VERSION ""

NS_ :

BS_:

BU_: TCU_TORQUE_CONVERTER HYDRONIC AFSS LOGBOX TCU_GWS500 TCU_RET DIAG_TOOL CTIS BC ECM_0x00 TCU ALTERNATOR CP6 CP10 _TESTER _TEMPLATE_RUx
VAL_TABLE_ HeaterWaterTemp 255 "NOT AVAILABLE" 254 "ERROR" ;
VAL_TABLE_ ___spare___ 3 "_SPARE_3" 2 "_SPARE_2" 1 "_SPARE_1" 0 "_SPARE_0" ;

BO_ 3221225472 VECTOR__INDEPENDENT_SIG_MSG: 0 Vector__XXX
 SG_ Dummy_ETC6 : 0|64@1- (1,0) [0|0] "" Vector__XXX
 SG_ Dummy_ETC7 : 0|64@1- (1,0) [0|0] "" Vector__XXX
 SG_ Dummy_ETC5 : 0|64@1- (1,0) [0|0] "" Vector__XXX
 SG_ Dummy_ETC4 : 0|64@1- (1,0) [0|0] "" Vector__XXX
 SG_ Dummy_ETC3 : 0|64@1- (1,0) [0|0] "" Vector__XXX
 SG_ Dummy_ETC2 : 0|64@1- (1,0) [0|0] "" Vector__XXX
 SG_ Dummy_ETC1 : 0|64@1- (1,0) [0|0] "" Vector__XXX
 SG_ SPN10_Low : 0|16@1+ (1,0) [0|65536] "-" Vector__XXX
 SG_ SPN9_Low : 0|16@1+ (1,0) [0|65536] "-" Vector__XXX
 SG_ SPN8_Low : 0|16@1+ (1,0) [0|65536] "-" Vector__XXX
 SG_ SPN7_Low : 0|16@1+ (1,0) [0|65536] "-" Vector__XXX
 SG_ SPN6_Low : 0|16@1+ (1,0) [0|65536] "-" Vector__XXX
 SG_ SPN5_Low : 0|16@1+ (1,0) [0|65536] "-" Vector__XXX
 SG_ SPN4_Low : 0|16@1+ (1,0) [0|65536] "-" Vector__XXX
 SG_ SPN3_Low : 0|16@1+ (1,0) [0|65536] "-" Vector__XXX
 SG_ SPN2_Low : 0|16@1+ (1,0) [0|65536] "-" Vector__XXX
 SG_ FailureModeIdentifier10 : 0|5@1+ (1,0) [0|31] "-" Vector__XXX
 SG_ FailureModeIdentifier9 : 0|5@1+ (1,0) [0|31] "-" Vector__XXX
 SG_ FailureModeIdentifier8 : 0|5@1+ (1,0) [0|31] "-" Vector__XXX
 SG_ FailureModeIdentifier7 : 0|5@1+ (1,0) [0|31] "-" Vector__XXX
 SG_ FailureModeIdentifier6 : 0|5@1+ (1,0) [0|31] "-" Vector__XXX
 SG_ FailureModeIdentifier5 : 0|5@1+ (1,0) [0|31] "-" Vector__XXX
 SG_ FailureModeIdentifier4 : 0|5@1+ (1,0) [0|31] "-" Vector__XXX
 SG_ FailureModeIdentifier3 : 0|5@1+ (1,0) [0|31] "-" Vector__XXX
 SG_ FlashRedStopLamp : 0|2@1+ (1,0) [0|3] "-" Vector__XXX
 SG_ FlashProtectLamp : 0|2@1+ (1,0) [0|3] "-" Vector__XXX
 SG_ FlashMalfuncIndicatorLamp : 0|2@1+ (1,0) [0|3] "-" Vector__XXX
 SG_ FlashAmberWarningLamp : 0|2@1+ (1,0) [0|3] "-" Vector__XXX
 SG_ MalfunctionIndicatorLampStatus : 0|2@1+ (1,0) [0|3] "-" Vector__XXX
 SG_ AmberWarningLampStatus : 0|2@1+ (1,0) [0|3] "-" Vector__XXX
 SG_ OccurenceCount1 : 0|7@1+ (1,0) [0|126] "-" Vector__XXX
 SG_ SPNConversionMethod1 : 0|1@1+ (1,0) [0|1] "-" Vector__XXX
 SG_ FailureModeIdentifier1 : 0|5@1+ (1,0) [0|31] "-" Vector__XXX
 SG_ SPN1_Low : 0|16@1+ (1,0) [0|65536] "-" Vector__XXX
 SG_ RedStopLampState : 0|2@1+ (1,0) [0|3] "-" Vector__XXX
 SG_ ProtectLampStatus : 0|2@1+ (1,0) [0|3] "-" Vector__XXX
 SG_ FailureModeIdentifier2 : 0|5@1+ (1,0) [0|31] "-" Vector__XXX
 SG_ SPNConversionMethod10 : 0|1@1+ (1,0) [0|1] "-" Vector__XXX
 SG_ SPNConversionMethod9 : 0|1@1+ (1,0) [0|1] "-" Vector__XXX
 SG_ SPNConversionMethod8 : 0|1@1+ (1,0) [0|1] "-" Vector__XXX
 SG_ SPNConversionMethod7 : 0|1@1+ (1,0) [0|1] "-" Vector__XXX
 SG_ SPNConversionMethod6 : 0|1@1+ (1,0) [0|1] "-" Vector__XXX
 SG_ SPNConversionMethod5 : 0|1@1+ (1,0) [0|1] "-" Vector__XXX
 SG_ SPNConversionMethod4 : 0|1@1+ (1,0) [0|1] "-" Vector__XXX
 SG_ SPNConversionMethod3 : 0|1@1+ (1,0) [0|1] "-" Vector__XXX
 SG_ SPNConversionMethod2 : 0|1@1+ (1,0) [0|1] "-" Vector__XXX
 SG_ OccurenceCount10 : 0|7@1+ (1,0) [0|126] "-" Vector__XXX
 SG_ OccurenceCount9 : 0|7@1+ (1,0) [0|126] "-" Vector__XXX
 SG_ OccurenceCount8 : 0|7@1+ (1,0) [0|126] "-" Vector__XXX
 SG_ OccurenceCount7 : 0|7@1+ (1,0) [0|126] "-" Vector__XXX
 SG_ OccurenceCount6 : 0|7@1+ (1,0) [0|126] "-" Vector__XXX
 SG_ OccurenceCount5 : 0|7@1+ (1,0) [0|126] "-" Vector__XXX
 SG_ OccurenceCount4 : 0|7@1+ (1,0) [0|126] "-" Vector__XXX
 SG_ OccurenceCount3 : 0|7@1+ (1,0) [0|126] "-" Vector__XXX
 SG_ OccurenceCount2 : 0|7@1+ (1,0) [0|126] "-" Vector__XXX
 SG_ SPN10_High : 0|3@1+ (1,0) [0|7] "-" Vector__XXX
 SG_ SPN9_High : 0|3@1+ (1,0) [0|7] "-" Vector__XXX
 SG_ SPN8_High : 0|3@1+ (1,0) [0|7] "-" Vector__XXX
 SG_ SPN7_High : 0|3@1+ (1,0) [0|7] "-" Vector__XXX
 SG_ SPN6_High : 0|3@1+ (1,0) [0|7] "-" Vector__XXX
 SG_ SPN5_High : 0|3@1+ (1,0) [0|7] "-" Vector__XXX
 SG_ SPN4_High : 0|3@1+ (1,0) [0|7] "-" Vector__XXX
 SG_ SPN3_High : 0|3@1+ (1,0) [0|7] "-" Vector__XXX
 SG_ SPN2_High : 0|3@1+ (1,0) [0|7] "-" Vector__XXX
 SG_ SPN1_High : 0|3@1+ (1,0) [0|7] "-" Vector__XXX
 SG_ Dummy_ECM7 : 0|64@1- (1,0) [0|0] "" Vector__XXX
 SG_ Dummy_ECM6 : 0|64@1- (1,0) [0|0] "" Vector__XXX
 SG_ Dummy_ECM5 : 0|64@1- (1,0) [0|0] "" Vector__XXX
 SG_ Dummy_ECM4 : 0|64@1- (1,0) [0|0] "" Vector__XXX
 SG_ Dummy_ECM3 : 0|64@1- (1,0) [0|0] "" Vector__XXX
 SG_ Dummy_ECM2 : 0|64@1- (1,0) [0|0] "" Vector__XXX
 SG_ Dummy_ECM1 : 0|64@1- (1,0) [0|0] "" Vector__XXX
 SG_ SPN10_Low : 0|16@1+ (1,0) [0|65536] "-" Vector__XXX
 SG_ SPN9_Low : 0|16@1+ (1,0) [0|65536] "-" Vector__XXX
 SG_ SPN8_Low : 0|16@1+ (1,0) [0|65536] "-" Vector__XXX
 SG_ SPN7_Low : 0|16@1+ (1,0) [0|65536] "-" Vector__XXX
 SG_ SPN6_Low : 0|16@1+ (1,0) [0|65536] "-" Vector__XXX
 SG_ SPN5_Low : 0|16@1+ (1,0) [0|65536] "-" Vector__XXX
 SG_ SPN4_Low : 0|16@1+ (1,0) [0|65536] "-" Vector__XXX
 SG_ SPN3_Low : 0|16@1+ (1,0) [0|65536] "-" Vector__XXX
 SG_ SPN2_Low : 0|16@1+ (1,0) [0|65536] "-" Vector__XXX
 SG_ FailureModeIdentifier10 : 0|5@1+ (1,0) [0|31] "-" Vector__XXX
 SG_ FailureModeIdentifier9 : 0|5@1+ (1,0) [0|31] "-" Vector__XXX
 SG_ FailureModeIdentifier8 : 0|5@1+ (1,0) [0|31] "-" Vector__XXX
 SG_ FailureModeIdentifier7 : 0|5@1+ (1,0) [0|31] "-" Vector__XXX
 SG_ FailureModeIdentifier6 : 0|5@1+ (1,0) [0|31] "-" Vector__XXX
 SG_ FailureModeIdentifier5 : 0|5@1+ (1,0) [0|31] "-" Vector__XXX
 SG_ FailureModeIdentifier4 : 0|5@1+ (1,0) [0|31] "-" Vector__XXX
 SG_ FailureModeIdentifier3 : 0|5@1+ (1,0) [0|31] "-" Vector__XXX
 SG_ FlashRedStopLamp : 0|2@1+ (1,0) [0|3] "-" Vector__XXX
 SG_ FlashProtectLamp : 0|2@1+ (1,0) [0|3] "-" Vector__XXX
 SG_ FlashMalfuncIndicatorLamp : 0|2@1+ (1,0) [0|3] "-" Vector__XXX
 SG_ FlashAmberWarningLamp : 0|2@1+ (1,0) [0|3] "-" Vector__XXX
 SG_ MalfunctionIndicatorLampStatus : 0|2@1+ (1,0) [0|3] "-" Vector__XXX
 SG_ AmberWarningLampStatus : 0|2@1+ (1,0) [0|3] "-" Vector__XXX
 SG_ OccurenceCount1 : 0|7@1+ (1,0) [0|126] "-" Vector__XXX
 SG_ SPNConversionMethod1 : 0|1@1+ (1,0) [0|1] "-" Vector__XXX
 SG_ FailureModeIdentifier1 : 0|5@1+ (1,0) [0|31] "-" Vector__XXX
 SG_ SPN1_Low : 0|16@1+ (1,0) [0|65536] "-" Vector__XXX
 SG_ RedStopLampState : 0|2@1+ (1,0) [0|3] "-" Vector__XXX
 SG_ ProtectLampStatus : 0|2@1+ (1,0) [0|3] "-" Vector__XXX
 SG_ FailureModeIdentifier2 : 0|5@1+ (1,0) [0|31] "-" Vector__XXX
 SG_ SPNConversionMethod10 : 0|1@1+ (1,0) [0|1] "-" Vector__XXX
 SG_ SPNConversionMethod9 : 0|1@1+ (1,0) [0|1] "-" Vector__XXX
 SG_ SPNConversionMethod8 : 0|1@1+ (1,0) [0|1] "-" Vector__XXX
 SG_ SPNConversionMethod7 : 0|1@1+ (1,0) [0|1] "-" Vector__XXX
 SG_ SPNConversionMethod6 : 0|1@1+ (1,0) [0|1] "-" Vector__XXX
 SG_ SPNConversionMethod5 : 0|1@1+ (1,0) [0|1] "-" Vector__XXX
 SG_ SPNConversionMethod4 : 0|1@1+ (1,0) [0|1] "-" Vector__XXX
 SG_ SPNConversionMethod3 : 0|1@1+ (1,0) [0|1] "-" Vector__XXX
 SG_ SPNConversionMethod2 : 0|1@1+ (1,0) [0|1] "-" Vector__XXX
 SG_ OccurenceCount10 : 0|7@1+ (1,0) [0|126] "-" Vector__XXX
 SG_ OccurenceCount9 : 0|7@1+ (1,0) [0|126] "-" Vector__XXX
 SG_ OccurenceCount8 : 0|7@1+ (1,0) [0|126] "-" Vector__XXX
 SG_ OccurenceCount7 : 0|7@1+ (1,0) [0|126] "-" Vector__XXX
 SG_ OccurenceCount6 : 0|7@1+ (1,0) [0|126] "-" Vector__XXX
 SG_ OccurenceCount5 : 0|7@1+ (1,0) [0|126] "-" Vector__XXX
 SG_ OccurenceCount4 : 0|7@1+ (1,0) [0|126] "-" Vector__XXX
 SG_ OccurenceCount3 : 0|7@1+ (1,0) [0|126] "-" Vector__XXX
 SG_ OccurenceCount2 : 0|7@1+ (1,0) [0|126] "-" Vector__XXX
 SG_ SPN10_High : 0|3@1+ (1,0) [0|7] "-" Vector__XXX
 SG_ SPN9_High : 0|3@1+ (1,0) [0|7] "-" Vector__XXX
 SG_ SPN8_High : 0|3@1+ (1,0) [0|7] "-" Vector__XXX
 SG_ SPN7_High : 0|3@1+ (1,0) [0|7] "-" Vector__XXX
 SG_ SPN6_High : 0|3@1+ (1,0) [0|7] "-" Vector__XXX
 SG_ SPN5_High : 0|3@1+ (1,0) [0|7] "-" Vector__XXX
 SG_ SPN4_High : 0|3@1+ (1,0) [0|7] "-" Vector__XXX
 SG_ SPN3_High : 0|3@1+ (1,0) [0|7] "-" Vector__XXX
 SG_ SPN2_High : 0|3@1+ (1,0) [0|7] "-" Vector__XXX
 SG_ SPN1_High : 0|3@1+ (1,0) [0|7] "-" Vector__XXX

BO_ 2565603072 _DM1_MULTI_ECM: 8 ECM_0x00
 SG_ Count : 0|8@1+ (1,0) [0|0] ""  BC
 SG_ SPN10_Low : 328|16@1+ (1,0) [0|65536] "-"  BC
 SG_ SPN9_Low : 296|16@1+ (1,0) [0|65536] "-"  BC
 SG_ SPN8_Low : 264|16@1+ (1,0) [0|65536] "-"  BC
 SG_ SPN7_Low : 232|16@1+ (1,0) [0|65536] "-"  BC
 SG_ SPN6_Low : 200|16@1+ (1,0) [0|65536] "-"  BC
 SG_ SPN5_Low : 152|16@1+ (1,0) [0|65536] "-"  BC
 SG_ SPN4_Low : 120|16@1+ (1,0) [0|65536] "-"  BC
 SG_ SPN3_Low : 88|16@1+ (1,0) [0|65536] "-"  BC
 SG_ SPN2_Low : 56|16@1+ (1,0) [0|65536] "-"  BC
 SG_ FailureModeIdentifier10 : 312|5@1+ (1,0) [0|31] "-"  BC
 SG_ FailureModeIdentifier9 : 280|5@1+ (1,0) [0|31] "-"  BC
 SG_ FailureModeIdentifier8 : 248|5@1+ (1,0) [0|31] "-"  BC
 SG_ FailureModeIdentifier7 : 216|5@1+ (1,0) [0|31] "-"  BC
 SG_ FailureModeIdentifier6 : 184|5@1+ (1,0) [0|31] "-"  BC
 SG_ FailureModeIdentifier5 : 168|5@1+ (1,0) [0|31] "-"  BC
 SG_ FailureModeIdentifier4 : 136|5@1+ (1,0) [0|31] "-"  BC
 SG_ FailureModeIdentifier3 : 104|5@1+ (1,0) [0|31] "-"  BC
 SG_ FlashRedStopLamp : 20|2@1+ (1,0) [0|3] "-"  BC
 SG_ FlashProtectLamp : 16|2@1+ (1,0) [0|3] "-"  BC
 SG_ FlashMalfuncIndicatorLamp : 22|2@1+ (1,0) [0|3] "-"  BC
 SG_ FlashAmberWarningLamp : 18|2@1+ (1,0) [0|3] "-"  BC
 SG_ MalfunctionIndicatorLampStatus : 14|2@1+ (1,0) [0|3] "-"  BC
 SG_ AmberWarningLampStatus : 10|2@1+ (1,0) [0|3] "-"  BC
 SG_ OccurenceCount1 : 48|7@1+ (1,0) [0|126] "-"  BC
 SG_ SPNConversionMethod1 : 55|1@1+ (1,0) [0|1] "-"  BC
 SG_ FailureModeIdentifier1 : 40|5@1+ (1,0) [0|31] "-"  BC
 SG_ SPN1_Low : 24|16@1+ (1,0) [0|65536] "-"  BC
 SG_ RedStopLampState : 12|2@1+ (1,0) [0|3] "-"  BC
 SG_ ProtectLampStatus : 8|2@1+ (1,0) [0|3] "-"  BC
 SG_ FailureModeIdentifier2 : 72|5@1+ (1,0) [0|31] "-"  BC
 SG_ SPNConversionMethod10 : 327|1@1+ (1,0) [0|1] "-"  BC
 SG_ SPNConversionMethod9 : 295|1@1+ (1,0) [0|1] "-"  BC
 SG_ SPNConversionMethod8 : 263|1@1+ (1,0) [0|1] "-"  BC
 SG_ SPNConversionMethod7 : 231|1@1+ (1,0) [0|1] "-"  BC
 SG_ SPNConversionMethod6 : 199|1@1+ (1,0) [0|1] "-"  BC
 SG_ SPNConversionMethod5 : 183|1@1+ (1,0) [0|1] "-"  BC
 SG_ SPNConversionMethod4 : 151|1@1+ (1,0) [0|1] "-"  BC
 SG_ SPNConversionMethod3 : 119|1@1+ (1,0) [0|1] "-"  BC
 SG_ SPNConversionMethod2 : 87|1@1+ (1,0) [0|1] "-"  BC
 SG_ OccurenceCount10 : 320|7@1+ (1,0) [0|126] "-"  BC
 SG_ OccurenceCount9 : 288|7@1+ (1,0) [0|126] "-"  BC
 SG_ OccurenceCount8 : 256|7@1+ (1,0) [0|126] "-"  BC
 SG_ OccurenceCount7 : 224|7@1+ (1,0) [0|126] "-"  BC
 SG_ OccurenceCount6 : 192|7@1+ (1,0) [0|126] "-"  BC
 SG_ OccurenceCount5 : 176|7@1+ (1,0) [0|126] "-"  BC
 SG_ OccurenceCount4 : 144|7@1+ (1,0) [0|126] "-"  BC
 SG_ OccurenceCount3 : 112|7@1+ (1,0) [0|126] "-"  BC
 SG_ OccurenceCount2 : 80|7@1+ (1,0) [0|126] "-"  BC
 SG_ SPN10_High : 317|3@1+ (1,0) [0|7] "-"  BC
 SG_ SPN9_High : 285|3@1+ (1,0) [0|7] "-"  BC
 SG_ SPN8_High : 253|3@1+ (1,0) [0|7] "-"  BC
 SG_ SPN7_High : 221|3@1+ (1,0) [0|7] "-"  BC
 SG_ SPN6_High : 189|3@1+ (1,0) [0|7] "-"  BC
 SG_ SPN5_High : 173|3@1+ (1,0) [0|7] "-"  BC
 SG_ SPN4_High : 141|3@1+ (1,0) [0|7] "-"  BC
 SG_ SPN3_High : 109|3@1+ (1,0) [0|7] "-"  BC
 SG_ SPN2_High : 77|3@1+ (1,0) [0|7] "-"  BC
 SG_ SPN1_High : 45|3@1+ (1,0) [0|7] "-"  BC

BO_ 2565603075 _DM1_MULTI_ETC: 8 TCU
 SG_ Count : 0|8@1+ (1,0) [0|0] ""  BC
 SG_ SPN10_Low : 328|16@1+ (1,0) [0|65536] "-"  BC
 SG_ SPN9_Low : 296|16@1+ (1,0) [0|65536] "-"  BC
 SG_ SPN8_Low : 264|16@1+ (1,0) [0|65536] "-"  BC
 SG_ SPN7_Low : 232|16@1+ (1,0) [0|65536] "-"  BC
 SG_ SPN6_Low : 200|16@1+ (1,0) [0|65536] "-"  BC
 SG_ SPN5_Low : 152|16@1+ (1,0) [0|65536] "-"  BC
 SG_ SPN4_Low : 120|16@1+ (1,0) [0|65536] "-"  BC
 SG_ SPN3_Low : 88|16@1+ (1,0) [0|65536] "-"  BC
 SG_ SPN2_Low : 56|16@1+ (1,0) [0|65536] "-"  BC
 SG_ FailureModeIdentifier10 : 312|5@1+ (1,0) [0|31] "-"  BC
 SG_ FailureModeIdentifier9 : 280|5@1+ (1,0) [0|31] "-"  BC
 SG_ FailureModeIdentifier8 : 248|5@1+ (1,0) [0|31] "-"  BC
 SG_ FailureModeIdentifier7 : 216|5@1+ (1,0) [0|31] "-"  BC
 SG_ FailureModeIdentifier6 : 184|5@1+ (1,0) [0|31] "-"  BC
 SG_ FailureModeIdentifier5 : 168|5@1+ (1,0) [0|31] "-"  BC
 SG_ FailureModeIdentifier4 : 136|5@1+ (1,0) [0|31] "-"  BC
 SG_ FailureModeIdentifier3 : 104|5@1+ (1,0) [0|31] "-"  BC
 SG_ FlashRedStopLamp : 20|2@1+ (1,0) [0|3] "-"  BC
 SG_ FlashProtectLamp : 16|2@1+ (1,0) [0|3] "-"  BC
 SG_ FlashMalfuncIndicatorLamp : 22|2@1+ (1,0) [0|3] "-"  BC
 SG_ FlashAmberWarningLamp : 18|2@1+ (1,0) [0|3] "-"  BC
 SG_ MalfunctionIndicatorLampStatus : 14|2@1+ (1,0) [0|3] "-"  BC
 SG_ AmberWarningLampStatus : 10|2@1+ (1,0) [0|3] "-"  BC
 SG_ OccurenceCount1 : 48|7@1+ (1,0) [0|126] "-"  BC
 SG_ SPNConversionMethod1 : 55|1@1+ (1,0) [0|1] "-"  BC
 SG_ FailureModeIdentifier1 : 40|5@1+ (1,0) [0|31] "-"  BC
 SG_ SPN1_Low : 24|16@1+ (1,0) [0|65536] "-"  BC
 SG_ RedStopLampState : 12|2@1+ (1,0) [0|3] "-"  BC
 SG_ ProtectLampStatus : 8|2@1+ (1,0) [0|3] "-"  BC
 SG_ FailureModeIdentifier2 : 72|5@1+ (1,0) [0|31] "-"  BC
 SG_ SPNConversionMethod10 : 327|1@1+ (1,0) [0|1] "-"  BC
 SG_ SPNConversionMethod9 : 295|1@1+ (1,0) [0|1] "-"  BC
 SG_ SPNConversionMethod8 : 263|1@1+ (1,0) [0|1] "-"  BC
 SG_ SPNConversionMethod7 : 231|1@1+ (1,0) [0|1] "-"  BC
 SG_ SPNConversionMethod6 : 199|1@1+ (1,0) [0|1] "-"  BC
 SG_ SPNConversionMethod5 : 183|1@1+ (1,0) [0|1] "-"  BC
 SG_ SPNConversionMethod4 : 151|1@1+ (1,0) [0|1] "-"  BC
 SG_ SPNConversionMethod3 : 119|1@1+ (1,0) [0|1] "-"  BC
 SG_ SPNConversionMethod2 : 87|1@1+ (1,0) [0|1] "-"  BC
 SG_ OccurenceCount10 : 320|7@1+ (1,0) [0|126] "-"  BC
 SG_ OccurenceCount9 : 288|7@1+ (1,0) [0|126] "-"  BC
 SG_ OccurenceCount8 : 256|7@1+ (1,0) [0|126] "-"  BC
 SG_ OccurenceCount7 : 224|7@1+ (1,0) [0|126] "-"  BC
 SG_ OccurenceCount6 : 192|7@1+ (1,0) [0|126] "-"  BC
 SG_ OccurenceCount5 : 176|7@1+ (1,0) [0|126] "-"  BC
 SG_ OccurenceCount4 : 144|7@1+ (1,0) [0|126] "-"  BC
 SG_ OccurenceCount3 : 112|7@1+ (1,0) [0|126] "-"  BC
 SG_ OccurenceCount2 : 80|7@1+ (1,0) [0|126] "-"  BC
 SG_ SPN10_High : 317|3@1+ (1,0) [0|7] "-"  BC
 SG_ SPN9_High : 285|3@1+ (1,0) [0|7] "-"  BC
 SG_ SPN8_High : 253|3@1+ (1,0) [0|7] "-"  BC
 SG_ SPN7_High : 221|3@1+ (1,0) [0|7] "-"  BC
 SG_ SPN6_High : 189|3@1+ (1,0) [0|7] "-"  BC
 SG_ SPN5_High : 173|3@1+ (1,0) [0|7] "-"  BC
 SG_ SPN4_High : 141|3@1+ (1,0) [0|7] "-"  BC
 SG_ SPN3_High : 109|3@1+ (1,0) [0|7] "-"  BC
 SG_ SPN2_High : 77|3@1+ (1,0) [0|7] "-"  BC
 SG_ SPN1_High : 45|3@1+ (1,0) [0|7] "-"  BC

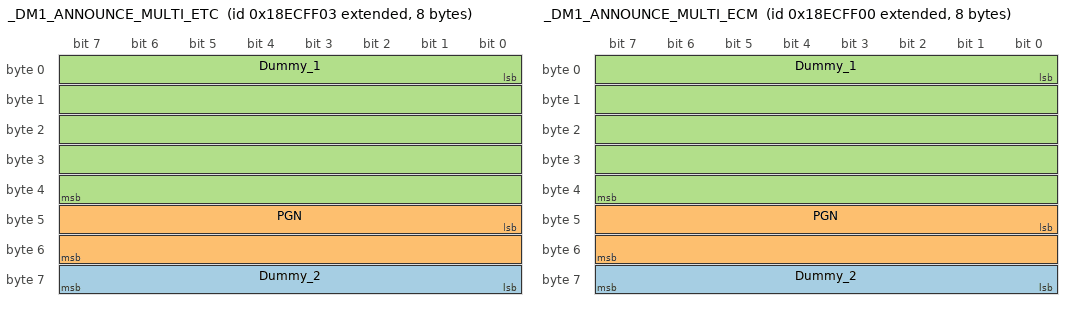
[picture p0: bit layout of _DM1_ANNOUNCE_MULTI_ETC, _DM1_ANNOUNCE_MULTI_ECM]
BO_ 2565668611 _DM1_ANNOUNCE_MULTI_ETC: 8 TCU
 SG_ Dummy_2 : 56|8@1- (1,0) [0|0] ""  BC
 SG_ PGN : 40|16@1- (1,0) [0|1] ""  BC
 SG_ Dummy_1 : 0|40@1- (1,0) [0|0] ""  BC

BO_ 2565668608 _DM1_ANNOUNCE_MULTI_ECM: 8 ECM_0x00
 SG_ Dummy_2 : 56|8@1- (1,0) [0|0] ""  BC
 SG_ PGN : 40|16@1- (1,0) [0|1] ""  BC
 SG_ Dummy_1 : 0|40@1- (1,0) [0|0] ""  BC

BO_ 2566834691 _DM1_ETC: 8 TCU
 SG_ SPN10_Low : 320|16@1+ (1,0) [0|65536] "-"  BC
 SG_ SPN9_Low : 288|16@1+ (1,0) [0|65536] "-"  BC
 SG_ SPN8_Low : 256|16@1+ (1,0) [0|65536] "-"  BC
 SG_ SPN7_Low : 224|16@1+ (1,0) [0|65536] "-"  BC
 SG_ SPN6_Low : 192|16@1+ (1,0) [0|65536] "-"  BC
 SG_ SPN5_Low : 144|16@1+ (1,0) [0|65536] "-"  BC
 SG_ SPN4_Low : 112|16@1+ (1,0) [0|65536] "-"  BC
 SG_ SPN3_Low : 80|16@1+ (1,0) [0|65536] "-"  BC
 SG_ SPN2_Low : 48|16@1+ (1,0) [0|65536] "-"  BC
 SG_ FailureModeIdentifier10 : 304|5@1+ (1,0) [0|31] "-"  BC
 SG_ FailureModeIdentifier9 : 272|5@1+ (1,0) [0|31] "-"  BC
 SG_ FailureModeIdentifier8 : 240|5@1+ (1,0) [0|31] "-"  BC
 SG_ FailureModeIdentifier7 : 208|5@1+ (1,0) [0|31] "-"  BC
 SG_ FailureModeIdentifier6 : 176|5@1+ (1,0) [0|31] "-"  BC
 SG_ FailureModeIdentifier5 : 160|5@1+ (1,0) [0|31] "-"  BC
 SG_ FailureModeIdentifier4 : 128|5@1+ (1,0) [0|31] "-"  BC
 SG_ FailureModeIdentifier3 : 96|5@1+ (1,0) [0|31] "-"  BC
 SG_ FlashRedStopLamp : 12|2@1+ (1,0) [0|3] "-"  BC
 SG_ FlashProtectLamp : 8|2@1+ (1,0) [0|3] "-"  BC
 SG_ FlashMalfuncIndicatorLamp : 14|2@1+ (1,0) [0|3] "-"  BC
 SG_ FlashAmberWarningLamp : 10|2@1+ (1,0) [0|3] "-"  BC
 SG_ MalfunctionIndicatorLampStatus : 6|2@1+ (1,0) [0|3] "-"  BC
 SG_ AmberWarningLampStatus : 2|2@1+ (1,0) [0|3] "-"  BC
 SG_ OccurenceCount1 : 40|7@1+ (1,0) [0|126] "-"  BC
 SG_ SPNConversionMethod1 : 47|1@1+ (1,0) [0|1] "-"  BC
 SG_ FailureModeIdentifier1 : 32|5@1+ (1,0) [0|31] "-"  BC
 SG_ SPN1_Low : 16|16@1+ (1,0) [0|65536] "-"  BC
 SG_ RedStopLampState : 4|2@1+ (1,0) [0|3] "-"  BC
 SG_ ProtectLampStatus : 0|2@1+ (1,0) [0|3] "-"  BC
 SG_ FailureModeIdentifier2 : 64|5@1+ (1,0) [0|31] "-"  BC
 SG_ SPNConversionMethod10 : 319|1@1+ (1,0) [0|1] "-"  BC
 SG_ SPNConversionMethod9 : 287|1@1+ (1,0) [0|1] "-"  BC
 SG_ SPNConversionMethod8 : 255|1@1+ (1,0) [0|1] "-"  BC
 SG_ SPNConversionMethod7 : 223|1@1+ (1,0) [0|1] "-"  BC
 SG_ SPNConversionMethod6 : 191|1@1+ (1,0) [0|1] "-"  BC
 SG_ SPNConversionMethod5 : 175|1@1+ (1,0) [0|1] "-"  BC
 SG_ SPNConversionMethod4 : 143|1@1+ (1,0) [0|1] "-"  BC
 SG_ SPNConversionMethod3 : 111|1@1+ (1,0) [0|1] "-"  BC
 SG_ SPNConversionMethod2 : 79|1@1+ (1,0) [0|1] "-"  BC
 SG_ OccurenceCount10 : 312|7@1+ (1,0) [0|126] "-"  BC
 SG_ OccurenceCount9 : 280|7@1+ (1,0) [0|126] "-"  BC
 SG_ OccurenceCount8 : 248|7@1+ (1,0) [0|126] "-"  BC
 SG_ OccurenceCount7 : 216|7@1+ (1,0) [0|126] "-"  BC
 SG_ OccurenceCount6 : 184|7@1+ (1,0) [0|126] "-"  BC
 SG_ OccurenceCount5 : 168|7@1+ (1,0) [0|126] "-"  BC
 SG_ OccurenceCount4 : 136|7@1+ (1,0) [0|126] "-"  BC
 SG_ OccurenceCount3 : 104|7@1+ (1,0) [0|126] "-"  BC
 SG_ OccurenceCount2 : 72|7@1+ (1,0) [0|126] "-"  BC
 SG_ SPN10_High : 309|3@1+ (1,0) [0|7] "-"  BC
 SG_ SPN9_High : 277|3@1+ (1,0) [0|7] "-"  BC
 SG_ SPN8_High : 245|3@1+ (1,0) [0|7] "-"  BC
 SG_ SPN7_High : 213|3@1+ (1,0) [0|7] "-"  BC
 SG_ SPN6_High : 181|3@1+ (1,0) [0|7] "-"  BC
 SG_ SPN5_High : 165|3@1+ (1,0) [0|7] "-"  BC
 SG_ SPN4_High : 133|3@1+ (1,0) [0|7] "-"  BC
 SG_ SPN3_High : 101|3@1+ (1,0) [0|7] "-"  BC
 SG_ SPN2_High : 69|3@1+ (1,0) [0|7] "-"  BC
 SG_ SPN1_High : 37|3@1+ (1,0) [0|7] "-"  BC

BO_ 2566834688 _DM1_ECM: 8 ECM_0x00
 SG_ SPN10_Low : 320|16@1+ (1,0) [0|65536] "-"  BC,LOGBOX
 SG_ SPN9_Low : 288|16@1+ (1,0) [0|65536] "-"  BC,LOGBOX
 SG_ SPN8_Low : 256|16@1+ (1,0) [0|65536] "-"  BC,LOGBOX
 SG_ SPN7_Low : 224|16@1+ (1,0) [0|65536] "-"  BC,LOGBOX
 SG_ SPN6_Low : 192|16@1+ (1,0) [0|65536] "-"  BC,LOGBOX
 SG_ SPN5_Low : 144|16@1+ (1,0) [0|65536] "-"  BC,LOGBOX
 SG_ SPN4_Low : 112|16@1+ (1,0) [0|65536] "-"  BC,LOGBOX
 SG_ SPN3_Low : 80|16@1+ (1,0) [0|65536] "-"  BC,LOGBOX
 SG_ SPN2_Low : 48|16@1+ (1,0) [0|65536] "-"  BC,LOGBOX
 SG_ FailureModeIdentifier10 : 304|5@1+ (1,0) [0|31] "-"  BC,LOGBOX
 SG_ FailureModeIdentifier9 : 272|5@1+ (1,0) [0|31] "-"  BC,LOGBOX
 SG_ FailureModeIdentifier8 : 240|5@1+ (1,0) [0|31] "-"  BC,LOGBOX
 SG_ FailureModeIdentifier7 : 208|5@1+ (1,0) [0|31] "-"  BC,LOGBOX
 SG_ FailureModeIdentifier6 : 176|5@1+ (1,0) [0|31] "-"  BC,LOGBOX
 SG_ FailureModeIdentifier5 : 160|5@1+ (1,0) [0|31] "-"  BC,LOGBOX
 SG_ FailureModeIdentifier4 : 128|5@1+ (1,0) [0|31] "-"  BC,LOGBOX
 SG_ FailureModeIdentifier3 : 96|5@1+ (1,0) [0|31] "-"  BC,LOGBOX
 SG_ FlashRedStopLamp : 12|2@1+ (1,0) [0|3] "-"  BC,LOGBOX
 SG_ FlashProtectLamp : 8|2@1+ (1,0) [0|3] "-"  BC,LOGBOX
 SG_ FlashMalfuncIndicatorLamp : 14|2@1+ (1,0) [0|3] "-"  BC,LOGBOX
 SG_ FlashAmberWarningLamp : 10|2@1+ (1,0) [0|3] "-"  BC,LOGBOX
 SG_ MalfunctionIndicatorLampStatus : 6|2@1+ (1,0) [0|3] "-"  BC,LOGBOX
 SG_ AmberWarningLampStatus : 2|2@1+ (1,0) [0|3] "-"  BC,LOGBOX
 SG_ OccurenceCount1 : 40|7@1+ (1,0) [0|126] "-"  BC,LOGBOX
 SG_ SPNConversionMethod1 : 47|1@1+ (1,0) [0|1] "-"  BC,LOGBOX
 SG_ FailureModeIdentifier1 : 32|5@1+ (1,0) [0|31] "-"  BC,LOGBOX
 SG_ SPN1_Low : 16|16@1+ (1,0) [0|65536] "-"  BC,LOGBOX
 SG_ RedStopLampState : 4|2@1+ (1,0) [0|3] "-"  BC,LOGBOX
 SG_ ProtectLampStatus : 0|2@1+ (1,0) [0|3] "-"  BC,LOGBOX
 SG_ FailureModeIdentifier2 : 64|5@1+ (1,0) [0|31] "-"  BC,LOGBOX
 SG_ SPNConversionMethod10 : 319|1@1+ (1,0) [0|1] "-"  BC,LOGBOX
 SG_ SPNConversionMethod9 : 287|1@1+ (1,0) [0|1] "-"  BC,LOGBOX
 SG_ SPNConversionMethod8 : 255|1@1+ (1,0) [0|1] "-"  BC,LOGBOX
 SG_ SPNConversionMethod7 : 223|1@1+ (1,0) [0|1] "-"  BC,LOGBOX
 SG_ SPNConversionMethod6 : 191|1@1+ (1,0) [0|1] "-"  BC,LOGBOX
 SG_ SPNConversionMethod5 : 175|1@1+ (1,0) [0|1] "-"  BC,LOGBOX
 SG_ SPNConversionMethod4 : 143|1@1+ (1,0) [0|1] "-"  BC,LOGBOX
 SG_ SPNConversionMethod3 : 111|1@1+ (1,0) [0|1] "-"  BC,LOGBOX
 SG_ SPNConversionMethod2 : 79|1@1+ (1,0) [0|1] "-"  BC,LOGBOX
 SG_ OccurenceCount10 : 312|7@1+ (1,0) [0|126] "-"  BC,LOGBOX
 SG_ OccurenceCount9 : 280|7@1+ (1,0) [0|126] "-"  BC,LOGBOX
 SG_ OccurenceCount8 : 248|7@1+ (1,0) [0|126] "-"  BC,LOGBOX
 SG_ OccurenceCount7 : 216|7@1+ (1,0) [0|126] "-"  BC,LOGBOX
 SG_ OccurenceCount6 : 184|7@1+ (1,0) [0|126] "-"  BC,LOGBOX
 SG_ OccurenceCount5 : 168|7@1+ (1,0) [0|126] "-"  BC,LOGBOX
 SG_ OccurenceCount4 : 136|7@1+ (1,0) [0|126] "-"  BC,LOGBOX
 SG_ OccurenceCount3 : 104|7@1+ (1,0) [0|126] "-"  BC,LOGBOX
 SG_ OccurenceCount2 : 72|7@1+ (1,0) [0|126] "-"  BC,LOGBOX
 SG_ SPN10_High : 309|3@1+ (1,0) [0|7] "-"  BC,LOGBOX
 SG_ SPN9_High : 277|3@1+ (1,0) [0|7] "-"  BC,LOGBOX
 SG_ SPN8_High : 245|3@1+ (1,0) [0|7] "-"  BC,LOGBOX
 SG_ SPN7_High : 213|3@1+ (1,0) [0|7] "-"  BC,LOGBOX
 SG_ SPN6_High : 181|3@1+ (1,0) [0|7] "-"  BC,LOGBOX
 SG_ SPN5_High : 165|3@1+ (1,0) [0|7] "-"  BC,LOGBOX
 SG_ SPN4_High : 133|3@1+ (1,0) [0|7] "-"  BC,LOGBOX
 SG_ SPN3_High : 101|3@1+ (1,0) [0|7] "-"  BC,LOGBOX
 SG_ SPN2_High : 69|3@1+ (1,0) [0|7] "-"  BC,LOGBOX
 SG_ SPN1_High : 37|3@1+ (1,0) [0|7] "-"  BC,LOGBOX

BO_ 2633934618 ALT_TEMPERATURES: 8 ALTERNATOR
 SG_ Alt_RegulatorTemperature : 24|8@1+ (1,-40) [-40|210] "°C"  LOGBOX
 SG_ Alt_InternalTemperature : 32|16@1+ (1,-40) [-40|210] "°C"  LOGBOX

BO_ 2566846234 ALT_VOLTAGE: 8 ALTERNATOR
 SG_ Alt_Voltage_1 : 48|16@1+ (0.05,0) [0|32] "Volt"  LOGBOX
 SG_ Alt_BatteryVoltage_1 : 16|16@1+ (0.05,0) [0|32] "Volt"  LOGBOX

BO_ 2566905882 ALT_PROPRIETARY_5: 8 ALTERNATOR
 SG_ Alt_SoftwareVersion : 48|8@1+ (1,0) [0|255] "-"  LOGBOX
 SG_ Alt_HardwareVersion : 32|8@1+ (1,0) [0|255] "-"  LOGBOX

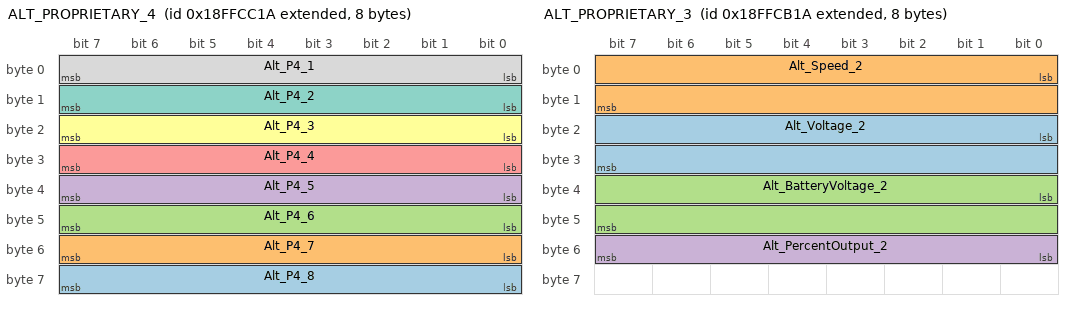
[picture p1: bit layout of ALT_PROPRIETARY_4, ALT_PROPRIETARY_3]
BO_ 2566900762 ALT_PROPRIETARY_4: 8 ALTERNATOR
 SG_ Alt_P4_8 : 56|8@1+ (1,0) [0|255] "-"  LOGBOX
 SG_ Alt_P4_7 : 48|8@1+ (1,0) [0|255] "-"  LOGBOX
 SG_ Alt_P4_6 : 40|8@1+ (1,0) [0|255] "-"  LOGBOX
 SG_ Alt_P4_5 : 32|8@1+ (1,0) [0|255] "-"  LOGBOX
 SG_ Alt_P4_4 : 24|8@1+ (1,0) [0|255] "-"  LOGBOX
 SG_ Alt_P4_3 : 16|8@1+ (1,0) [0|255] "-"  LOGBOX
 SG_ Alt_P4_2 : 8|8@1+ (1,0) [0|255] "-"  LOGBOX
 SG_ Alt_P4_1 : 0|8@1+ (1,0) [0|255] "-"  LOGBOX

BO_ 2566900506 ALT_PROPRIETARY_3: 8 ALTERNATOR
 SG_ Alt_Voltage_2 : 16|16@1+ (0.05,0) [0|3200] "Volt"  LOGBOX
 SG_ Alt_Speed_2 : 0|16@1+ (0.5,0) [0|32000] "rpm"  LOGBOX
 SG_ Alt_BatteryVoltage_2 : 32|16@1+ (0.05,0) [0|3200] "Volt"  LOGBOX
 SG_ Alt_PercentOutput_2 : 48|8@1+ (1,0) [0|100] "%"  LOGBOX

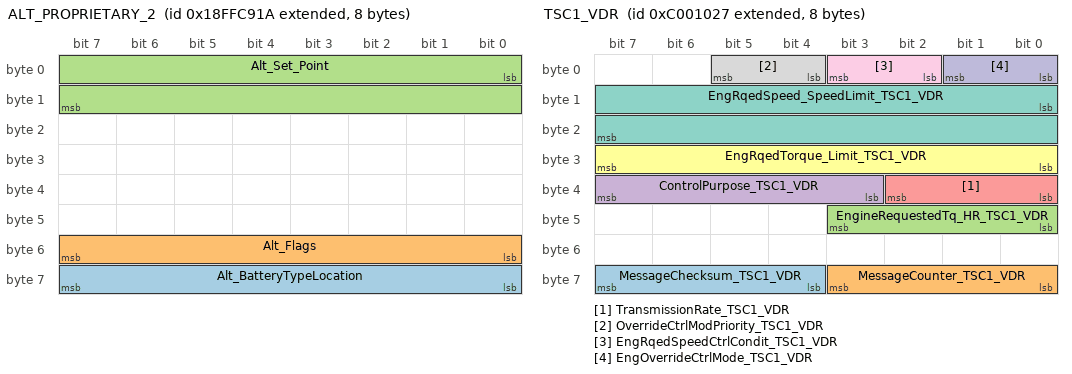
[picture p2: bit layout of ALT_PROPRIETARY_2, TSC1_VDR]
BO_ 2566899994 ALT_PROPRIETARY_2: 8 ALTERNATOR
 SG_ Alt_BatteryTypeLocation : 56|8@1+ (1,0) [1|4] "-"  LOGBOX
 SG_ Alt_Flags : 48|8@1+ (1,0) [0|255] "-"  LOGBOX
 SG_ Alt_Set_Point : 0|16@1+ (0.05,0) [0|0] "V"  LOGBOX

BO_ 2348814375 TSC1_VDR: 8 BC
 SG_ MessageChecksum_TSC1_VDR : 60|4@1+ (1,0) [0|15] "unit"  LOGBOX,TCU,TCU_RET
 SG_ MessageCounter_TSC1_VDR : 56|4@1+ (1,0) [0|15] "-"  LOGBOX,TCU,TCU_RET
 SG_ EngineRequestedTq_HR_TSC1_VDR : 40|4@1+ (1,0) [0|15] "-"  LOGBOX,TCU,TCU_RET
 SG_ ControlPurpose_TSC1_VDR : 35|5@1+ (1,0) [0|31] "-"  LOGBOX,TCU,TCU_RET
 SG_ TransmissionRate_TSC1_VDR : 32|3@1+ (1,0) [0|7] "-"  LOGBOX,TCU,TCU_RET
 SG_ EngRqedTorque_Limit_TSC1_VDR : 24|8@1+ (1,-125) [-125|125] "%"  LOGBOX,TCU,TCU_RET
 SG_ EngRqedSpeed_SpeedLimit_TSC1_VDR : 8|16@1+ (0.125,0) [0|8031.875] "rpm"  LOGBOX,TCU,TCU_RET
 SG_ OverrideCtrlModPriority_TSC1_VDR : 4|2@1+ (1,0) [0|3] "-"  LOGBOX,TCU,TCU_RET
 SG_ EngRqedSpeedCtrlCondit_TSC1_VDR : 2|2@1+ (1,0) [0|3] "-"  LOGBOX,TCU,TCU_RET
 SG_ EngOverrideCtrlMode_TSC1_VDR : 0|2@1+ (1,0) [0|3] "-"  LOGBOX,TCU,TCU_RET

BO_ 2566824960 ET2: 8 ECM_0x00
 SG_ EngineEcuTemp : 16|16@1+ (0.03125,-273) [-273|1734.96875] "-"  LOGBOX,BC,ECM_0x00

BO_ 2566848545 BC2EDC1: 8 BC
 SG_ VehicleSpeedLimit : 16|8@1+ (1,0) [0|250] "km/h"  LOGBOX,ECM_0x00

BO_ 2566809413 WTA_ClimateControlConfiguration: 8 HYDRONIC
 SG_ HeaterMaximumOutputPower : 0|16@1- (2,0) [0|131070] "W"  LOGBOX

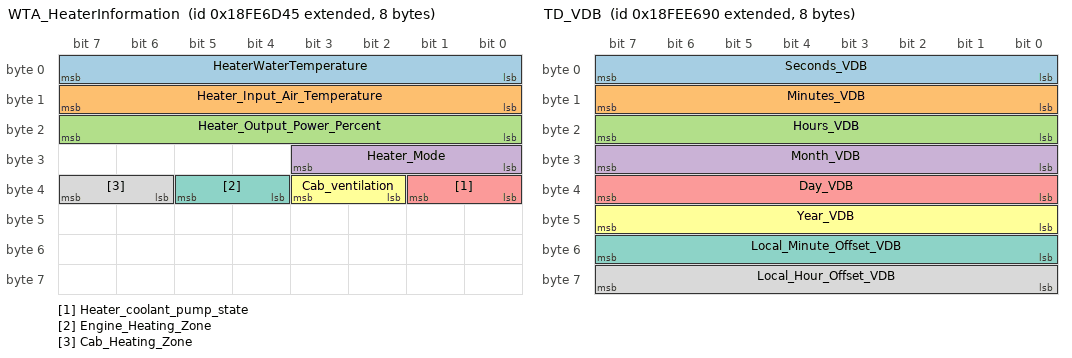
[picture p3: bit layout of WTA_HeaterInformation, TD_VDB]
BO_ 2566810949 WTA_HeaterInformation: 8 HYDRONIC
 SG_ HeaterWaterTemperature : 0|8@1+ (1,-40) [-40|210] "°C"  LOGBOX
 SG_ Heater_Input_Air_Temperature : 8|8@1+ (1,-40) [-40|210] "°C"  LOGBOX
 SG_ Heater_Output_Power_Percent : 16|8@1+ (0.4,0) [0|100] "%"  LOGBOX
 SG_ Heater_Mode : 24|4@1+ (1,0) [0|15] "-"  LOGBOX
 SG_ Heater_coolant_pump_state : 32|2@1+ (1,0) [0|3] "-"  LOGBOX
 SG_ Cab_ventilation : 34|2@1+ (1,0) [0|3] "-"  LOGBOX
 SG_ Engine_Heating_Zone : 36|2@1+ (1,0) [0|3] "-"  LOGBOX
 SG_ Cab_Heating_Zone : 38|2@1+ (1,0) [0|3] "-"  LOGBOX

BO_ 2566842000 TD_VDB: 8 LOGBOX
 SG_ Seconds_VDB : 0|8@1+ (0.25,0) [0|59.75] "s"  LOGBOX,BC,HYDRONIC
 SG_ Minutes_VDB : 8|8@1+ (1,0) [0|59] "mun"  LOGBOX,BC,HYDRONIC
 SG_ Hours_VDB : 16|8@1+ (1,0) [0|23] "-"  LOGBOX,BC,HYDRONIC
 SG_ Month_VDB : 24|8@1+ (1,0) [1|12] "-"  LOGBOX,BC,HYDRONIC
 SG_ Day_VDB : 32|8@1+ (0.25,0) [0.25|31.75] "-"  LOGBOX,BC,HYDRONIC
 SG_ Year_VDB : 40|8@1+ (1,1985) [1985|2235] "-"  LOGBOX,BC,HYDRONIC
 SG_ Local_Minute_Offset_VDB : 48|8@1+ (1,-125) [-59|59] "-"  LOGBOX,BC,HYDRONIC
 SG_ Local_Hour_Offset_VDB : 56|8@1+ (1,-125) [-23|23] "-"  LOGBOX,BC,HYDRONIC

BO_ 2558590749 AFSS2MUX2: 8 AFSS
 SG_ AFSS_Zone_Fault0 : 0|2@1+ (1,0) [0|3] "-"  BC,LOGBOX,CP10,CP6
 SG_ AFSS_Zone_Fault1 : 2|2@1+ (1,0) [0|3] "-"  BC,LOGBOX,CP10,CP6
 SG_ AFSS_Zone_Fault2 : 4|2@1+ (1,0) [0|3] "-"  BC,LOGBOX,CP10,CP6
 SG_ AFSS_Zone_Fault3 : 6|2@1+ (1,0) [0|3] "-"  BC,LOGBOX,CP10,CP6
 SG_ AFSS_Zone_Fire_Alarm0 : 8|2@1+ (1,0) [0|3] "-"  BC,LOGBOX,CP10,CP6
 SG_ AFSS_Zone_Fire_Alarm1 : 10|2@1+ (1,0) [0|3] "-"  BC,LOGBOX,CP10,CP6
 SG_ AFSS_Zone_Fire_Alarm2 : 12|2@1+ (1,0) [0|3] "-"  BC,LOGBOX,CP10,CP6
 SG_ AFSS_Zone_Fire_Alarm3 : 14|2@1+ (1,0) [0|3] "-"  BC,LOGBOX,CP10,CP6
 SG_ AFSS_Voltage_Fault : 16|4@1+ (1,0) [0|15] "-"  BC,LOGBOX,CP10,CP6
 SG_ AFSS_Internal_Fault : 20|4@1+ (1,0) [0|3] "-"  BC,LOGBOX,CP10,CP6
 SG_ AFSS_Config_Error : 24|2@1+ (1,0) [0|3] "-"  BC,LOGBOX,CP10,CP6
 SG_ AFSS_Zone_inhibited : 26|2@1+ (1,0) [0|3] "-"  BC,LOGBOX,CP10,CP6
 SG_ AFSS_Self_Test : 28|2@1+ (1,0) [0|3] "-"  BC,LOGBOX,CP10,CP6
 SG_ AFSS_ContrOut0 : 32|2@1+ (1,0) [0|3] "-"  BC,LOGBOX,CP10,CP6
 SG_ AFSS_ContrOut1 : 34|2@1+ (1,0) [0|3] "-"  BC,LOGBOX,CP10,CP6
 SG_ AFSS_ContrOut2 : 36|2@1+ (1,0) [0|3] "-"  BC,LOGBOX,CP10,CP6
 SG_ AFSS_ContrOut3 : 38|2@1+ (1,0) [0|3] "-"  BC,LOGBOX,CP10,CP6
 SG_ AFSS_ContrOut4 : 40|2@1+ (1,0) [0|3] "-"  BC,LOGBOX,CP10,CP6
 SG_ AFSS_ContrOut5 : 42|2@1+ (1,0) [0|3] "-"  BC,LOGBOX,CP10,CP6
 SG_ AFSS_ContrOut6 : 44|2@1+ (1,0) [0|3] "-"  BC,LOGBOX,CP10,CP6
 SG_ AFSS_ContrOut7 : 46|2@1+ (1,0) [0|3] "-"  BC,LOGBOX,CP10,CP6
 SG_ AFSS_ExtInp0 : 48|2@1+ (1,0) [0|3] "-"  BC,LOGBOX,CP10,CP6
 SG_ AFSS_ExtInp1 : 50|2@1+ (1,0) [0|3] "-"  BC,LOGBOX,CP10,CP6
 SG_ AFSS_ExtInp2 : 52|2@1+ (1,0) [0|3] "-"  BC,LOGBOX,CP10,CP6
 SG_ AFSS_ExtInp3 : 54|2@1+ (1,0) [0|3] "-"  BC,LOGBOX,CP10,CP6
 SG_ AFSS_ExtInp4 : 56|2@1+ (1,0) [0|3] "-"  BC,LOGBOX,CP10,CP6
 SG_ AFSS_ExtInp5 : 58|2@1+ (1,0) [0|3] "-"  BC,LOGBOX,CP10,CP6
 SG_ AFSS_ExtInp6 : 60|2@1+ (1,0) [0|3] "-"  BC,LOGBOX,CP10,CP6
 SG_ AFSS_ExtInp7 : 62|2@1+ (1,0) [0|3] "-"  BC,LOGBOX,CP10,CP6
 SG_ AFSS_NotUsed : 30|2@1+ (1,0) [0|1] "-"  BC,LOGBOX,CP10,CP6

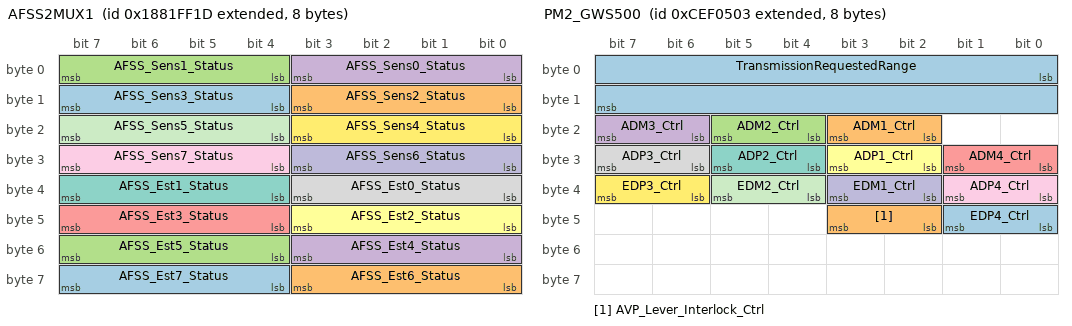
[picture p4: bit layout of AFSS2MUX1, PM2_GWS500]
BO_ 2558656285 AFSS2MUX1: 8 AFSS
 SG_ AFSS_Est7_Status : 60|4@1+ (1,0) [0|15] "-"  BC,LOGBOX,CP10,CP6
 SG_ AFSS_Est6_Status : 56|4@1+ (1,0) [0|15] "-"  BC,LOGBOX,CP10,CP6
 SG_ AFSS_Est5_Status : 52|4@1+ (1,0) [0|15] "-"  BC,LOGBOX,CP10,CP6
 SG_ AFSS_Est4_Status : 48|4@1+ (1,0) [0|15] "-"  BC,LOGBOX,CP10,CP6
 SG_ AFSS_Est3_Status : 44|4@1+ (1,0) [0|15] "-"  BC,LOGBOX,CP10,CP6
 SG_ AFSS_Est2_Status : 40|4@1+ (1,0) [0|15] "-"  BC,LOGBOX,CP10,CP6
 SG_ AFSS_Est1_Status : 36|4@1+ (1,0) [0|15] "-"  BC,LOGBOX,CP10,CP6
 SG_ AFSS_Est0_Status : 32|4@1+ (1,0) [0|15] "-"  BC,LOGBOX,CP10,CP6
 SG_ AFSS_Sens7_Status : 28|4@1+ (1,0) [0|15] "-"  BC,LOGBOX,CP10,CP6
 SG_ AFSS_Sens6_Status : 24|4@1+ (1,0) [0|15] "-"  BC,LOGBOX,CP10,CP6
 SG_ AFSS_Sens5_Status : 20|4@1+ (1,0) [0|15] "-"  BC,LOGBOX,CP10,CP6
 SG_ AFSS_Sens4_Status : 16|4@1+ (1,0) [0|15] "-"  BC,LOGBOX,CP10,CP6
 SG_ AFSS_Sens3_Status : 12|4@1+ (1,0) [0|15] "-"  BC,LOGBOX,CP10,CP6
 SG_ AFSS_Sens2_Status : 8|4@1+ (1,0) [0|15] "-"  BC,LOGBOX,CP10,CP6
 SG_ AFSS_Sens1_Status : 4|4@1+ (1,0) [0|15] "-"  BC,LOGBOX,CP10,CP6
 SG_ AFSS_Sens0_Status : 0|4@1+ (1,0) [0|15] "-"  BC,LOGBOX,CP10,CP6

BO_ 2364474627 PM2_GWS500: 8 TCU
 SG_ TransmissionRequestedRange : 0|16@1+ (1,0) [0|65536] "-"  LOGBOX,TCU_GWS500
 SG_ ADM1_Ctrl : 18|2@1+ (1,0) [0|3] "-"  LOGBOX,TCU_GWS500
 SG_ ADM2_Ctrl : 20|2@1+ (1,0) [0|3] "-"  LOGBOX,TCU_GWS500
 SG_ ADM3_Ctrl : 22|2@1+ (1,0) [0|3] "-"  LOGBOX,TCU_GWS500
 SG_ ADM4_Ctrl : 24|2@1+ (1,0) [0|3] "-"  LOGBOX,TCU_GWS500
 SG_ ADP1_Ctrl : 26|2@1+ (1,0) [0|3] "-"  LOGBOX,TCU_GWS500
 SG_ ADP2_Ctrl : 28|2@1+ (1,0) [0|3] "-"  LOGBOX,TCU_GWS500
 SG_ ADP3_Ctrl : 30|2@1+ (1,0) [0|3] "-"  LOGBOX,TCU_GWS500
 SG_ ADP4_Ctrl : 32|2@1+ (1,0) [0|3] "-"  LOGBOX,TCU_GWS500
 SG_ EDM1_Ctrl : 34|2@1+ (1,0) [0|3] "-"  LOGBOX,TCU_GWS500
 SG_ EDM2_Ctrl : 36|2@1+ (1,0) [0|3] "-"  LOGBOX,TCU_GWS500
 SG_ EDP3_Ctrl : 38|2@1+ (1,0) [0|3] "-"  LOGBOX,TCU_GWS500
 SG_ EDP4_Ctrl : 40|2@1+ (1,0) [0|3] "-"  LOGBOX,TCU_GWS500
 SG_ AVP_Lever_Interlock_Ctrl : 42|2@1+ (1,0) [0|3] "-"  LOGBOX,TCU_GWS500

CM_ "Vehicle data bus";
CM_ BU_ TCU_TORQUE_CONVERTER "Utilizzato solo per mappare correttamente i DM1 del convertitore di coppia";
CM_ BU_ HYDRONIC "Water To Air heater";
CM_ BU_ AFSS "AFSS system";
CM_ BU_ LOGBOX "Logbox";
CM_ BU_ TCU_GWS500 "Transmission Control Unit (Satellite)";
CM_ BU_ TCU_RET "Transmission Control Unit (Retarder)";
CM_ BU_ DIAG_TOOL "Strumento di diagnosi";
CM_ BU_ CTIS "Central Inflation Sistem";
CM_ BU_ BC "Body Computer";
CM_ BU_ ECM_0x00 "Engine Control Module ( #0)";
CM_ BU_ TCU "Transmission Control Unit (Main)";
CM_ BU_ ALTERNATOR "Alternatore Niehof";
CM_ BU_ CP6 "Control Panel 6''";
CM_ BU_ CP10 "Control Panel 10''";
CM_ BU_ _TESTER "Strumento di diagnosi per configurazione telecamere.
Potrà essere sostituito dal BC.";
CM_ BU_ _TEMPLATE_RUx "Template for Remote Unit (MUX slave)";
CM_ BO_ 3221225472 "This is a message for not used signals, created by Vector CANdb++ DBC OLE DB Provider.";
CM_ SG_ 3221225472 SPN10_Low "SPN #10 (Conversion Version 4)SPN #10 (Conversion Version 4)";
CM_ SG_ 3221225472 SPN9_Low "SPN #9 (Conversion Version 4)SPN #9 (Conversion Version 4)";
CM_ SG_ 3221225472 SPN8_Low "SPN #8 (Conversion Version 4)SPN #8 (Conversion Version 4)";
CM_ SG_ 3221225472 SPN7_Low "SPN #7 (Conversion Version 4)SPN #7 (Conversion Version 4)";
CM_ SG_ 3221225472 SPN6_Low "SPN #6 (Conversion Version 4)SPN #6 (Conversion Version 4)";
CM_ SG_ 3221225472 SPN5_Low "SPN #5 (Conversion Version 4)SPN #5 (Conversion Version 4)";
CM_ SG_ 3221225472 SPN4_Low "SPN #4 (Conversion Version 4)SPN #4 (Conversion Version 4)";
CM_ SG_ 3221225472 SPN3_Low "SPN #3 (Conversion Version 4)SPN #3 (Conversion Version 4)";
CM_ SG_ 3221225472 SPN2_Low "SPN #2 (Conversion Version 4)SPN #2 (Conversion Version 4)";
CM_ SG_ 3221225472 FailureModeIdentifier10 "The FMI defines the type of failure detected in the subsystem identified by an SPN.The FMI defines the type of failure detected in the subsystem identified by an SPN.";
CM_ SG_ 3221225472 FailureModeIdentifier9 "The FMI defines the type of failure detected in the subsystem identified by an SPN.The FMI defines the type of failure detected in the subsystem identified by an SPN.";
CM_ SG_ 3221225472 FailureModeIdentifier8 "The FMI defines the type of failure detected in the subsystem identified by an SPN.The FMI defines the type of failure detected in the subsystem identified by an SPN.";
CM_ SG_ 3221225472 FailureModeIdentifier7 "The FMI defines the type of failure detected in the subsystem identified by an SPN.The FMI defines the type of failure detected in the subsystem identified by an SPN.";
CM_ SG_ 3221225472 FailureModeIdentifier6 "The FMI defines the type of failure detected in the subsystem identified by an SPN.The FMI defines the type of failure detected in the subsystem identified by an SPN.";
CM_ SG_ 3221225472 FailureModeIdentifier5 "The FMI defines the type of failure detected in the subsystem identified by an SPN.The FMI defines the type of failure detected in the subsystem identified by an SPN.";
CM_ SG_ 3221225472 FailureModeIdentifier4 "The FMI defines the type of failure detected in the subsystem identified by an SPN.The FMI defines the type of failure detected in the subsystem identified by an SPN.";
CM_ SG_ 3221225472 FailureModeIdentifier3 "The FMI defines the type of failure detected in the subsystem identified by an SPN.The FMI defines the type of failure detected in the subsystem identified by an SPN.";
CM_ SG_ 3221225472 FlashRedStopLamp "This parameter provides the capability to flash the RSL (SPN 3039).This parameter provides the capability to flash the RSL (SPN 3039).";
CM_ SG_ 3221225472 FlashProtectLamp "This parameter provides the capability to flash the engine protect lamp (SPN 3041).This parameter provides the capability to flash the engine protect lamp (SPN 3041).";
CM_ SG_ 3221225472 FlashMalfuncIndicatorLamp "This parameter provides the capability to flash the MIL (SPN 3038).This parameter provides the capability to flash the MIL (SPN 3038).";
CM_ SG_ 3221225472 FlashAmberWarningLamp "This parameter provides the capability to flash the AWL (SPN 3040). This parameter provides the capability to flash the AWL (SPN 3040). ";
CM_ SG_ 3221225472 MalfunctionIndicatorLampStatus "A lamp used to relay only emissions-related trouble code information.A lamp used to relay only emissions-related trouble code information.";
CM_ SG_ 3221225472 AmberWarningLampStatus "This lamp is used to relay trouble code information that is reporting a problem with the vehicle system but the vehicle neednot be immediately stopped.This lamp is used to relay trouble code information that is reporting a problem with the vehicle system but the vehicle neednot be immediately stopped.";
CM_ SG_ 3221225472 OccurenceCount1 "The 7 bit occurence count field contains the number of times a fault has gone from active to previously active.The 7 bit occurence count field contains the number of times a fault has gone from active to previously active.";
CM_ SG_ 3221225472 SPNConversionMethod1 "SPN Conversion MethodSPN Conversion Method";
CM_ SG_ 3221225472 FailureModeIdentifier1 "The FMI defines the type of failure detected in the subsystem identified by an SPN.The FMI defines the type of failure detected in the subsystem identified by an SPN.";
CM_ SG_ 3221225472 SPN1_Low "SPN #1 (Conversion Version 4)SPN #1 (Conversion Version 4)";
CM_ SG_ 3221225472 RedStopLampState "This lamp is uesed to relay trouble code information that is of a severe enought condition that it warrants stopping the vehicle.This lamp is uesed to relay trouble code information that is of a severe enought condition that it warrants stopping the vehicle.";
CM_ SG_ 3221225472 ProtectLampStatus "This lamp is used to relay trouble code informatio that is reporting a problem with a vehicle system that is most probably not electronic subsystem related.This lamp is used to relay trouble code informatio that is reporting a problem with a vehicle system that is most probably not electronic subsystem related.";
CM_ SG_ 3221225472 FailureModeIdentifier2 "The FMI defines the type of failure detected in the subsystem identified by an SPN.The FMI defines the type of failure detected in the subsystem identified by an SPN.";
CM_ SG_ 3221225472 SPNConversionMethod10 "SPN Conversion MethodSPN Conversion Method";
CM_ SG_ 3221225472 SPNConversionMethod9 "SPN Conversion MethodSPN Conversion Method";
CM_ SG_ 3221225472 SPNConversionMethod8 "SPN Conversion MethodSPN Conversion Method";
CM_ SG_ 3221225472 SPNConversionMethod7 "SPN Conversion MethodSPN Conversion Method";
CM_ SG_ 3221225472 SPNConversionMethod6 "SPN Conversion MethodSPN Conversion Method";
CM_ SG_ 3221225472 SPNConversionMethod5 "SPN Conversion MethodSPN Conversion Method";
CM_ SG_ 3221225472 SPNConversionMethod4 "SPN Conversion MethodSPN Conversion Method";
CM_ SG_ 3221225472 SPNConversionMethod3 "SPN Conversion MethodSPN Conversion Method";
CM_ SG_ 3221225472 SPNConversionMethod2 "SPN Conversion MethodSPN Conversion Method";
CM_ SG_ 3221225472 OccurenceCount10 "The 7 bit occurence count field contains the number of times a fault has gone from active to previously active.The 7 bit occurence count field contains the number of times a fault has gone from active to previously active.";
CM_ SG_ 3221225472 OccurenceCount9 "The 7 bit occurence count field contains the number of times a fault has gone from active to previously active.The 7 bit occurence count field contains the number of times a fault has gone from active to previously active.";
CM_ SG_ 3221225472 OccurenceCount8 "The 7 bit occurence count field contains the number of times a fault has gone from active to previously active.The 7 bit occurence count field contains the number of times a fault has gone from active to previously active.";
CM_ SG_ 3221225472 OccurenceCount7 "The 7 bit occurence count field contains the number of times a fault has gone from active to previously active.The 7 bit occurence count field contains the number of times a fault has gone from active to previously active.";
CM_ SG_ 3221225472 OccurenceCount6 "The 7 bit occurence count field contains the number of times a fault has gone from active to previously active.The 7 bit occurence count field contains the number of times a fault has gone from active to previously active.";
CM_ SG_ 3221225472 OccurenceCount5 "The 7 bit occurence count field contains the number of times a fault has gone from active to previously active.The 7 bit occurence count field contains the number of times a fault has gone from active to previously active.";
CM_ SG_ 3221225472 OccurenceCount4 "The 7 bit occurence count field contains the number of times a fault has gone from active to previously active.The 7 bit occurence count field contains the number of times a fault has gone from active to previously active.";
CM_ SG_ 3221225472 OccurenceCount3 "The 7 bit occurence count field contains the number of times a fault has gone from active to previously active.The 7 bit occurence count field contains the number of times a fault has gone from active to previously active.";
CM_ SG_ 3221225472 OccurenceCount2 "The 7 bit occurence count field contains the number of times a fault has gone from active to previously active.The 7 bit occurence count field contains the number of times a fault has gone from active to previously active.";
CM_ SG_ 3221225472 SPN10_High "SPN #10 (Conversion Version 4)SPN #10 (Conversion Version 4)";
CM_ SG_ 3221225472 SPN9_High "SPN #9 (Conversion Version 4)SPN #9 (Conversion Version 4)";
CM_ SG_ 3221225472 SPN8_High "SPN #8 (Conversion Version 4)SPN #8 (Conversion Version 4)";
CM_ SG_ 3221225472 SPN7_High "SPN #7 (Conversion Version 4)SPN #7 (Conversion Version 4)";
CM_ SG_ 3221225472 SPN6_High "SPN #6 (Conversion Version 4)SPN #6 (Conversion Version 4)";
CM_ SG_ 3221225472 SPN5_High "SPN #5 (Conversion Version 4)SPN #5 (Conversion Version 4)";
CM_ SG_ 3221225472 SPN4_High "SPN #4 (Conversion Version 4)SPN #4 (Conversion Version 4)";
CM_ SG_ 3221225472 SPN3_High "SPN #3 (Conversion Version 4)SPN #3 (Conversion Version 4)";
CM_ SG_ 3221225472 SPN2_High "SPN #2 (Conversion Version 4)SPN #2 (Conversion Version 4)";
CM_ SG_ 3221225472 SPN1_High "SPN #1 (Conversion Version 4)SPN #1 (Conversion Version 4)";
CM_ BO_ 2565603072 "Active diagnostic trouble codes";
CM_ SG_ 2565603072 SPN10_Low "SPN #10 (Conversion Version 4)";
CM_ SG_ 2565603072 SPN9_Low "SPN #9 (Conversion Version 4)";
CM_ SG_ 2565603072 SPN8_Low "SPN #8 (Conversion Version 4)";
CM_ SG_ 2565603072 SPN7_Low "SPN #7 (Conversion Version 4)";
CM_ SG_ 2565603072 SPN6_Low "SPN #6 (Conversion Version 4)";
CM_ SG_ 2565603072 SPN5_Low "SPN #5 (Conversion Version 4)";
CM_ SG_ 2565603072 SPN4_Low "SPN #4 (Conversion Version 4)";
CM_ SG_ 2565603072 SPN3_Low "SPN #3 (Conversion Version 4)";
CM_ SG_ 2565603072 SPN2_Low "SPN #2 (Conversion Version 4)";
CM_ SG_ 2565603072 FailureModeIdentifier10 "The FMI defines the type of failure detected in the subsystem identified by an SPN.";
CM_ SG_ 2565603072 FailureModeIdentifier9 "The FMI defines the type of failure detected in the subsystem identified by an SPN.";
CM_ SG_ 2565603072 FailureModeIdentifier8 "The FMI defines the type of failure detected in the subsystem identified by an SPN.";
CM_ SG_ 2565603072 FailureModeIdentifier7 "The FMI defines the type of failure detected in the subsystem identified by an SPN.";
CM_ SG_ 2565603072 FailureModeIdentifier6 "The FMI defines the type of failure detected in the subsystem identified by an SPN.";
CM_ SG_ 2565603072 FailureModeIdentifier5 "The FMI defines the type of failure detected in the subsystem identified by an SPN.";
CM_ SG_ 2565603072 FailureModeIdentifier4 "The FMI defines the type of failure detected in the subsystem identified by an SPN.";
CM_ SG_ 2565603072 FailureModeIdentifier3 "The FMI defines the type of failure detected in the subsystem identified by an SPN.";
CM_ SG_ 2565603072 FlashRedStopLamp "This parameter provides the capability to flash the RSL (SPN 3039).";
CM_ SG_ 2565603072 FlashProtectLamp "This parameter provides the capability to flash the engine protect lamp (SPN 3041).";
CM_ SG_ 2565603072 FlashMalfuncIndicatorLamp "This parameter provides the capability to flash the MIL (SPN 3038).";
CM_ SG_ 2565603072 FlashAmberWarningLamp "This parameter provides the capability to flash the AWL (SPN 3040). ";
CM_ SG_ 2565603072 MalfunctionIndicatorLampStatus "A lamp used to relay only emissions-related trouble code information.";
CM_ SG_ 2565603072 AmberWarningLampStatus "This lamp is used to relay trouble code information that is reporting a problem with the vehicle system but the vehicle neednot be immediately stopped.";
CM_ SG_ 2565603072 OccurenceCount1 "The 7 bit occurence count field contains the number of times a fault has gone from active to previously active.";
CM_ SG_ 2565603072 SPNConversionMethod1 "SPN Conversion Method";
CM_ SG_ 2565603072 FailureModeIdentifier1 "The FMI defines the type of failure detected in the subsystem identified by an SPN.";
CM_ SG_ 2565603072 SPN1_Low "SPN #1 (Conversion Version 4)";
CM_ SG_ 2565603072 RedStopLampState "This lamp is uesed to relay trouble code information that is of a severe enought condition that it warrants stopping the vehicle.";
CM_ SG_ 2565603072 ProtectLampStatus "This lamp is used to relay trouble code informatio that is reporting a problem with a vehicle system that is most probably not electronic subsystem related.";
CM_ SG_ 2565603072 FailureModeIdentifier2 "The FMI defines the type of failure detected in the subsystem identified by an SPN.";
CM_ SG_ 2565603072 SPNConversionMethod10 "SPN Conversion Method";
CM_ SG_ 2565603072 SPNConversionMethod9 "SPN Conversion Method";
CM_ SG_ 2565603072 SPNConversionMethod8 "SPN Conversion Method";
CM_ SG_ 2565603072 SPNConversionMethod7 "SPN Conversion Method";
CM_ SG_ 2565603072 SPNConversionMethod6 "SPN Conversion Method";
CM_ SG_ 2565603072 SPNConversionMethod5 "SPN Conversion Method";
CM_ SG_ 2565603072 SPNConversionMethod4 "SPN Conversion Method";
CM_ SG_ 2565603072 SPNConversionMethod3 "SPN Conversion Method";
CM_ SG_ 2565603072 SPNConversionMethod2 "SPN Conversion Method";
CM_ SG_ 2565603072 OccurenceCount10 "The 7 bit occurence count field contains the number of times a fault has gone from active to previously active.";
CM_ SG_ 2565603072 OccurenceCount9 "The 7 bit occurence count field contains the number of times a fault has gone from active to previously active.";
CM_ SG_ 2565603072 OccurenceCount8 "The 7 bit occurence count field contains the number of times a fault has gone from active to previously active.";
CM_ SG_ 2565603072 OccurenceCount7 "The 7 bit occurence count field contains the number of times a fault has gone from active to previously active.";
CM_ SG_ 2565603072 OccurenceCount6 "The 7 bit occurence count field contains the number of times a fault has gone from active to previously active.";
CM_ SG_ 2565603072 OccurenceCount5 "The 7 bit occurence count field contains the number of times a fault has gone from active to previously active.";
CM_ SG_ 2565603072 OccurenceCount4 "The 7 bit occurence count field contains the number of times a fault has gone from active to previously active.";
CM_ SG_ 2565603072 OccurenceCount3 "The 7 bit occurence count field contains the number of times a fault has gone from active to previously active.";
CM_ SG_ 2565603072 OccurenceCount2 "The 7 bit occurence count field contains the number of times a fault has gone from active to previously active.";
CM_ SG_ 2565603072 SPN10_High "SPN #10 (Conversion Version 4)";
CM_ SG_ 2565603072 SPN9_High "SPN #9 (Conversion Version 4)";
CM_ SG_ 2565603072 SPN8_High "SPN #8 (Conversion Version 4)";
CM_ SG_ 2565603072 SPN7_High "SPN #7 (Conversion Version 4)";
CM_ SG_ 2565603072 SPN6_High "SPN #6 (Conversion Version 4)";
CM_ SG_ 2565603072 SPN5_High "SPN #5 (Conversion Version 4)";
CM_ SG_ 2565603072 SPN4_High "SPN #4 (Conversion Version 4)";
CM_ SG_ 2565603072 SPN3_High "SPN #3 (Conversion Version 4)";
CM_ SG_ 2565603072 SPN2_High "SPN #2 (Conversion Version 4)";
CM_ SG_ 2565603072 SPN1_High "SPN #1 (Conversion Version 4)";
CM_ BO_ 2565603075 "Active diagnostic trouble codes";
CM_ SG_ 2565603075 SPN10_Low "SPN #10 (Conversion Version 4)";
CM_ SG_ 2565603075 SPN9_Low "SPN #9 (Conversion Version 4)";
CM_ SG_ 2565603075 SPN8_Low "SPN #8 (Conversion Version 4)";
CM_ SG_ 2565603075 SPN7_Low "SPN #7 (Conversion Version 4)";
CM_ SG_ 2565603075 SPN6_Low "SPN #6 (Conversion Version 4)";
CM_ SG_ 2565603075 SPN5_Low "SPN #5 (Conversion Version 4)";
CM_ SG_ 2565603075 SPN4_Low "SPN #4 (Conversion Version 4)";
CM_ SG_ 2565603075 SPN3_Low "SPN #3 (Conversion Version 4)";
CM_ SG_ 2565603075 SPN2_Low "SPN #2 (Conversion Version 4)";
CM_ SG_ 2565603075 FailureModeIdentifier10 "The FMI defines the type of failure detected in the subsystem identified by an SPN.";
CM_ SG_ 2565603075 FailureModeIdentifier9 "The FMI defines the type of failure detected in the subsystem identified by an SPN.";
CM_ SG_ 2565603075 FailureModeIdentifier8 "The FMI defines the type of failure detected in the subsystem identified by an SPN.";
CM_ SG_ 2565603075 FailureModeIdentifier7 "The FMI defines the type of failure detected in the subsystem identified by an SPN.";
CM_ SG_ 2565603075 FailureModeIdentifier6 "The FMI defines the type of failure detected in the subsystem identified by an SPN.";
CM_ SG_ 2565603075 FailureModeIdentifier5 "The FMI defines the type of failure detected in the subsystem identified by an SPN.";
CM_ SG_ 2565603075 FailureModeIdentifier4 "The FMI defines the type of failure detected in the subsystem identified by an SPN.";
CM_ SG_ 2565603075 FailureModeIdentifier3 "The FMI defines the type of failure detected in the subsystem identified by an SPN.";
CM_ SG_ 2565603075 FlashRedStopLamp "This parameter provides the capability to flash the RSL (SPN 3039).";
CM_ SG_ 2565603075 FlashProtectLamp "This parameter provides the capability to flash the engine protect lamp (SPN 3041).";
CM_ SG_ 2565603075 FlashMalfuncIndicatorLamp "This parameter provides the capability to flash the MIL (SPN 3038).";
CM_ SG_ 2565603075 FlashAmberWarningLamp "This parameter provides the capability to flash the AWL (SPN 3040). ";
CM_ SG_ 2565603075 MalfunctionIndicatorLampStatus "A lamp used to relay only emissions-related trouble code information.";
CM_ SG_ 2565603075 AmberWarningLampStatus "This lamp is used to relay trouble code information that is reporting a problem with the vehicle system but the vehicle neednot be immediately stopped.";
CM_ SG_ 2565603075 OccurenceCount1 "The 7 bit occurence count field contains the number of times a fault has gone from active to previously active.";
CM_ SG_ 2565603075 SPNConversionMethod1 "SPN Conversion Method";
CM_ SG_ 2565603075 FailureModeIdentifier1 "The FMI defines the type of failure detected in the subsystem identified by an SPN.";
CM_ SG_ 2565603075 SPN1_Low "SPN #1 (Conversion Version 4)";
CM_ SG_ 2565603075 RedStopLampState "This lamp is uesed to relay trouble code information that is of a severe enought condition that it warrants stopping the vehicle.";
CM_ SG_ 2565603075 ProtectLampStatus "This lamp is used to relay trouble code informatio that is reporting a problem with a vehicle system that is most probably not electronic subsystem related.";
CM_ SG_ 2565603075 FailureModeIdentifier2 "The FMI defines the type of failure detected in the subsystem identified by an SPN.";
CM_ SG_ 2565603075 SPNConversionMethod10 "SPN Conversion Method";
CM_ SG_ 2565603075 SPNConversionMethod9 "SPN Conversion Method";
CM_ SG_ 2565603075 SPNConversionMethod8 "SPN Conversion Method";
CM_ SG_ 2565603075 SPNConversionMethod7 "SPN Conversion Method";
CM_ SG_ 2565603075 SPNConversionMethod6 "SPN Conversion Method";
CM_ SG_ 2565603075 SPNConversionMethod5 "SPN Conversion Method";
CM_ SG_ 2565603075 SPNConversionMethod4 "SPN Conversion Method";
CM_ SG_ 2565603075 SPNConversionMethod3 "SPN Conversion Method";
CM_ SG_ 2565603075 SPNConversionMethod2 "SPN Conversion Method";
CM_ SG_ 2565603075 OccurenceCount10 "The 7 bit occurence count field contains the number of times a fault has gone from active to previously active.";
CM_ SG_ 2565603075 OccurenceCount9 "The 7 bit occurence count field contains the number of times a fault has gone from active to previously active.";
CM_ SG_ 2565603075 OccurenceCount8 "The 7 bit occurence count field contains the number of times a fault has gone from active to previously active.";
CM_ SG_ 2565603075 OccurenceCount7 "The 7 bit occurence count field contains the number of times a fault has gone from active to previously active.";
CM_ SG_ 2565603075 OccurenceCount6 "The 7 bit occurence count field contains the number of times a fault has gone from active to previously active.";
CM_ SG_ 2565603075 OccurenceCount5 "The 7 bit occurence count field contains the number of times a fault has gone from active to previously active.";
CM_ SG_ 2565603075 OccurenceCount4 "The 7 bit occurence count field contains the number of times a fault has gone from active to previously active.";
CM_ SG_ 2565603075 OccurenceCount3 "The 7 bit occurence count field contains the number of times a fault has gone from active to previously active.";
CM_ SG_ 2565603075 OccurenceCount2 "The 7 bit occurence count field contains the number of times a fault has gone from active to previously active.";
CM_ SG_ 2565603075 SPN10_High "SPN #10 (Conversion Version 4)";
CM_ SG_ 2565603075 SPN9_High "SPN #9 (Conversion Version 4)";
CM_ SG_ 2565603075 SPN8_High "SPN #8 (Conversion Version 4)";
CM_ SG_ 2565603075 SPN7_High "SPN #7 (Conversion Version 4)";
CM_ SG_ 2565603075 SPN6_High "SPN #6 (Conversion Version 4)";
CM_ SG_ 2565603075 SPN5_High "SPN #5 (Conversion Version 4)";
CM_ SG_ 2565603075 SPN4_High "SPN #4 (Conversion Version 4)";
CM_ SG_ 2565603075 SPN3_High "SPN #3 (Conversion Version 4)";
CM_ SG_ 2565603075 SPN2_High "SPN #2 (Conversion Version 4)";
CM_ SG_ 2565603075 SPN1_High "SPN #1 (Conversion Version 4)";
CM_ BO_ 2565668611 "Active diagnostic trouble codes";
CM_ BO_ 2565668608 "Active diagnostic trouble codes";
CM_ BO_ 2566834691 "Active diagnostic trouble codes";
CM_ SG_ 2566834691 SPN10_Low "SPN #10 (Conversion Version 4)";
CM_ SG_ 2566834691 SPN9_Low "SPN #9 (Conversion Version 4)";
CM_ SG_ 2566834691 SPN8_Low "SPN #8 (Conversion Version 4)";
CM_ SG_ 2566834691 SPN7_Low "SPN #7 (Conversion Version 4)";
CM_ SG_ 2566834691 SPN6_Low "SPN #6 (Conversion Version 4)";
CM_ SG_ 2566834691 SPN5_Low "SPN #5 (Conversion Version 4)";
CM_ SG_ 2566834691 SPN4_Low "SPN #4 (Conversion Version 4)";
CM_ SG_ 2566834691 SPN3_Low "SPN #3 (Conversion Version 4)";
CM_ SG_ 2566834691 SPN2_Low "SPN #2 (Conversion Version 4)";
CM_ SG_ 2566834691 FailureModeIdentifier10 "The FMI defines the type of failure detected in the subsystem identified by an SPN.";
CM_ SG_ 2566834691 FailureModeIdentifier9 "The FMI defines the type of failure detected in the subsystem identified by an SPN.";
CM_ SG_ 2566834691 FailureModeIdentifier8 "The FMI defines the type of failure detected in the subsystem identified by an SPN.";
CM_ SG_ 2566834691 FailureModeIdentifier7 "The FMI defines the type of failure detected in the subsystem identified by an SPN.";
CM_ SG_ 2566834691 FailureModeIdentifier6 "The FMI defines the type of failure detected in the subsystem identified by an SPN.";
CM_ SG_ 2566834691 FailureModeIdentifier5 "The FMI defines the type of failure detected in the subsystem identified by an SPN.";
CM_ SG_ 2566834691 FailureModeIdentifier4 "The FMI defines the type of failure detected in the subsystem identified by an SPN.";
CM_ SG_ 2566834691 FailureModeIdentifier3 "The FMI defines the type of failure detected in the subsystem identified by an SPN.";
CM_ SG_ 2566834691 FlashRedStopLamp "This parameter provides the capability to flash the RSL (SPN 3039).";
CM_ SG_ 2566834691 FlashProtectLamp "This parameter provides the capability to flash the engine protect lamp (SPN 3041).";
CM_ SG_ 2566834691 FlashMalfuncIndicatorLamp "This parameter provides the capability to flash the MIL (SPN 3038).";
CM_ SG_ 2566834691 FlashAmberWarningLamp "This parameter provides the capability to flash the AWL (SPN 3040). ";
CM_ SG_ 2566834691 MalfunctionIndicatorLampStatus "A lamp used to relay only emissions-related trouble code information.";
CM_ SG_ 2566834691 AmberWarningLampStatus "This lamp is used to relay trouble code information that is reporting a problem with the vehicle system but the vehicle neednot be immediately stopped.";
CM_ SG_ 2566834691 OccurenceCount1 "The 7 bit occurence count field contains the number of times a fault has gone from active to previously active.";
CM_ SG_ 2566834691 SPNConversionMethod1 "SPN Conversion Method";
CM_ SG_ 2566834691 FailureModeIdentifier1 "The FMI defines the type of failure detected in the subsystem identified by an SPN.";
CM_ SG_ 2566834691 SPN1_Low "SPN #1 (Conversion Version 4)";
CM_ SG_ 2566834691 RedStopLampState "This lamp is uesed to relay trouble code information that is of a severe enought condition that it warrants stopping the vehicle.";
CM_ SG_ 2566834691 ProtectLampStatus "This lamp is used to relay trouble code informatio that is reporting a problem with a vehicle system that is most probably not electronic subsystem related.";
CM_ SG_ 2566834691 FailureModeIdentifier2 "The FMI defines the type of failure detected in the subsystem identified by an SPN.";
CM_ SG_ 2566834691 SPNConversionMethod10 "SPN Conversion Method";
CM_ SG_ 2566834691 SPNConversionMethod9 "SPN Conversion Method";
CM_ SG_ 2566834691 SPNConversionMethod8 "SPN Conversion Method";
CM_ SG_ 2566834691 SPNConversionMethod7 "SPN Conversion Method";
CM_ SG_ 2566834691 SPNConversionMethod6 "SPN Conversion Method";
CM_ SG_ 2566834691 SPNConversionMethod5 "SPN Conversion Method";
CM_ SG_ 2566834691 SPNConversionMethod4 "SPN Conversion Method";
CM_ SG_ 2566834691 SPNConversionMethod3 "SPN Conversion Method";
CM_ SG_ 2566834691 SPNConversionMethod2 "SPN Conversion Method";
CM_ SG_ 2566834691 OccurenceCount10 "The 7 bit occurence count field contains the number of times a fault has gone from active to previously active.";
CM_ SG_ 2566834691 OccurenceCount9 "The 7 bit occurence count field contains the number of times a fault has gone from active to previously active.";
CM_ SG_ 2566834691 OccurenceCount8 "The 7 bit occurence count field contains the number of times a fault has gone from active to previously active.";
CM_ SG_ 2566834691 OccurenceCount7 "The 7 bit occurence count field contains the number of times a fault has gone from active to previously active.";
CM_ SG_ 2566834691 OccurenceCount6 "The 7 bit occurence count field contains the number of times a fault has gone from active to previously active.";
CM_ SG_ 2566834691 OccurenceCount5 "The 7 bit occurence count field contains the number of times a fault has gone from active to previously active.";
CM_ SG_ 2566834691 OccurenceCount4 "The 7 bit occurence count field contains the number of times a fault has gone from active to previously active.";
CM_ SG_ 2566834691 OccurenceCount3 "The 7 bit occurence count field contains the number of times a fault has gone from active to previously active.";
CM_ SG_ 2566834691 OccurenceCount2 "The 7 bit occurence count field contains the number of times a fault has gone from active to previously active.";
CM_ SG_ 2566834691 SPN10_High "SPN #10 (Conversion Version 4)";
CM_ SG_ 2566834691 SPN9_High "SPN #9 (Conversion Version 4)";
CM_ SG_ 2566834691 SPN8_High "SPN #8 (Conversion Version 4)";
CM_ SG_ 2566834691 SPN7_High "SPN #7 (Conversion Version 4)";
CM_ SG_ 2566834691 SPN6_High "SPN #6 (Conversion Version 4)";
CM_ SG_ 2566834691 SPN5_High "SPN #5 (Conversion Version 4)";
CM_ SG_ 2566834691 SPN4_High "SPN #4 (Conversion Version 4)";
CM_ SG_ 2566834691 SPN3_High "SPN #3 (Conversion Version 4)";
CM_ SG_ 2566834691 SPN2_High "SPN #2 (Conversion Version 4)";
CM_ SG_ 2566834691 SPN1_High "SPN #1 (Conversion Version 4)";
CM_ BO_ 2566834688 "Active diagnostic trouble codes";
CM_ SG_ 2566834688 SPN10_Low "SPN #10 (Conversion Version 4)";
CM_ SG_ 2566834688 SPN9_Low "SPN #9 (Conversion Version 4)";
CM_ SG_ 2566834688 SPN8_Low "SPN #8 (Conversion Version 4)";
CM_ SG_ 2566834688 SPN7_Low "SPN #7 (Conversion Version 4)";
CM_ SG_ 2566834688 SPN6_Low "SPN #6 (Conversion Version 4)";
CM_ SG_ 2566834688 SPN5_Low "SPN #5 (Conversion Version 4)";
CM_ SG_ 2566834688 SPN4_Low "SPN #4 (Conversion Version 4)";
CM_ SG_ 2566834688 SPN3_Low "SPN #3 (Conversion Version 4)";
CM_ SG_ 2566834688 SPN2_Low "SPN #2 (Conversion Version 4)";
CM_ SG_ 2566834688 FailureModeIdentifier10 "The FMI defines the type of failure detected in the subsystem identified by an SPN.";
CM_ SG_ 2566834688 FailureModeIdentifier9 "The FMI defines the type of failure detected in the subsystem identified by an SPN.";
CM_ SG_ 2566834688 FailureModeIdentifier8 "The FMI defines the type of failure detected in the subsystem identified by an SPN.";
CM_ SG_ 2566834688 FailureModeIdentifier7 "The FMI defines the type of failure detected in the subsystem identified by an SPN.";
CM_ SG_ 2566834688 FailureModeIdentifier6 "The FMI defines the type of failure detected in the subsystem identified by an SPN.";
CM_ SG_ 2566834688 FailureModeIdentifier5 "The FMI defines the type of failure detected in the subsystem identified by an SPN.";
CM_ SG_ 2566834688 FailureModeIdentifier4 "The FMI defines the type of failure detected in the subsystem identified by an SPN.";
CM_ SG_ 2566834688 FailureModeIdentifier3 "The FMI defines the type of failure detected in the subsystem identified by an SPN.";
CM_ SG_ 2566834688 FlashRedStopLamp "This parameter provides the capability to flash the RSL (SPN 3039).";
CM_ SG_ 2566834688 FlashProtectLamp "This parameter provides the capability to flash the engine protect lamp (SPN 3041).";
CM_ SG_ 2566834688 FlashMalfuncIndicatorLamp "This parameter provides the capability to flash the MIL (SPN 3038).";
CM_ SG_ 2566834688 FlashAmberWarningLamp "This parameter provides the capability to flash the AWL (SPN 3040). ";
CM_ SG_ 2566834688 MalfunctionIndicatorLampStatus "A lamp used to relay only emissions-related trouble code information.";
CM_ SG_ 2566834688 AmberWarningLampStatus "This lamp is used to relay trouble code information that is reporting a problem with the vehicle system but the vehicle neednot be immediately stopped.";
CM_ SG_ 2566834688 OccurenceCount1 "The 7 bit occurence count field contains the number of times a fault has gone from active to previously active.";
CM_ SG_ 2566834688 SPNConversionMethod1 "SPN Conversion Method";
CM_ SG_ 2566834688 FailureModeIdentifier1 "The FMI defines the type of failure detected in the subsystem identified by an SPN.";
CM_ SG_ 2566834688 SPN1_Low "SPN #1 (Conversion Version 4)";
CM_ SG_ 2566834688 RedStopLampState "This lamp is uesed to relay trouble code information that is of a severe enought condition that it warrants stopping the vehicle.";
CM_ SG_ 2566834688 ProtectLampStatus "This lamp is used to relay trouble code informatio that is reporting a problem with a vehicle system that is most probably not electronic subsystem related.";
CM_ SG_ 2566834688 FailureModeIdentifier2 "The FMI defines the type of failure detected in the subsystem identified by an SPN.";
CM_ SG_ 2566834688 SPNConversionMethod10 "SPN Conversion Method";
CM_ SG_ 2566834688 SPNConversionMethod9 "SPN Conversion Method";
CM_ SG_ 2566834688 SPNConversionMethod8 "SPN Conversion Method";
CM_ SG_ 2566834688 SPNConversionMethod7 "SPN Conversion Method";
CM_ SG_ 2566834688 SPNConversionMethod6 "SPN Conversion Method";
CM_ SG_ 2566834688 SPNConversionMethod5 "SPN Conversion Method";
CM_ SG_ 2566834688 SPNConversionMethod4 "SPN Conversion Method";
CM_ SG_ 2566834688 SPNConversionMethod3 "SPN Conversion Method";
CM_ SG_ 2566834688 SPNConversionMethod2 "SPN Conversion Method";
CM_ SG_ 2566834688 OccurenceCount10 "The 7 bit occurence count field contains the number of times a fault has gone from active to previously active.";
CM_ SG_ 2566834688 OccurenceCount9 "The 7 bit occurence count field contains the number of times a fault has gone from active to previously active.";
CM_ SG_ 2566834688 OccurenceCount8 "The 7 bit occurence count field contains the number of times a fault has gone from active to previously active.";
CM_ SG_ 2566834688 OccurenceCount7 "The 7 bit occurence count field contains the number of times a fault has gone from active to previously active.";
CM_ SG_ 2566834688 OccurenceCount6 "The 7 bit occurence count field contains the number of times a fault has gone from active to previously active.";
CM_ SG_ 2566834688 OccurenceCount5 "The 7 bit occurence count field contains the number of times a fault has gone from active to previously active.";
CM_ SG_ 2566834688 OccurenceCount4 "The 7 bit occurence count field contains the number of times a fault has gone from active to previously active.";
CM_ SG_ 2566834688 OccurenceCount3 "The 7 bit occurence count field contains the number of times a fault has gone from active to previously active.";
CM_ SG_ 2566834688 OccurenceCount2 "The 7 bit occurence count field contains the number of times a fault has gone from active to previously active.";
CM_ SG_ 2566834688 SPN10_High "SPN #10 (Conversion Version 4)";
CM_ SG_ 2566834688 SPN9_High "SPN #9 (Conversion Version 4)";
CM_ SG_ 2566834688 SPN8_High "SPN #8 (Conversion Version 4)";
CM_ SG_ 2566834688 SPN7_High "SPN #7 (Conversion Version 4)";
CM_ SG_ 2566834688 SPN6_High "SPN #6 (Conversion Version 4)";
CM_ SG_ 2566834688 SPN5_High "SPN #5 (Conversion Version 4)";
CM_ SG_ 2566834688 SPN4_High "SPN #4 (Conversion Version 4)";
CM_ SG_ 2566834688 SPN3_High "SPN #3 (Conversion Version 4)";
CM_ SG_ 2566834688 SPN2_High "SPN #2 (Conversion Version 4)";
CM_ SG_ 2566834688 SPN1_High "SPN #1 (Conversion Version 4)";
CM_ SG_ 2633934618 Alt_RegulatorTemperature "To be completed";
CM_ SG_ 2633934618 Alt_InternalTemperature "To be completed";
CM_ SG_ 2566846234 Alt_Voltage_1 "To be completed";
CM_ SG_ 2566846234 Alt_BatteryVoltage_1 "To be completed";
CM_ SG_ 2566905882 Alt_SoftwareVersion "To be completed";
CM_ SG_ 2566905882 Alt_HardwareVersion "To be completed";
CM_ SG_ 2566900762 Alt_P4_8 "To be completed";
CM_ SG_ 2566900762 Alt_P4_7 "To be completed";
CM_ SG_ 2566900762 Alt_P4_6 "To be completed";
CM_ SG_ 2566900762 Alt_P4_5 "To be completed";
CM_ SG_ 2566900762 Alt_P4_4 "To be completed";
CM_ SG_ 2566900762 Alt_P4_3 "To be completed";
CM_ SG_ 2566900762 Alt_P4_2 "To be completed";
CM_ SG_ 2566900762 Alt_P4_1 "To be completed";
CM_ SG_ 2566900506 Alt_Voltage_2 "To be completed";
CM_ SG_ 2566900506 Alt_Speed_2 "The signal shall be used by the BODY to know the current Alternator speed.";
CM_ SG_ 2566900506 Alt_BatteryVoltage_2 "To be completed";
CM_ SG_ 2566900506 Alt_PercentOutput_2 "The signal shall be used by the BODY to know the current Alternator Load.";
CM_ SG_ 2566899994 Alt_BatteryTypeLocation "To be completed";
CM_ SG_ 2566899994 Alt_Flags "To be completed";
CM_ SG_ 2566899994 Alt_Set_Point "To be completed";
CM_ BO_ 2348814375 "Torque/Speed Control 1";
CM_ SG_ 2348814375 MessageChecksum_TSC1_VDR "To be completed";
CM_ SG_ 2348814375 MessageCounter_TSC1_VDR "To be completed";
CM_ SG_ 2348814375 EngineRequestedTq_HR_TSC1_VDR "To be completed";
CM_ SG_ 2348814375 ControlPurpose_TSC1_VDR "State signal which indicates which control mode the sending device is using to generate the TSC1 command.";
CM_ SG_ 2348814375 TransmissionRate_TSC1_VDR "This parameter indicates the transmission rate at which the sending device will transmit the TSC1 message.";
CM_ SG_ 2348814375 EngRqedTorque_Limit_TSC1_VDR "Parameter provided to the engine or retarder in the torque/speed control message for controlling or limiting the output torque.";
CM_ SG_ 2348814375 EngRqedSpeed_SpeedLimit_TSC1_VDR "Parameter provided to the engine from external sources in the torque/speed control message.";
CM_ SG_ 2348814375 OverrideCtrlModPriority_TSC1_VDR "The signal shall be set by the BODY to define the control priority request to the engine.";
CM_ SG_ 2348814375 EngRqedSpeedCtrlCondit_TSC1_VDR "This mode tells the engine control system the governor characteristics that are desired during speed control.";
CM_ SG_ 2348814375 EngOverrideCtrlMode_TSC1_VDR "The signal shall be set by the BODY to define the control request to the engine.";
CM_ SG_ 2566824960 EngineEcuTemp "Temperature of the engine electronic control unit.
See also SPN 1136";
CM_ SG_ 2566848545 VehicleSpeedLimit "The signal shall be set by the BODY to define the Vehicle Speed second limit to send to the ECM.
It shall be transmitted CAN as per Requirement SYS_CAN_1420.
The significant values of the signal shall be:
[0;250]: they indicates the Vehicle Speed limit range.
All the allowable values of the signal are detailed in CAN database.";
CM_ BO_ 2566809413 "Climate control configuration - WTA";
CM_ SG_ 2566809413 HeaterMaximumOutputPower "To be completed";
CM_ BO_ 2566810949 "Heater Information - WTA";
CM_ SG_ 2566810949 HeaterWaterTemperature "To be completed";
CM_ SG_ 2566810949 Heater_Input_Air_Temperature "To be completed";
CM_ SG_ 2566810949 Heater_Output_Power_Percent "To be completed";
CM_ SG_ 2566810949 Heater_Mode "To be completed";
CM_ SG_ 2566810949 Heater_coolant_pump_state "To be completed";
CM_ SG_ 2566810949 Cab_ventilation "To be completed";
CM_ SG_ 2566810949 Engine_Heating_Zone "To be completed";
CM_ SG_ 2566810949 Cab_Heating_Zone "To be completed";
CM_ BO_ 2566842000 "Time and Date";
CM_ SG_ 2566842000 Seconds_VDB "To be completed";
CM_ SG_ 2566842000 Minutes_VDB "To be completed";
CM_ SG_ 2566842000 Hours_VDB "To be completed";
CM_ SG_ 2566842000 Month_VDB "To be completed";
CM_ SG_ 2566842000 Day_VDB "To be completed";
CM_ SG_ 2566842000 Year_VDB "To be completed";
CM_ SG_ 2566842000 Local_Minute_Offset_VDB "To be completed";
CM_ SG_ 2566842000 Local_Hour_Offset_VDB "To be completed";
CM_ BO_ 2558590749 "Message from AFSS to MUX (2)";
CM_ SG_ 2558590749 AFSS_Zone_Fault0 "This signal report the AFSS zone 0 failure state.
In the C2 applicatio, the zone 0 is used for the engine bay area";
CM_ SG_ 2558590749 AFSS_Zone_Fault1 "This signal report the AFSS zone 1 failure state.
In the C2 applicatio, the zone 1 is not used";
CM_ SG_ 2558590749 AFSS_Zone_Fault2 "This signal report the AFSS zone 2 failure state.
In the C2 applicatio, the zone 2 is used for the crew area";
CM_ SG_ 2558590749 AFSS_Zone_Fault3 "This signal report the AFSS zone 3 failure state.
In the C2 applicatio, the zone 3 is used for the payload area";
CM_ SG_ 2558590749 AFSS_Zone_Fire_Alarm0 "This signal report the AFSS zone 0 fire alarm.
In the C2 applicatio, the zone 0 is used for the engine bay area";
CM_ SG_ 2558590749 AFSS_Zone_Fire_Alarm1 "This signal report the AFSS zone 1 fire alarm.
In the C2 applicatio, the zone 1 is not used";
CM_ SG_ 2558590749 AFSS_Zone_Fire_Alarm2 "This signal report the AFSS zone 2 fire alarm.
In the C2 applicatio, the zone 2 is used for the crew area";
CM_ SG_ 2558590749 AFSS_Zone_Fire_Alarm3 "This signal report the AFSS zone 3 fire alarm.
In the C2 applicatio, the zone 3 is used for the payload area";
CM_ SG_ 2558590749 AFSS_Voltage_Fault "This signal has to be used for report the power supply voltage failure";
CM_ SG_ 2558590749 AFSS_Internal_Fault "This signal has to be used for report the AFSS internal fault";
CM_ SG_ 2558590749 AFSS_Config_Error "The signal contain the information about the configuration status in the AFSS.";
CM_ SG_ 2558590749 AFSS_Zone_inhibited "This signal has to be used for report the inhibited zone status";
CM_ SG_ 2558590749 AFSS_Self_Test "This signal has to be used for the AFSS self test";
CM_ SG_ 2558590749 AFSS_ContrOut0 "This signal contain the stutus of the AFSS control output 0.
For C2 application, the control output contains the 'ECU status led and logic power on'";
CM_ SG_ 2558590749 AFSS_ContrOut1 "This signal contain the stutus of the AFSS control output 1.
For C2 application, the control output contains the 'fire detected in the engine bay'";
CM_ SG_ 2558590749 AFSS_ContrOut2 "This signal contain the stutus of the AFSS control output 2.
For C2 application, the control output contains the 'engine bay first discharge'";
CM_ SG_ 2558590749 AFSS_ContrOut3 "This signal contain the stutus of the AFSS control output 3.
For C2 application, the control output contains the 'crew area first discharge'";
CM_ SG_ 2558590749 AFSS_ContrOut4 "This signal contain the stutus of the AFSS control output 4.
For C2 application, the control output contains the 'Ventilation required in crew area'";
CM_ SG_ 2558590749 AFSS_ContrOut5 "This signal contain the stutus of the AFSS control output 5.
For C2 application, the control output contains the 'comulative failure in supervised zone'";
CM_ SG_ 2558590749 AFSS_ContrOut6 "This signal contain the stutus of the AFSS control output 6.
For C2 application, the control output contains the 'payload area first discharge'";
CM_ SG_ 2558590749 AFSS_ContrOut7 "This signal contain the stutus of the AFSS control output 7.
For C2 application, the control output contains the 'Fire detected in payload area'";
CM_ SG_ 2558590749 AFSS_ExtInp0 "External input status #0";
CM_ SG_ 2558590749 AFSS_ExtInp1 "External input status #1";
CM_ SG_ 2558590749 AFSS_ExtInp2 "External input status #2";
CM_ SG_ 2558590749 AFSS_ExtInp3 "External input status #3";
CM_ SG_ 2558590749 AFSS_ExtInp4 "External input status #4";
CM_ SG_ 2558590749 AFSS_ExtInp5 "External input status #5";
CM_ SG_ 2558590749 AFSS_ExtInp6 "External input status #6";
CM_ SG_ 2558590749 AFSS_ExtInp7 "External input status #7";
CM_ SG_ 2558590749 AFSS_NotUsed "Not used";
CM_ BO_ 2558656285 "Message from AFSS to MUX (1)";
CM_ SG_ 2558656285 AFSS_Est7_Status "The signal shall be used by the BODY to know the status of the fire extinguishers #7.";
CM_ SG_ 2558656285 AFSS_Est6_Status "The signal shall be used by the BODY to know the status of the fire extinguishers #6.";
CM_ SG_ 2558656285 AFSS_Est5_Status "The signal shall be used by the BODY to know the status of the fire extinguishers #5.";
CM_ SG_ 2558656285 AFSS_Est4_Status "The signal shall be used by the BODY to know the status of the fire extinguishers #4.";
CM_ SG_ 2558656285 AFSS_Est3_Status "The signal shall be used by the BODY to know the status of the fire extinguishers #3.";
CM_ SG_ 2558656285 AFSS_Est2_Status "The signal shall be used by the BODY to know the status of the fire extinguishers #2.";
CM_ SG_ 2558656285 AFSS_Est1_Status "The signal shall be used by the BODY to know the status of the fire extinguishers #1.";
CM_ SG_ 2558656285 AFSS_Est0_Status "The signal shall be used by the BODY to know the status of the fire extinguishers #0.";
CM_ SG_ 2558656285 AFSS_Sens7_Status "This signal report the AFSS sensor#7 status";
CM_ SG_ 2558656285 AFSS_Sens6_Status "This signal report the AFSS sensor#6 status";
CM_ SG_ 2558656285 AFSS_Sens5_Status "This signal report the AFSS sensor#5 status";
CM_ SG_ 2558656285 AFSS_Sens4_Status "This signal report the AFSS sensor#4 status";
CM_ SG_ 2558656285 AFSS_Sens3_Status "This signal report the AFSS sensor#3 status";
CM_ SG_ 2558656285 AFSS_Sens2_Status "This signal report the AFSS sensor#2 status";
CM_ SG_ 2558656285 AFSS_Sens1_Status "This signal report the AFSS sensor#1 status";
CM_ SG_ 2558656285 AFSS_Sens0_Status "This signal report the AFSS sensor#0 status";
CM_ BO_ 2364474627 "PM2 from GWS500";
CM_ SG_ 2364474627 TransmissionRequestedRange "To be completed";
CM_ SG_ 2364474627 ADM1_Ctrl "To be completed";
CM_ SG_ 2364474627 ADM2_Ctrl "To be completed";
CM_ SG_ 2364474627 ADM3_Ctrl "To be completed";
CM_ SG_ 2364474627 ADM4_Ctrl "To be completed";
CM_ SG_ 2364474627 ADP1_Ctrl "To be completed";
CM_ SG_ 2364474627 ADP2_Ctrl "To be completed";
CM_ SG_ 2364474627 ADP3_Ctrl "To be completed";
CM_ SG_ 2364474627 ADP4_Ctrl "To be completed";
CM_ SG_ 2364474627 EDM1_Ctrl "To be completed";
CM_ SG_ 2364474627 EDM2_Ctrl "To be completed";
CM_ SG_ 2364474627 EDP3_Ctrl "To be completed";
CM_ SG_ 2364474627 EDP4_Ctrl "To be completed";
CM_ SG_ 2364474627 AVP_Lever_Interlock_Ctrl "To be completed";
BA_DEF_  "ProtocolType" STRING ;
BA_DEF_  "BusType" STRING ;
BA_DEF_  "DBName" STRING ;
BA_DEF_  "DatabaseVersion" STRING ;
BA_DEF_ BO_  "GenMsgCycleTimeFast" INT 0 3600000;
BA_DEF_ BO_  "GenMsgDelayTime" INT 0 3600000;
BA_DEF_ BO_  "GenMsgStartDelayTime" INT 0 10000;
BA_DEF_ BO_  "GenMsgSendType" ENUM  "cyclic","reserved","cyclicIfActive","reserved","reserved","reserved","reserved","reserved","noMsgSendType";
BA_DEF_ BO_  "GenMsgCycleTime" INT 0 3600000;
BA_DEF_ BO_  "GenMsgILSupport" ENUM  "No","Yes";
BA_DEF_ BO_  "VFrameFormat" ENUM  "StandardCAN","ExtendedCAN","reserved","J1939PG";
BA_DEF_ BO_  "GenMsgSendTypex" ENUM  "cyclic","reserved","cyclicIfActive","reserved","reserved","reserved","reserved","reserved","noMsgSendType";
BA_DEF_ BO_  "GenMsgRequestable" INT 0 1;
BA_DEF_ BO_  "GenMsgSencmype" ENUM  "cyclic","reserved","cyclicIfActive","reserved","reserved","reserved","reserved","reserved","noMsgSencmype";
BA_DEF_ BO_  "GenMsgSencmypex" ENUM  "cyclic","reserved","cyclicIfActive","reserved","reserved","reserved","reserved","reserved","noMsgSencmype";
BA_DEF_ BU_  "NmStationAddress" INT 0 255;
BA_DEF_ BU_  "ILUsed" ENUM  "Yes","No";
BA_DEF_ BU_  "NodeLayerModules" STRING ;
BA_DEF_ SG_  "GenSigSendType" ENUM  "Cyclic","OnWrite","reserved","OnChange","reserved","reserved","reserved","NoSigSendType";
BA_DEF_ SG_  "GenSigStartValue" INT 0 10000;
BA_DEF_ SG_  "GenSigEVName" STRING ;
BA_DEF_ SG_  "GenSigILSupport" ENUM  "Yes","No";
BA_DEF_ SG_  "GenSigSendTypex" ENUM  "Cyclic","OnWrite","reserved","OnChange","reserved","reserved","reserved","NoSigSendType";
BA_DEF_ SG_  "SPN" INT 0 524287;
BA_DEF_ SG_  "GenSigSencmype" ENUM  "Cyclic","OnWrite","reserved","OnChange","reserved","reserved","reserved","NoSigSencmype";
BA_DEF_ SG_  "GenSigSencmypex" ENUM  "Cyclic","OnWrite","reserved","OnChange","reserved","reserved","reserved","NoSigSencmype";
BA_DEF_DEF_  "ProtocolType" "J1939";
BA_DEF_DEF_  "BusType" "CAN";
BA_DEF_DEF_  "DBName" "";
BA_DEF_DEF_  "DatabaseVersion" "";
BA_DEF_DEF_  "GenMsgCycleTimeFast" 0;
BA_DEF_DEF_  "GenMsgDelayTime" 0;
BA_DEF_DEF_  "GenMsgStartDelayTime" 0;
BA_DEF_DEF_  "GenMsgSendType" "noMsgSendType";
BA_DEF_DEF_  "GenMsgCycleTime" 0;
BA_DEF_DEF_  "GenMsgILSupport" "Yes";
BA_DEF_DEF_  "VFrameFormat" "J1939PG";
BA_DEF_DEF_  "GenMsgSendTypex" "noMsgSendType";
BA_DEF_DEF_  "GenMsgRequestable" 1;
BA_DEF_DEF_  "GenMsgSencmype" "noMsgSencmype";
BA_DEF_DEF_  "GenMsgSencmypex" "noMsgSencmype";
BA_DEF_DEF_  "NmStationAddress" 254;
BA_DEF_DEF_  "ILUsed" "Yes";
BA_DEF_DEF_  "NodeLayerModules" "CANoeILNLVector.dll";
BA_DEF_DEF_  "GenSigSendType" "NoSigSendType";
BA_DEF_DEF_  "GenSigStartValue" 0;
BA_DEF_DEF_  "GenSigEVName" "Env@Nodename_@Signame";
BA_DEF_DEF_  "GenSigILSupport" "Yes";
BA_DEF_DEF_  "GenSigSendTypex" "NoSigSendType";
BA_DEF_DEF_  "SPN" 0;
BA_DEF_DEF_  "GenSigSencmype" "NoSigSencmype";
BA_DEF_DEF_  "GenSigSencmypex" "NoSigSencmype";
BA_ "ProtocolType" "CAN";
BA_ "DatabaseVersion" "5dA";
BA_ "DBName" "C2_VDB";
BA_ "NmStationAddress" BU_ TCU_TORQUE_CONVERTER 67;
BA_ "NmStationAddress" BU_ HYDRONIC 69;
BA_ "NmStationAddress" BU_ AFSS 29;
BA_ "NmStationAddress" BU_ LOGBOX 144;
BA_ "NmStationAddress" BU_ TCU_GWS500 5;
BA_ "NmStationAddress" BU_ TCU_RET 16;
BA_ "NmStationAddress" BU_ DIAG_TOOL 241;
BA_ "NmStationAddress" BU_ CTIS 51;
BA_ "NmStationAddress" BU_ BC 33;
BA_ "NmStationAddress" BU_ ECM_0x00 0;
BA_ "NmStationAddress" BU_ TCU 3;
BA_ "NmStationAddress" BU_ ALTERNATOR 26;
BA_ "NmStationAddress" BU_ CP6 23;
BA_ "NmStationAddress" BU_ CP10 55;
BA_ "NmStationAddress" BU_ _TEMPLATE_RUx 170;
BA_ "GenMsgCycleTime" BO_ 2565603072 1000;
BA_ "GenMsgCycleTime" BO_ 2565603075 1000;
BA_ "GenMsgCycleTime" BO_ 2565668611 1000;
BA_ "GenMsgCycleTime" BO_ 2565668608 1000;
BA_ "GenMsgCycleTime" BO_ 2566834691 1000;
BA_ "GenMsgCycleTime" BO_ 2566834688 1000;
BA_ "GenMsgCycleTime" BO_ 2633934618 1000;
BA_ "GenMsgSendType" BO_ 2633934618 0;
BA_ "GenMsgCycleTime" BO_ 2566846234 1000;
BA_ "GenMsgSendType" BO_ 2566846234 0;
BA_ "GenMsgCycleTime" BO_ 2566905882 1000;
BA_ "GenMsgSendType" BO_ 2566905882 0;
BA_ "GenMsgCycleTime" BO_ 2566900762 1000;
BA_ "GenMsgSendType" BO_ 2566900762 0;
BA_ "GenMsgCycleTime" BO_ 2566900506 100;
BA_ "GenMsgSendType" BO_ 2566900506 0;
BA_ "GenMsgCycleTime" BO_ 2566899994 1000;
BA_ "GenMsgSendType" BO_ 2566899994 0;
BA_ "GenMsgCycleTime" BO_ 2348814375 10;
BA_ "GenMsgSendType" BO_ 2348814375 0;
BA_ "GenMsgCycleTime" BO_ 2566824960 1000;
BA_ "GenMsgSendType" BO_ 2566824960 0;
BA_ "GenMsgCycleTime" BO_ 2566848545 250;
BA_ "GenMsgSendType" BO_ 2566848545 0;
BA_ "GenMsgSendType" BO_ 2566809413 2;
BA_ "GenMsgCycleTime" BO_ 2566810949 1000;
BA_ "GenMsgSendType" BO_ 2566810949 0;
BA_ "GenMsgCycleTime" BO_ 2566842000 1000;
BA_ "GenMsgSendType" BO_ 2566842000 2;
BA_ "GenMsgCycleTime" BO_ 2558590749 1000;
BA_ "GenMsgSendType" BO_ 2558590749 0;
BA_ "GenMsgCycleTime" BO_ 2558656285 1000;
BA_ "GenMsgSendType" BO_ 2558656285 0;
BA_ "GenMsgCycleTime" BO_ 2364474627 50;
BA_ "GenMsgSendType" BO_ 2364474627 0;
BA_ "GenSigStartValue" SG_ 2633934618 Alt_RegulatorTemperature 40;
BA_ "GenSigStartValue" SG_ 2633934618 Alt_InternalTemperature 40;
BA_ "GenSigStartValue" SG_ 2566899994 Alt_BatteryTypeLocation 1;
BA_ "GenSigStartValue" SG_ 2566824960 EngineEcuTemp 8736;
BA_ "GenSigStartValue" SG_ 2566810949 HeaterWaterTemperature 40;
BA_ "GenSigStartValue" SG_ 2566810949 Heater_Input_Air_Temperature 40;
BA_ "GenSigStartValue" SG_ 2566842000 Month_VDB 1;
BA_ "GenSigStartValue" SG_ 2566842000 Day_VDB 1;
BA_ "GenSigStartValue" SG_ 2566842000 Local_Minute_Offset_VDB 125;
BA_ "GenSigStartValue" SG_ 2566842000 Local_Hour_Offset_VDB 125;
VAL_ 3221225472 FailureModeIdentifier10 31 "NotAvailable" 30 "NotAvailable" 29 "NotAvailable" 28 "NotAvailable" 27 "NotAvailable" 26 "NotAvailable" 25 "NotAvailable" 24 "NotAvailable" 23 "NotAvailable" 22 "NotAvailable" 21 "NotAvailable" 20 "NotAvailable" 19 "ReceivedNetworkDataInError" 18 "BelowNormalModeratelySevere" 17 "BelowNormalLeastSevere" 16 "AboveNormalModeratelySevere" 15 "AboveNormalLeastSevere" 14 "SpecialIntstructions" 13 "OutOfCalibration" 12 "BadIntelligentDevice" 11 "RootCauseNotKnown" 10 "AbnormalRateOfChange" 9 "AbnormalUpdateRate" 8 "AbnormalFrequency" 7 "MechanicalSystemNotResponding" 6 "CurrentAboveNormal" 5 "CurrentBelowNormal" 4 "VoltageBelowNormal" 3 "VoltageAboveNormal" 2 "DataErratic" 1 "BelowNormalMostSevere" 0 "AboveNormalMostSevere" ;
VAL_ 3221225472 FailureModeIdentifier9 31 "NotAvailable" 30 "NotAvailable" 29 "NotAvailable" 28 "NotAvailable" 27 "NotAvailable" 26 "NotAvailable" 25 "NotAvailable" 24 "NotAvailable" 23 "NotAvailable" 22 "NotAvailable" 21 "NotAvailable" 20 "NotAvailable" 19 "ReceivedNetworkDataInError" 18 "BelowNormalModeratelySevere" 17 "BelowNormalLeastSevere" 16 "AboveNormalModeratelySevere" 15 "AboveNormalLeastSevere" 14 "SpecialIntstructions" 13 "OutOfCalibration" 12 "BadIntelligentDevice" 11 "RootCauseNotKnown" 10 "AbnormalRateOfChange" 9 "AbnormalUpdateRate" 8 "AbnormalFrequency" 7 "MechanicalSystemNotResponding" 6 "CurrentAboveNormal" 5 "CurrentBelowNormal" 4 "VoltageBelowNormal" 3 "VoltageAboveNormal" 2 "DataErratic" 1 "BelowNormalMostSevere" 0 "AboveNormalMostSevere" ;
VAL_ 3221225472 FailureModeIdentifier8 31 "NotAvailable" 30 "NotAvailable" 29 "NotAvailable" 28 "NotAvailable" 27 "NotAvailable" 26 "NotAvailable" 25 "NotAvailable" 24 "NotAvailable" 23 "NotAvailable" 22 "NotAvailable" 21 "NotAvailable" 20 "NotAvailable" 19 "ReceivedNetworkDataInError" 18 "BelowNormalModeratelySevere" 17 "BelowNormalLeastSevere" 16 "AboveNormalModeratelySevere" 15 "AboveNormalLeastSevere" 14 "SpecialIntstructions" 13 "OutOfCalibration" 12 "BadIntelligentDevice" 11 "RootCauseNotKnown" 10 "AbnormalRateOfChange" 9 "AbnormalUpdateRate" 8 "AbnormalFrequency" 7 "MechanicalSystemNotResponding" 6 "CurrentAboveNormal" 5 "CurrentBelowNormal" 4 "VoltageBelowNormal" 3 "VoltageAboveNormal" 2 "DataErratic" 1 "BelowNormalMostSevere" 0 "AboveNormalMostSevere" ;
VAL_ 3221225472 FailureModeIdentifier7 31 "NotAvailable" 30 "NotAvailable" 29 "NotAvailable" 28 "NotAvailable" 27 "NotAvailable" 26 "NotAvailable" 25 "NotAvailable" 24 "NotAvailable" 23 "NotAvailable" 22 "NotAvailable" 21 "NotAvailable" 20 "NotAvailable" 19 "ReceivedNetworkDataInError" 18 "BelowNormalModeratelySevere" 17 "BelowNormalLeastSevere" 16 "AboveNormalModeratelySevere" 15 "AboveNormalLeastSevere" 14 "SpecialIntstructions" 13 "OutOfCalibration" 12 "BadIntelligentDevice" 11 "RootCauseNotKnown" 10 "AbnormalRateOfChange" 9 "AbnormalUpdateRate" 8 "AbnormalFrequency" 7 "MechanicalSystemNotResponding" 6 "CurrentAboveNormal" 5 "CurrentBelowNormal" 4 "VoltageBelowNormal" 3 "VoltageAboveNormal" 2 "DataErratic" 1 "BelowNormalMostSevere" 0 "AboveNormalMostSevere" ;
VAL_ 3221225472 FailureModeIdentifier6 31 "NotAvailable" 30 "NotAvailable" 29 "NotAvailable" 28 "NotAvailable" 27 "NotAvailable" 26 "NotAvailable" 25 "NotAvailable" 24 "NotAvailable" 23 "NotAvailable" 22 "NotAvailable" 21 "NotAvailable" 20 "NotAvailable" 19 "ReceivedNetworkDataInError" 18 "BelowNormalModeratelySevere" 17 "BelowNormalLeastSevere" 16 "AboveNormalModeratelySevere" 15 "AboveNormalLeastSevere" 14 "SpecialIntstructions" 13 "OutOfCalibration" 12 "BadIntelligentDevice" 11 "RootCauseNotKnown" 10 "AbnormalRateOfChange" 9 "AbnormalUpdateRate" 8 "AbnormalFrequency" 7 "MechanicalSystemNotResponding" 6 "CurrentAboveNormal" 5 "CurrentBelowNormal" 4 "VoltageBelowNormal" 3 "VoltageAboveNormal" 2 "DataErratic" 1 "BelowNormalMostSevere" 0 "AboveNormalMostSevere" ;
VAL_ 3221225472 FailureModeIdentifier5 31 "NotAvailable" 30 "NotAvailable" 29 "NotAvailable" 28 "NotAvailable" 27 "NotAvailable" 26 "NotAvailable" 25 "NotAvailable" 24 "NotAvailable" 23 "NotAvailable" 22 "NotAvailable" 21 "NotAvailable" 20 "NotAvailable" 19 "ReceivedNetworkDataInError" 18 "BelowNormalModeratelySevere" 17 "BelowNormalLeastSevere" 16 "AboveNormalModeratelySevere" 15 "AboveNormalLeastSevere" 14 "SpecialIntstructions" 13 "OutOfCalibration" 12 "BadIntelligentDevice" 11 "RootCauseNotKnown" 10 "AbnormalRateOfChange" 9 "AbnormalUpdateRate" 8 "AbnormalFrequency" 7 "MechanicalSystemNotResponding" 6 "CurrentAboveNormal" 5 "CurrentBelowNormal" 4 "VoltageBelowNormal" 3 "VoltageAboveNormal" 2 "DataErratic" 1 "BelowNormalMostSevere" 0 "AboveNormalMostSevere" ;
VAL_ 3221225472 FailureModeIdentifier4 31 "NotAvailable" 30 "NotAvailable" 29 "NotAvailable" 28 "NotAvailable" 27 "NotAvailable" 26 "NotAvailable" 25 "NotAvailable" 24 "NotAvailable" 23 "NotAvailable" 22 "NotAvailable" 21 "NotAvailable" 20 "NotAvailable" 19 "ReceivedNetworkDataInError" 18 "BelowNormalModeratelySevere" 17 "BelowNormalLeastSevere" 16 "AboveNormalModeratelySevere" 15 "AboveNormalLeastSevere" 14 "SpecialIntstructions" 13 "OutOfCalibration" 12 "BadIntelligentDevice" 11 "RootCauseNotKnown" 10 "AbnormalRateOfChange" 9 "AbnormalUpdateRate" 8 "AbnormalFrequency" 7 "MechanicalSystemNotResponding" 6 "CurrentAboveNormal" 5 "CurrentBelowNormal" 4 "VoltageBelowNormal" 3 "VoltageAboveNormal" 2 "DataErratic" 1 "BelowNormalMostSevere" 0 "AboveNormalMostSevere" ;
VAL_ 3221225472 FailureModeIdentifier3 31 "NotAvailable" 30 "NotAvailable" 29 "NotAvailable" 28 "NotAvailable" 27 "NotAvailable" 26 "NotAvailable" 25 "NotAvailable" 24 "NotAvailable" 23 "NotAvailable" 22 "NotAvailable" 21 "NotAvailable" 20 "NotAvailable" 19 "ReceivedNetworkDataInError" 18 "BelowNormalModeratelySevere" 17 "BelowNormalLeastSevere" 16 "AboveNormalModeratelySevere" 15 "AboveNormalLeastSevere" 14 "SpecialIntstructions" 13 "OutOfCalibration" 12 "BadIntelligentDevice" 11 "RootCauseNotKnown" 10 "AbnormalRateOfChange" 9 "AbnormalUpdateRate" 8 "AbnormalFrequency" 7 "MechanicalSystemNotResponding" 6 "CurrentAboveNormal" 5 "CurrentBelowNormal" 4 "VoltageBelowNormal" 3 "VoltageAboveNormal" 2 "DataErratic" 1 "BelowNormalMostSevere" 0 "AboveNormalMostSevere" ;
VAL_ 3221225472 FlashRedStopLamp 3 "UnavailableDoNotFlash" 2 "Reserved" 1 "FastFlash" 0 "SlowFlash" ;
VAL_ 3221225472 FlashProtectLamp 3 "UnavailableDoNotFlash" 2 "Reserved" 1 "FastFlash" 0 "SlowFlash" ;
VAL_ 3221225472 FlashMalfuncIndicatorLamp 3 "UnavailableDoNotFlash" 2 "Reserved" 1 "FastFlash" 0 "SlowFlash" ;
VAL_ 3221225472 FlashAmberWarningLamp 3 "UnavailableDoNotFlash" 2 "Reserved" 1 "FastFlash" 0 "SlowFlash" ;
VAL_ 3221225472 MalfunctionIndicatorLampStatus 3 "NotAvailable" 2 "Reserved" 1 "LampOn" 0 "LampOff" ;
VAL_ 3221225472 AmberWarningLampStatus 3 "NotAvailable" 2 "Reserved" 1 "LampOn" 0 "LampOff" ;
VAL_ 3221225472 SPNConversionMethod1 1 "Version_1_2_3_format" 0 "Old_conversion_method" ;
VAL_ 3221225472 FailureModeIdentifier1 31 "NotAvailable" 30 "NotAvailable" 29 "NotAvailable" 28 "NotAvailable" 27 "NotAvailable" 26 "NotAvailable" 25 "NotAvailable" 24 "NotAvailable" 23 "NotAvailable" 22 "NotAvailable" 21 "NotAvailable" 20 "NotAvailable" 19 "ReceivedNetworkDataInError" 18 "BelowNormalModeratelySevere" 17 "BelowNormalLeastSevere" 16 "AboveNormalModeratelySevere" 15 "AboveNormalLeastSevere" 14 "SpecialIntstructions" 13 "OutOfCalibration" 12 "BadIntelligentDevice" 11 "RootCauseNotKnown" 10 "AbnormalRateOfChange" 9 "AbnormalUpdateRate" 8 "AbnormalFrequency" 7 "MechanicalSystemNotResponding" 6 "CurrentAboveNormal" 5 "CurrentBelowNormal" 4 "VoltageBelowNormal" 3 "VoltageAboveNormal" 2 "DataErratic" 1 "BelowNormalMostSevere" 0 "AboveNormalMostSevere" ;
VAL_ 3221225472 RedStopLampState 3 "NotAvailable" 2 "Reserved" 1 "LampOn" 0 "LampOff" ;
VAL_ 3221225472 ProtectLampStatus 3 "NotAvailable" 2 "Reserved" 1 "LampOn" 0 "LampOff" ;
VAL_ 3221225472 FailureModeIdentifier2 31 "NotAvailable" 30 "NotAvailable" 29 "NotAvailable" 28 "NotAvailable" 27 "NotAvailable" 26 "NotAvailable" 25 "NotAvailable" 24 "NotAvailable" 23 "NotAvailable" 22 "NotAvailable" 21 "NotAvailable" 20 "NotAvailable" 19 "ReceivedNetworkDataInError" 18 "BelowNormalModeratelySevere" 17 "BelowNormalLeastSevere" 16 "AboveNormalModeratelySevere" 15 "AboveNormalLeastSevere" 14 "SpecialIntstructions" 13 "OutOfCalibration" 12 "BadIntelligentDevice" 11 "RootCauseNotKnown" 10 "AbnormalRateOfChange" 9 "AbnormalUpdateRate" 8 "AbnormalFrequency" 7 "MechanicalSystemNotResponding" 6 "CurrentAboveNormal" 5 "CurrentBelowNormal" 4 "VoltageBelowNormal" 3 "VoltageAboveNormal" 2 "DataErratic" 1 "BelowNormalMostSevere" 0 "AboveNormalMostSevere" ;
VAL_ 3221225472 SPNConversionMethod10 1 "Version_1_2_3_format" 0 "Old_conversion_method" ;
VAL_ 3221225472 SPNConversionMethod9 1 "Version_1_2_3_format" 0 "Old_conversion_method" ;
VAL_ 3221225472 SPNConversionMethod8 1 "Version_1_2_3_format" 0 "Old_conversion_method" ;
VAL_ 3221225472 SPNConversionMethod7 1 "Version_1_2_3_format" 0 "Old_conversion_method" ;
VAL_ 3221225472 SPNConversionMethod6 1 "Version_1_2_3_format" 0 "Old_conversion_method" ;
VAL_ 3221225472 SPNConversionMethod5 1 "Version_1_2_3_format" 0 "Old_conversion_method" ;
VAL_ 3221225472 SPNConversionMethod4 1 "Version_1_2_3_format" 0 "Old_conversion_method" ;
VAL_ 3221225472 SPNConversionMethod3 1 "Version_1_2_3_format" 0 "Old_conversion_method" ;
VAL_ 3221225472 SPNConversionMethod2 1 "Version_1_2_3_format" 0 "Old_conversion_method" ;
VAL_ 2565603072 FailureModeIdentifier10 31 "NotAvailable" 30 "NotAvailable" 29 "NotAvailable" 28 "NotAvailable" 27 "NotAvailable" 26 "NotAvailable" 25 "NotAvailable" 24 "NotAvailable" 23 "NotAvailable" 22 "NotAvailable" 21 "NotAvailable" 20 "NotAvailable" 19 "ReceivedNetworkDataInError" 18 "BelowNormalModeratelySevere" 17 "BelowNormalLeastSevere" 16 "AboveNormalModeratelySevere" 15 "AboveNormalLeastSevere" 14 "SpecialIntstructions" 13 "OutOfCalibration" 12 "BadIntelligentDevice" 11 "RootCauseNotKnown" 10 "AbnormalRateOfChange" 9 "AbnormalUpdateRate" 8 "AbnormalFrequency" 7 "MechanicalSystemNotResponding" 6 "CurrentAboveNormal" 5 "CurrentBelowNormal" 4 "VoltageBelowNormal" 3 "VoltageAboveNormal" 2 "DataErratic" 1 "BelowNormalMostSevere" 0 "AboveNormalMostSevere" ;
VAL_ 2565603072 FailureModeIdentifier9 31 "NotAvailable" 30 "NotAvailable" 29 "NotAvailable" 28 "NotAvailable" 27 "NotAvailable" 26 "NotAvailable" 25 "NotAvailable" 24 "NotAvailable" 23 "NotAvailable" 22 "NotAvailable" 21 "NotAvailable" 20 "NotAvailable" 19 "ReceivedNetworkDataInError" 18 "BelowNormalModeratelySevere" 17 "BelowNormalLeastSevere" 16 "AboveNormalModeratelySevere" 15 "AboveNormalLeastSevere" 14 "SpecialIntstructions" 13 "OutOfCalibration" 12 "BadIntelligentDevice" 11 "RootCauseNotKnown" 10 "AbnormalRateOfChange" 9 "AbnormalUpdateRate" 8 "AbnormalFrequency" 7 "MechanicalSystemNotResponding" 6 "CurrentAboveNormal" 5 "CurrentBelowNormal" 4 "VoltageBelowNormal" 3 "VoltageAboveNormal" 2 "DataErratic" 1 "BelowNormalMostSevere" 0 "AboveNormalMostSevere" ;
VAL_ 2565603072 FailureModeIdentifier8 31 "NotAvailable" 30 "NotAvailable" 29 "NotAvailable" 28 "NotAvailable" 27 "NotAvailable" 26 "NotAvailable" 25 "NotAvailable" 24 "NotAvailable" 23 "NotAvailable" 22 "NotAvailable" 21 "NotAvailable" 20 "NotAvailable" 19 "ReceivedNetworkDataInError" 18 "BelowNormalModeratelySevere" 17 "BelowNormalLeastSevere" 16 "AboveNormalModeratelySevere" 15 "AboveNormalLeastSevere" 14 "SpecialIntstructions" 13 "OutOfCalibration" 12 "BadIntelligentDevice" 11 "RootCauseNotKnown" 10 "AbnormalRateOfChange" 9 "AbnormalUpdateRate" 8 "AbnormalFrequency" 7 "MechanicalSystemNotResponding" 6 "CurrentAboveNormal" 5 "CurrentBelowNormal" 4 "VoltageBelowNormal" 3 "VoltageAboveNormal" 2 "DataErratic" 1 "BelowNormalMostSevere" 0 "AboveNormalMostSevere" ;
VAL_ 2565603072 FailureModeIdentifier7 31 "NotAvailable" 30 "NotAvailable" 29 "NotAvailable" 28 "NotAvailable" 27 "NotAvailable" 26 "NotAvailable" 25 "NotAvailable" 24 "NotAvailable" 23 "NotAvailable" 22 "NotAvailable" 21 "NotAvailable" 20 "NotAvailable" 19 "ReceivedNetworkDataInError" 18 "BelowNormalModeratelySevere" 17 "BelowNormalLeastSevere" 16 "AboveNormalModeratelySevere" 15 "AboveNormalLeastSevere" 14 "SpecialIntstructions" 13 "OutOfCalibration" 12 "BadIntelligentDevice" 11 "RootCauseNotKnown" 10 "AbnormalRateOfChange" 9 "AbnormalUpdateRate" 8 "AbnormalFrequency" 7 "MechanicalSystemNotResponding" 6 "CurrentAboveNormal" 5 "CurrentBelowNormal" 4 "VoltageBelowNormal" 3 "VoltageAboveNormal" 2 "DataErratic" 1 "BelowNormalMostSevere" 0 "AboveNormalMostSevere" ;
VAL_ 2565603072 FailureModeIdentifier6 31 "NotAvailable" 30 "NotAvailable" 29 "NotAvailable" 28 "NotAvailable" 27 "NotAvailable" 26 "NotAvailable" 25 "NotAvailable" 24 "NotAvailable" 23 "NotAvailable" 22 "NotAvailable" 21 "NotAvailable" 20 "NotAvailable" 19 "ReceivedNetworkDataInError" 18 "BelowNormalModeratelySevere" 17 "BelowNormalLeastSevere" 16 "AboveNormalModeratelySevere" 15 "AboveNormalLeastSevere" 14 "SpecialIntstructions" 13 "OutOfCalibration" 12 "BadIntelligentDevice" 11 "RootCauseNotKnown" 10 "AbnormalRateOfChange" 9 "AbnormalUpdateRate" 8 "AbnormalFrequency" 7 "MechanicalSystemNotResponding" 6 "CurrentAboveNormal" 5 "CurrentBelowNormal" 4 "VoltageBelowNormal" 3 "VoltageAboveNormal" 2 "DataErratic" 1 "BelowNormalMostSevere" 0 "AboveNormalMostSevere" ;
VAL_ 2565603072 FailureModeIdentifier5 31 "NotAvailable" 30 "NotAvailable" 29 "NotAvailable" 28 "NotAvailable" 27 "NotAvailable" 26 "NotAvailable" 25 "NotAvailable" 24 "NotAvailable" 23 "NotAvailable" 22 "NotAvailable" 21 "NotAvailable" 20 "NotAvailable" 19 "ReceivedNetworkDataInError" 18 "BelowNormalModeratelySevere" 17 "BelowNormalLeastSevere" 16 "AboveNormalModeratelySevere" 15 "AboveNormalLeastSevere" 14 "SpecialIntstructions" 13 "OutOfCalibration" 12 "BadIntelligentDevice" 11 "RootCauseNotKnown" 10 "AbnormalRateOfChange" 9 "AbnormalUpdateRate" 8 "AbnormalFrequency" 7 "MechanicalSystemNotResponding" 6 "CurrentAboveNormal" 5 "CurrentBelowNormal" 4 "VoltageBelowNormal" 3 "VoltageAboveNormal" 2 "DataErratic" 1 "BelowNormalMostSevere" 0 "AboveNormalMostSevere" ;
VAL_ 2565603072 FailureModeIdentifier4 31 "NotAvailable" 30 "NotAvailable" 29 "NotAvailable" 28 "NotAvailable" 27 "NotAvailable" 26 "NotAvailable" 25 "NotAvailable" 24 "NotAvailable" 23 "NotAvailable" 22 "NotAvailable" 21 "NotAvailable" 20 "NotAvailable" 19 "ReceivedNetworkDataInError" 18 "BelowNormalModeratelySevere" 17 "BelowNormalLeastSevere" 16 "AboveNormalModeratelySevere" 15 "AboveNormalLeastSevere" 14 "SpecialIntstructions" 13 "OutOfCalibration" 12 "BadIntelligentDevice" 11 "RootCauseNotKnown" 10 "AbnormalRateOfChange" 9 "AbnormalUpdateRate" 8 "AbnormalFrequency" 7 "MechanicalSystemNotResponding" 6 "CurrentAboveNormal" 5 "CurrentBelowNormal" 4 "VoltageBelowNormal" 3 "VoltageAboveNormal" 2 "DataErratic" 1 "BelowNormalMostSevere" 0 "AboveNormalMostSevere" ;
VAL_ 2565603072 FailureModeIdentifier3 31 "NotAvailable" 30 "NotAvailable" 29 "NotAvailable" 28 "NotAvailable" 27 "NotAvailable" 26 "NotAvailable" 25 "NotAvailable" 24 "NotAvailable" 23 "NotAvailable" 22 "NotAvailable" 21 "NotAvailable" 20 "NotAvailable" 19 "ReceivedNetworkDataInError" 18 "BelowNormalModeratelySevere" 17 "BelowNormalLeastSevere" 16 "AboveNormalModeratelySevere" 15 "AboveNormalLeastSevere" 14 "SpecialIntstructions" 13 "OutOfCalibration" 12 "BadIntelligentDevice" 11 "RootCauseNotKnown" 10 "AbnormalRateOfChange" 9 "AbnormalUpdateRate" 8 "AbnormalFrequency" 7 "MechanicalSystemNotResponding" 6 "CurrentAboveNormal" 5 "CurrentBelowNormal" 4 "VoltageBelowNormal" 3 "VoltageAboveNormal" 2 "DataErratic" 1 "BelowNormalMostSevere" 0 "AboveNormalMostSevere" ;
VAL_ 2565603072 FlashRedStopLamp 3 "UnavailableDoNotFlash" 2 "Reserved" 1 "FastFlash" 0 "SlowFlash" ;
VAL_ 2565603072 FlashProtectLamp 3 "UnavailableDoNotFlash" 2 "Reserved" 1 "FastFlash" 0 "SlowFlash" ;
VAL_ 2565603072 FlashMalfuncIndicatorLamp 3 "UnavailableDoNotFlash" 2 "Reserved" 1 "FastFlash" 0 "SlowFlash" ;
VAL_ 2565603072 FlashAmberWarningLamp 3 "UnavailableDoNotFlash" 2 "Reserved" 1 "FastFlash" 0 "SlowFlash" ;
VAL_ 2565603072 MalfunctionIndicatorLampStatus 3 "NotAvailable" 2 "Reserved" 1 "LampOn" 0 "LampOff" ;
VAL_ 2565603072 AmberWarningLampStatus 3 "NotAvailable" 2 "Reserved" 1 "LampOn" 0 "LampOff" ;
VAL_ 2565603072 SPNConversionMethod1 1 "Version_1_2_3_format" 0 "Old_conversion_method" ;
VAL_ 2565603072 FailureModeIdentifier1 31 "NotAvailable" 30 "NotAvailable" 29 "NotAvailable" 28 "NotAvailable" 27 "NotAvailable" 26 "NotAvailable" 25 "NotAvailable" 24 "NotAvailable" 23 "NotAvailable" 22 "NotAvailable" 21 "NotAvailable" 20 "NotAvailable" 19 "ReceivedNetworkDataInError" 18 "BelowNormalModeratelySevere" 17 "BelowNormalLeastSevere" 16 "AboveNormalModeratelySevere" 15 "AboveNormalLeastSevere" 14 "SpecialIntstructions" 13 "OutOfCalibration" 12 "BadIntelligentDevice" 11 "RootCauseNotKnown" 10 "AbnormalRateOfChange" 9 "AbnormalUpdateRate" 8 "AbnormalFrequency" 7 "MechanicalSystemNotResponding" 6 "CurrentAboveNormal" 5 "CurrentBelowNormal" 4 "VoltageBelowNormal" 3 "VoltageAboveNormal" 2 "DataErratic" 1 "BelowNormalMostSevere" 0 "AboveNormalMostSevere" ;
VAL_ 2565603072 RedStopLampState 3 "NotAvailable" 2 "Reserved" 1 "LampOn" 0 "LampOff" ;
VAL_ 2565603072 ProtectLampStatus 3 "NotAvailable" 2 "Reserved" 1 "LampOn" 0 "LampOff" ;
VAL_ 2565603072 FailureModeIdentifier2 31 "NotAvailable" 30 "NotAvailable" 29 "NotAvailable" 28 "NotAvailable" 27 "NotAvailable" 26 "NotAvailable" 25 "NotAvailable" 24 "NotAvailable" 23 "NotAvailable" 22 "NotAvailable" 21 "NotAvailable" 20 "NotAvailable" 19 "ReceivedNetworkDataInError" 18 "BelowNormalModeratelySevere" 17 "BelowNormalLeastSevere" 16 "AboveNormalModeratelySevere" 15 "AboveNormalLeastSevere" 14 "SpecialIntstructions" 13 "OutOfCalibration" 12 "BadIntelligentDevice" 11 "RootCauseNotKnown" 10 "AbnormalRateOfChange" 9 "AbnormalUpdateRate" 8 "AbnormalFrequency" 7 "MechanicalSystemNotResponding" 6 "CurrentAboveNormal" 5 "CurrentBelowNormal" 4 "VoltageBelowNormal" 3 "VoltageAboveNormal" 2 "DataErratic" 1 "BelowNormalMostSevere" 0 "AboveNormalMostSevere" ;
VAL_ 2565603072 SPNConversionMethod10 1 "Version_1_2_3_format" 0 "Old_conversion_method" ;
VAL_ 2565603072 SPNConversionMethod9 1 "Version_1_2_3_format" 0 "Old_conversion_method" ;
VAL_ 2565603072 SPNConversionMethod8 1 "Version_1_2_3_format" 0 "Old_conversion_method" ;
VAL_ 2565603072 SPNConversionMethod7 1 "Version_1_2_3_format" 0 "Old_conversion_method" ;
VAL_ 2565603072 SPNConversionMethod6 1 "Version_1_2_3_format" 0 "Old_conversion_method" ;
VAL_ 2565603072 SPNConversionMethod5 1 "Version_1_2_3_format" 0 "Old_conversion_method" ;
VAL_ 2565603072 SPNConversionMethod4 1 "Version_1_2_3_format" 0 "Old_conversion_method" ;
VAL_ 2565603072 SPNConversionMethod3 1 "Version_1_2_3_format" 0 "Old_conversion_method" ;
VAL_ 2565603072 SPNConversionMethod2 1 "Version_1_2_3_format" 0 "Old_conversion_method" ;
VAL_ 2565603075 FailureModeIdentifier10 31 "NotAvailable" 30 "NotAvailable" 29 "NotAvailable" 28 "NotAvailable" 27 "NotAvailable" 26 "NotAvailable" 25 "NotAvailable" 24 "NotAvailable" 23 "NotAvailable" 22 "NotAvailable" 21 "NotAvailable" 20 "NotAvailable" 19 "ReceivedNetworkDataInError" 18 "BelowNormalModeratelySevere" 17 "BelowNormalLeastSevere" 16 "AboveNormalModeratelySevere" 15 "AboveNormalLeastSevere" 14 "SpecialIntstructions" 13 "OutOfCalibration" 12 "BadIntelligentDevice" 11 "RootCauseNotKnown" 10 "AbnormalRateOfChange" 9 "AbnormalUpdateRate" 8 "AbnormalFrequency" 7 "MechanicalSystemNotResponding" 6 "CurrentAboveNormal" 5 "CurrentBelowNormal" 4 "VoltageBelowNormal" 3 "VoltageAboveNormal" 2 "DataErratic" 1 "BelowNormalMostSevere" 0 "AboveNormalMostSevere" ;
VAL_ 2565603075 FailureModeIdentifier9 31 "NotAvailable" 30 "NotAvailable" 29 "NotAvailable" 28 "NotAvailable" 27 "NotAvailable" 26 "NotAvailable" 25 "NotAvailable" 24 "NotAvailable" 23 "NotAvailable" 22 "NotAvailable" 21 "NotAvailable" 20 "NotAvailable" 19 "ReceivedNetworkDataInError" 18 "BelowNormalModeratelySevere" 17 "BelowNormalLeastSevere" 16 "AboveNormalModeratelySevere" 15 "AboveNormalLeastSevere" 14 "SpecialIntstructions" 13 "OutOfCalibration" 12 "BadIntelligentDevice" 11 "RootCauseNotKnown" 10 "AbnormalRateOfChange" 9 "AbnormalUpdateRate" 8 "AbnormalFrequency" 7 "MechanicalSystemNotResponding" 6 "CurrentAboveNormal" 5 "CurrentBelowNormal" 4 "VoltageBelowNormal" 3 "VoltageAboveNormal" 2 "DataErratic" 1 "BelowNormalMostSevere" 0 "AboveNormalMostSevere" ;
VAL_ 2565603075 FailureModeIdentifier8 31 "NotAvailable" 30 "NotAvailable" 29 "NotAvailable" 28 "NotAvailable" 27 "NotAvailable" 26 "NotAvailable" 25 "NotAvailable" 24 "NotAvailable" 23 "NotAvailable" 22 "NotAvailable" 21 "NotAvailable" 20 "NotAvailable" 19 "ReceivedNetworkDataInError" 18 "BelowNormalModeratelySevere" 17 "BelowNormalLeastSevere" 16 "AboveNormalModeratelySevere" 15 "AboveNormalLeastSevere" 14 "SpecialIntstructions" 13 "OutOfCalibration" 12 "BadIntelligentDevice" 11 "RootCauseNotKnown" 10 "AbnormalRateOfChange" 9 "AbnormalUpdateRate" 8 "AbnormalFrequency" 7 "MechanicalSystemNotResponding" 6 "CurrentAboveNormal" 5 "CurrentBelowNormal" 4 "VoltageBelowNormal" 3 "VoltageAboveNormal" 2 "DataErratic" 1 "BelowNormalMostSevere" 0 "AboveNormalMostSevere" ;
VAL_ 2565603075 FailureModeIdentifier7 31 "NotAvailable" 30 "NotAvailable" 29 "NotAvailable" 28 "NotAvailable" 27 "NotAvailable" 26 "NotAvailable" 25 "NotAvailable" 24 "NotAvailable" 23 "NotAvailable" 22 "NotAvailable" 21 "NotAvailable" 20 "NotAvailable" 19 "ReceivedNetworkDataInError" 18 "BelowNormalModeratelySevere" 17 "BelowNormalLeastSevere" 16 "AboveNormalModeratelySevere" 15 "AboveNormalLeastSevere" 14 "SpecialIntstructions" 13 "OutOfCalibration" 12 "BadIntelligentDevice" 11 "RootCauseNotKnown" 10 "AbnormalRateOfChange" 9 "AbnormalUpdateRate" 8 "AbnormalFrequency" 7 "MechanicalSystemNotResponding" 6 "CurrentAboveNormal" 5 "CurrentBelowNormal" 4 "VoltageBelowNormal" 3 "VoltageAboveNormal" 2 "DataErratic" 1 "BelowNormalMostSevere" 0 "AboveNormalMostSevere" ;
VAL_ 2565603075 FailureModeIdentifier6 31 "NotAvailable" 30 "NotAvailable" 29 "NotAvailable" 28 "NotAvailable" 27 "NotAvailable" 26 "NotAvailable" 25 "NotAvailable" 24 "NotAvailable" 23 "NotAvailable" 22 "NotAvailable" 21 "NotAvailable" 20 "NotAvailable" 19 "ReceivedNetworkDataInError" 18 "BelowNormalModeratelySevere" 17 "BelowNormalLeastSevere" 16 "AboveNormalModeratelySevere" 15 "AboveNormalLeastSevere" 14 "SpecialIntstructions" 13 "OutOfCalibration" 12 "BadIntelligentDevice" 11 "RootCauseNotKnown" 10 "AbnormalRateOfChange" 9 "AbnormalUpdateRate" 8 "AbnormalFrequency" 7 "MechanicalSystemNotResponding" 6 "CurrentAboveNormal" 5 "CurrentBelowNormal" 4 "VoltageBelowNormal" 3 "VoltageAboveNormal" 2 "DataErratic" 1 "BelowNormalMostSevere" 0 "AboveNormalMostSevere" ;
VAL_ 2565603075 FailureModeIdentifier5 31 "NotAvailable" 30 "NotAvailable" 29 "NotAvailable" 28 "NotAvailable" 27 "NotAvailable" 26 "NotAvailable" 25 "NotAvailable" 24 "NotAvailable" 23 "NotAvailable" 22 "NotAvailable" 21 "NotAvailable" 20 "NotAvailable" 19 "ReceivedNetworkDataInError" 18 "BelowNormalModeratelySevere" 17 "BelowNormalLeastSevere" 16 "AboveNormalModeratelySevere" 15 "AboveNormalLeastSevere" 14 "SpecialIntstructions" 13 "OutOfCalibration" 12 "BadIntelligentDevice" 11 "RootCauseNotKnown" 10 "AbnormalRateOfChange" 9 "AbnormalUpdateRate" 8 "AbnormalFrequency" 7 "MechanicalSystemNotResponding" 6 "CurrentAboveNormal" 5 "CurrentBelowNormal" 4 "VoltageBelowNormal" 3 "VoltageAboveNormal" 2 "DataErratic" 1 "BelowNormalMostSevere" 0 "AboveNormalMostSevere" ;
VAL_ 2565603075 FailureModeIdentifier4 31 "NotAvailable" 30 "NotAvailable" 29 "NotAvailable" 28 "NotAvailable" 27 "NotAvailable" 26 "NotAvailable" 25 "NotAvailable" 24 "NotAvailable" 23 "NotAvailable" 22 "NotAvailable" 21 "NotAvailable" 20 "NotAvailable" 19 "ReceivedNetworkDataInError" 18 "BelowNormalModeratelySevere" 17 "BelowNormalLeastSevere" 16 "AboveNormalModeratelySevere" 15 "AboveNormalLeastSevere" 14 "SpecialIntstructions" 13 "OutOfCalibration" 12 "BadIntelligentDevice" 11 "RootCauseNotKnown" 10 "AbnormalRateOfChange" 9 "AbnormalUpdateRate" 8 "AbnormalFrequency" 7 "MechanicalSystemNotResponding" 6 "CurrentAboveNormal" 5 "CurrentBelowNormal" 4 "VoltageBelowNormal" 3 "VoltageAboveNormal" 2 "DataErratic" 1 "BelowNormalMostSevere" 0 "AboveNormalMostSevere" ;
VAL_ 2565603075 FailureModeIdentifier3 31 "NotAvailable" 30 "NotAvailable" 29 "NotAvailable" 28 "NotAvailable" 27 "NotAvailable" 26 "NotAvailable" 25 "NotAvailable" 24 "NotAvailable" 23 "NotAvailable" 22 "NotAvailable" 21 "NotAvailable" 20 "NotAvailable" 19 "ReceivedNetworkDataInError" 18 "BelowNormalModeratelySevere" 17 "BelowNormalLeastSevere" 16 "AboveNormalModeratelySevere" 15 "AboveNormalLeastSevere" 14 "SpecialIntstructions" 13 "OutOfCalibration" 12 "BadIntelligentDevice" 11 "RootCauseNotKnown" 10 "AbnormalRateOfChange" 9 "AbnormalUpdateRate" 8 "AbnormalFrequency" 7 "MechanicalSystemNotResponding" 6 "CurrentAboveNormal" 5 "CurrentBelowNormal" 4 "VoltageBelowNormal" 3 "VoltageAboveNormal" 2 "DataErratic" 1 "BelowNormalMostSevere" 0 "AboveNormalMostSevere" ;
VAL_ 2565603075 FlashRedStopLamp 3 "UnavailableDoNotFlash" 2 "Reserved" 1 "FastFlash" 0 "SlowFlash" ;
VAL_ 2565603075 FlashProtectLamp 3 "UnavailableDoNotFlash" 2 "Reserved" 1 "FastFlash" 0 "SlowFlash" ;
VAL_ 2565603075 FlashMalfuncIndicatorLamp 3 "UnavailableDoNotFlash" 2 "Reserved" 1 "FastFlash" 0 "SlowFlash" ;
VAL_ 2565603075 FlashAmberWarningLamp 3 "UnavailableDoNotFlash" 2 "Reserved" 1 "FastFlash" 0 "SlowFlash" ;
VAL_ 2565603075 MalfunctionIndicatorLampStatus 3 "NotAvailable" 2 "Reserved" 1 "LampOn" 0 "LampOff" ;
VAL_ 2565603075 AmberWarningLampStatus 3 "NotAvailable" 2 "Reserved" 1 "LampOn" 0 "LampOff" ;
VAL_ 2565603075 SPNConversionMethod1 1 "Version_1_2_3_format" 0 "Old_conversion_method" ;
VAL_ 2565603075 FailureModeIdentifier1 31 "NotAvailable" 30 "NotAvailable" 29 "NotAvailable" 28 "NotAvailable" 27 "NotAvailable" 26 "NotAvailable" 25 "NotAvailable" 24 "NotAvailable" 23 "NotAvailable" 22 "NotAvailable" 21 "NotAvailable" 20 "NotAvailable" 19 "ReceivedNetworkDataInError" 18 "BelowNormalModeratelySevere" 17 "BelowNormalLeastSevere" 16 "AboveNormalModeratelySevere" 15 "AboveNormalLeastSevere" 14 "SpecialIntstructions" 13 "OutOfCalibration" 12 "BadIntelligentDevice" 11 "RootCauseNotKnown" 10 "AbnormalRateOfChange" 9 "AbnormalUpdateRate" 8 "AbnormalFrequency" 7 "MechanicalSystemNotResponding" 6 "CurrentAboveNormal" 5 "CurrentBelowNormal" 4 "VoltageBelowNormal" 3 "VoltageAboveNormal" 2 "DataErratic" 1 "BelowNormalMostSevere" 0 "AboveNormalMostSevere" ;
VAL_ 2565603075 RedStopLampState 3 "NotAvailable" 2 "Reserved" 1 "LampOn" 0 "LampOff" ;
VAL_ 2565603075 ProtectLampStatus 3 "NotAvailable" 2 "Reserved" 1 "LampOn" 0 "LampOff" ;
VAL_ 2565603075 FailureModeIdentifier2 31 "NotAvailable" 30 "NotAvailable" 29 "NotAvailable" 28 "NotAvailable" 27 "NotAvailable" 26 "NotAvailable" 25 "NotAvailable" 24 "NotAvailable" 23 "NotAvailable" 22 "NotAvailable" 21 "NotAvailable" 20 "NotAvailable" 19 "ReceivedNetworkDataInError" 18 "BelowNormalModeratelySevere" 17 "BelowNormalLeastSevere" 16 "AboveNormalModeratelySevere" 15 "AboveNormalLeastSevere" 14 "SpecialIntstructions" 13 "OutOfCalibration" 12 "BadIntelligentDevice" 11 "RootCauseNotKnown" 10 "AbnormalRateOfChange" 9 "AbnormalUpdateRate" 8 "AbnormalFrequency" 7 "MechanicalSystemNotResponding" 6 "CurrentAboveNormal" 5 "CurrentBelowNormal" 4 "VoltageBelowNormal" 3 "VoltageAboveNormal" 2 "DataErratic" 1 "BelowNormalMostSevere" 0 "AboveNormalMostSevere" ;
VAL_ 2565603075 SPNConversionMethod10 1 "Version_1_2_3_format" 0 "Old_conversion_method" ;
VAL_ 2565603075 SPNConversionMethod9 1 "Version_1_2_3_format" 0 "Old_conversion_method" ;
VAL_ 2565603075 SPNConversionMethod8 1 "Version_1_2_3_format" 0 "Old_conversion_method" ;
VAL_ 2565603075 SPNConversionMethod7 1 "Version_1_2_3_format" 0 "Old_conversion_method" ;
VAL_ 2565603075 SPNConversionMethod6 1 "Version_1_2_3_format" 0 "Old_conversion_method" ;
VAL_ 2565603075 SPNConversionMethod5 1 "Version_1_2_3_format" 0 "Old_conversion_method" ;
VAL_ 2565603075 SPNConversionMethod4 1 "Version_1_2_3_format" 0 "Old_conversion_method" ;
VAL_ 2565603075 SPNConversionMethod3 1 "Version_1_2_3_format" 0 "Old_conversion_method" ;
VAL_ 2565603075 SPNConversionMethod2 1 "Version_1_2_3_format" 0 "Old_conversion_method" ;
VAL_ 2566834691 FailureModeIdentifier10 31 "NotAvailable" 30 "NotAvailable" 29 "NotAvailable" 28 "NotAvailable" 27 "NotAvailable" 26 "NotAvailable" 25 "NotAvailable" 24 "NotAvailable" 23 "NotAvailable" 22 "NotAvailable" 21 "NotAvailable" 20 "NotAvailable" 19 "ReceivedNetworkDataInError" 18 "BelowNormalModeratelySevere" 17 "BelowNormalLeastSevere" 16 "AboveNormalModeratelySevere" 15 "AboveNormalLeastSevere" 14 "SpecialIntstructions" 13 "OutOfCalibration" 12 "BadIntelligentDevice" 11 "RootCauseNotKnown" 10 "AbnormalRateOfChange" 9 "AbnormalUpdateRate" 8 "AbnormalFrequency" 7 "MechanicalSystemNotResponding" 6 "CurrentAboveNormal" 5 "CurrentBelowNormal" 4 "VoltageBelowNormal" 3 "VoltageAboveNormal" 2 "DataErratic" 1 "BelowNormalMostSevere" 0 "AboveNormalMostSevere" ;
VAL_ 2566834691 FailureModeIdentifier9 31 "NotAvailable" 30 "NotAvailable" 29 "NotAvailable" 28 "NotAvailable" 27 "NotAvailable" 26 "NotAvailable" 25 "NotAvailable" 24 "NotAvailable" 23 "NotAvailable" 22 "NotAvailable" 21 "NotAvailable" 20 "NotAvailable" 19 "ReceivedNetworkDataInError" 18 "BelowNormalModeratelySevere" 17 "BelowNormalLeastSevere" 16 "AboveNormalModeratelySevere" 15 "AboveNormalLeastSevere" 14 "SpecialIntstructions" 13 "OutOfCalibration" 12 "BadIntelligentDevice" 11 "RootCauseNotKnown" 10 "AbnormalRateOfChange" 9 "AbnormalUpdateRate" 8 "AbnormalFrequency" 7 "MechanicalSystemNotResponding" 6 "CurrentAboveNormal" 5 "CurrentBelowNormal" 4 "VoltageBelowNormal" 3 "VoltageAboveNormal" 2 "DataErratic" 1 "BelowNormalMostSevere" 0 "AboveNormalMostSevere" ;
VAL_ 2566834691 FailureModeIdentifier8 31 "NotAvailable" 30 "NotAvailable" 29 "NotAvailable" 28 "NotAvailable" 27 "NotAvailable" 26 "NotAvailable" 25 "NotAvailable" 24 "NotAvailable" 23 "NotAvailable" 22 "NotAvailable" 21 "NotAvailable" 20 "NotAvailable" 19 "ReceivedNetworkDataInError" 18 "BelowNormalModeratelySevere" 17 "BelowNormalLeastSevere" 16 "AboveNormalModeratelySevere" 15 "AboveNormalLeastSevere" 14 "SpecialIntstructions" 13 "OutOfCalibration" 12 "BadIntelligentDevice" 11 "RootCauseNotKnown" 10 "AbnormalRateOfChange" 9 "AbnormalUpdateRate" 8 "AbnormalFrequency" 7 "MechanicalSystemNotResponding" 6 "CurrentAboveNormal" 5 "CurrentBelowNormal" 4 "VoltageBelowNormal" 3 "VoltageAboveNormal" 2 "DataErratic" 1 "BelowNormalMostSevere" 0 "AboveNormalMostSevere" ;
VAL_ 2566834691 FailureModeIdentifier7 31 "NotAvailable" 30 "NotAvailable" 29 "NotAvailable" 28 "NotAvailable" 27 "NotAvailable" 26 "NotAvailable" 25 "NotAvailable" 24 "NotAvailable" 23 "NotAvailable" 22 "NotAvailable" 21 "NotAvailable" 20 "NotAvailable" 19 "ReceivedNetworkDataInError" 18 "BelowNormalModeratelySevere" 17 "BelowNormalLeastSevere" 16 "AboveNormalModeratelySevere" 15 "AboveNormalLeastSevere" 14 "SpecialIntstructions" 13 "OutOfCalibration" 12 "BadIntelligentDevice" 11 "RootCauseNotKnown" 10 "AbnormalRateOfChange" 9 "AbnormalUpdateRate" 8 "AbnormalFrequency" 7 "MechanicalSystemNotResponding" 6 "CurrentAboveNormal" 5 "CurrentBelowNormal" 4 "VoltageBelowNormal" 3 "VoltageAboveNormal" 2 "DataErratic" 1 "BelowNormalMostSevere" 0 "AboveNormalMostSevere" ;
VAL_ 2566834691 FailureModeIdentifier6 31 "NotAvailable" 30 "NotAvailable" 29 "NotAvailable" 28 "NotAvailable" 27 "NotAvailable" 26 "NotAvailable" 25 "NotAvailable" 24 "NotAvailable" 23 "NotAvailable" 22 "NotAvailable" 21 "NotAvailable" 20 "NotAvailable" 19 "ReceivedNetworkDataInError" 18 "BelowNormalModeratelySevere" 17 "BelowNormalLeastSevere" 16 "AboveNormalModeratelySevere" 15 "AboveNormalLeastSevere" 14 "SpecialIntstructions" 13 "OutOfCalibration" 12 "BadIntelligentDevice" 11 "RootCauseNotKnown" 10 "AbnormalRateOfChange" 9 "AbnormalUpdateRate" 8 "AbnormalFrequency" 7 "MechanicalSystemNotResponding" 6 "CurrentAboveNormal" 5 "CurrentBelowNormal" 4 "VoltageBelowNormal" 3 "VoltageAboveNormal" 2 "DataErratic" 1 "BelowNormalMostSevere" 0 "AboveNormalMostSevere" ;
VAL_ 2566834691 FailureModeIdentifier5 31 "NotAvailable" 30 "NotAvailable" 29 "NotAvailable" 28 "NotAvailable" 27 "NotAvailable" 26 "NotAvailable" 25 "NotAvailable" 24 "NotAvailable" 23 "NotAvailable" 22 "NotAvailable" 21 "NotAvailable" 20 "NotAvailable" 19 "ReceivedNetworkDataInError" 18 "BelowNormalModeratelySevere" 17 "BelowNormalLeastSevere" 16 "AboveNormalModeratelySevere" 15 "AboveNormalLeastSevere" 14 "SpecialIntstructions" 13 "OutOfCalibration" 12 "BadIntelligentDevice" 11 "RootCauseNotKnown" 10 "AbnormalRateOfChange" 9 "AbnormalUpdateRate" 8 "AbnormalFrequency" 7 "MechanicalSystemNotResponding" 6 "CurrentAboveNormal" 5 "CurrentBelowNormal" 4 "VoltageBelowNormal" 3 "VoltageAboveNormal" 2 "DataErratic" 1 "BelowNormalMostSevere" 0 "AboveNormalMostSevere" ;
VAL_ 2566834691 FailureModeIdentifier4 31 "NotAvailable" 30 "NotAvailable" 29 "NotAvailable" 28 "NotAvailable" 27 "NotAvailable" 26 "NotAvailable" 25 "NotAvailable" 24 "NotAvailable" 23 "NotAvailable" 22 "NotAvailable" 21 "NotAvailable" 20 "NotAvailable" 19 "ReceivedNetworkDataInError" 18 "BelowNormalModeratelySevere" 17 "BelowNormalLeastSevere" 16 "AboveNormalModeratelySevere" 15 "AboveNormalLeastSevere" 14 "SpecialIntstructions" 13 "OutOfCalibration" 12 "BadIntelligentDevice" 11 "RootCauseNotKnown" 10 "AbnormalRateOfChange" 9 "AbnormalUpdateRate" 8 "AbnormalFrequency" 7 "MechanicalSystemNotResponding" 6 "CurrentAboveNormal" 5 "CurrentBelowNormal" 4 "VoltageBelowNormal" 3 "VoltageAboveNormal" 2 "DataErratic" 1 "BelowNormalMostSevere" 0 "AboveNormalMostSevere" ;
VAL_ 2566834691 FailureModeIdentifier3 31 "NotAvailable" 30 "NotAvailable" 29 "NotAvailable" 28 "NotAvailable" 27 "NotAvailable" 26 "NotAvailable" 25 "NotAvailable" 24 "NotAvailable" 23 "NotAvailable" 22 "NotAvailable" 21 "NotAvailable" 20 "NotAvailable" 19 "ReceivedNetworkDataInError" 18 "BelowNormalModeratelySevere" 17 "BelowNormalLeastSevere" 16 "AboveNormalModeratelySevere" 15 "AboveNormalLeastSevere" 14 "SpecialIntstructions" 13 "OutOfCalibration" 12 "BadIntelligentDevice" 11 "RootCauseNotKnown" 10 "AbnormalRateOfChange" 9 "AbnormalUpdateRate" 8 "AbnormalFrequency" 7 "MechanicalSystemNotResponding" 6 "CurrentAboveNormal" 5 "CurrentBelowNormal" 4 "VoltageBelowNormal" 3 "VoltageAboveNormal" 2 "DataErratic" 1 "BelowNormalMostSevere" 0 "AboveNormalMostSevere" ;
VAL_ 2566834691 FlashRedStopLamp 3 "UnavailableDoNotFlash" 2 "Reserved" 1 "FastFlash" 0 "SlowFlash" ;
VAL_ 2566834691 FlashProtectLamp 3 "UnavailableDoNotFlash" 2 "Reserved" 1 "FastFlash" 0 "SlowFlash" ;
VAL_ 2566834691 FlashMalfuncIndicatorLamp 3 "UnavailableDoNotFlash" 2 "Reserved" 1 "FastFlash" 0 "SlowFlash" ;
VAL_ 2566834691 FlashAmberWarningLamp 3 "UnavailableDoNotFlash" 2 "Reserved" 1 "FastFlash" 0 "SlowFlash" ;
VAL_ 2566834691 MalfunctionIndicatorLampStatus 3 "NotAvailable" 2 "Reserved" 1 "LampOn" 0 "LampOff" ;
VAL_ 2566834691 AmberWarningLampStatus 3 "NotAvailable" 2 "Reserved" 1 "LampOn" 0 "LampOff" ;
VAL_ 2566834691 SPNConversionMethod1 1 "Version_1_2_3_format" 0 "Old_conversion_method" ;
VAL_ 2566834691 FailureModeIdentifier1 31 "NotAvailable" 30 "NotAvailable" 29 "NotAvailable" 28 "NotAvailable" 27 "NotAvailable" 26 "NotAvailable" 25 "NotAvailable" 24 "NotAvailable" 23 "NotAvailable" 22 "NotAvailable" 21 "NotAvailable" 20 "NotAvailable" 19 "ReceivedNetworkDataInError" 18 "BelowNormalModeratelySevere" 17 "BelowNormalLeastSevere" 16 "AboveNormalModeratelySevere" 15 "AboveNormalLeastSevere" 14 "SpecialIntstructions" 13 "OutOfCalibration" 12 "BadIntelligentDevice" 11 "RootCauseNotKnown" 10 "AbnormalRateOfChange" 9 "AbnormalUpdateRate" 8 "AbnormalFrequency" 7 "MechanicalSystemNotResponding" 6 "CurrentAboveNormal" 5 "CurrentBelowNormal" 4 "VoltageBelowNormal" 3 "VoltageAboveNormal" 2 "DataErratic" 1 "BelowNormalMostSevere" 0 "AboveNormalMostSevere" ;
VAL_ 2566834691 RedStopLampState 3 "NotAvailable" 2 "Reserved" 1 "LampOn" 0 "LampOff" ;
VAL_ 2566834691 ProtectLampStatus 3 "NotAvailable" 2 "Reserved" 1 "LampOn" 0 "LampOff" ;
VAL_ 2566834691 FailureModeIdentifier2 31 "NotAvailable" 30 "NotAvailable" 29 "NotAvailable" 28 "NotAvailable" 27 "NotAvailable" 26 "NotAvailable" 25 "NotAvailable" 24 "NotAvailable" 23 "NotAvailable" 22 "NotAvailable" 21 "NotAvailable" 20 "NotAvailable" 19 "ReceivedNetworkDataInError" 18 "BelowNormalModeratelySevere" 17 "BelowNormalLeastSevere" 16 "AboveNormalModeratelySevere" 15 "AboveNormalLeastSevere" 14 "SpecialIntstructions" 13 "OutOfCalibration" 12 "BadIntelligentDevice" 11 "RootCauseNotKnown" 10 "AbnormalRateOfChange" 9 "AbnormalUpdateRate" 8 "AbnormalFrequency" 7 "MechanicalSystemNotResponding" 6 "CurrentAboveNormal" 5 "CurrentBelowNormal" 4 "VoltageBelowNormal" 3 "VoltageAboveNormal" 2 "DataErratic" 1 "BelowNormalMostSevere" 0 "AboveNormalMostSevere" ;
VAL_ 2566834691 SPNConversionMethod10 1 "Version_1_2_3_format" 0 "Old_conversion_method" ;
VAL_ 2566834691 SPNConversionMethod9 1 "Version_1_2_3_format" 0 "Old_conversion_method" ;
VAL_ 2566834691 SPNConversionMethod8 1 "Version_1_2_3_format" 0 "Old_conversion_method" ;
VAL_ 2566834691 SPNConversionMethod7 1 "Version_1_2_3_format" 0 "Old_conversion_method" ;
VAL_ 2566834691 SPNConversionMethod6 1 "Version_1_2_3_format" 0 "Old_conversion_method" ;
VAL_ 2566834691 SPNConversionMethod5 1 "Version_1_2_3_format" 0 "Old_conversion_method" ;
VAL_ 2566834691 SPNConversionMethod4 1 "Version_1_2_3_format" 0 "Old_conversion_method" ;
VAL_ 2566834691 SPNConversionMethod3 1 "Version_1_2_3_format" 0 "Old_conversion_method" ;
VAL_ 2566834691 SPNConversionMethod2 1 "Version_1_2_3_format" 0 "Old_conversion_method" ;
VAL_ 2566834688 FailureModeIdentifier10 31 "NotAvailable" 30 "NotAvailable" 29 "NotAvailable" 28 "NotAvailable" 27 "NotAvailable" 26 "NotAvailable" 25 "NotAvailable" 24 "NotAvailable" 23 "NotAvailable" 22 "NotAvailable" 21 "NotAvailable" 20 "NotAvailable" 19 "ReceivedNetworkDataInError" 18 "BelowNormalModeratelySevere" 17 "BelowNormalLeastSevere" 16 "AboveNormalModeratelySevere" 15 "AboveNormalLeastSevere" 14 "SpecialIntstructions" 13 "OutOfCalibration" 12 "BadIntelligentDevice" 11 "RootCauseNotKnown" 10 "AbnormalRateOfChange" 9 "AbnormalUpdateRate" 8 "AbnormalFrequency" 7 "MechanicalSystemNotResponding" 6 "CurrentAboveNormal" 5 "CurrentBelowNormal" 4 "VoltageBelowNormal" 3 "VoltageAboveNormal" 2 "DataErratic" 1 "BelowNormalMostSevere" 0 "AboveNormalMostSevere" ;
VAL_ 2566834688 FailureModeIdentifier9 31 "NotAvailable" 30 "NotAvailable" 29 "NotAvailable" 28 "NotAvailable" 27 "NotAvailable" 26 "NotAvailable" 25 "NotAvailable" 24 "NotAvailable" 23 "NotAvailable" 22 "NotAvailable" 21 "NotAvailable" 20 "NotAvailable" 19 "ReceivedNetworkDataInError" 18 "BelowNormalModeratelySevere" 17 "BelowNormalLeastSevere" 16 "AboveNormalModeratelySevere" 15 "AboveNormalLeastSevere" 14 "SpecialIntstructions" 13 "OutOfCalibration" 12 "BadIntelligentDevice" 11 "RootCauseNotKnown" 10 "AbnormalRateOfChange" 9 "AbnormalUpdateRate" 8 "AbnormalFrequency" 7 "MechanicalSystemNotResponding" 6 "CurrentAboveNormal" 5 "CurrentBelowNormal" 4 "VoltageBelowNormal" 3 "VoltageAboveNormal" 2 "DataErratic" 1 "BelowNormalMostSevere" 0 "AboveNormalMostSevere" ;
VAL_ 2566834688 FailureModeIdentifier8 31 "NotAvailable" 30 "NotAvailable" 29 "NotAvailable" 28 "NotAvailable" 27 "NotAvailable" 26 "NotAvailable" 25 "NotAvailable" 24 "NotAvailable" 23 "NotAvailable" 22 "NotAvailable" 21 "NotAvailable" 20 "NotAvailable" 19 "ReceivedNetworkDataInError" 18 "BelowNormalModeratelySevere" 17 "BelowNormalLeastSevere" 16 "AboveNormalModeratelySevere" 15 "AboveNormalLeastSevere" 14 "SpecialIntstructions" 13 "OutOfCalibration" 12 "BadIntelligentDevice" 11 "RootCauseNotKnown" 10 "AbnormalRateOfChange" 9 "AbnormalUpdateRate" 8 "AbnormalFrequency" 7 "MechanicalSystemNotResponding" 6 "CurrentAboveNormal" 5 "CurrentBelowNormal" 4 "VoltageBelowNormal" 3 "VoltageAboveNormal" 2 "DataErratic" 1 "BelowNormalMostSevere" 0 "AboveNormalMostSevere" ;
VAL_ 2566834688 FailureModeIdentifier7 31 "NotAvailable" 30 "NotAvailable" 29 "NotAvailable" 28 "NotAvailable" 27 "NotAvailable" 26 "NotAvailable" 25 "NotAvailable" 24 "NotAvailable" 23 "NotAvailable" 22 "NotAvailable" 21 "NotAvailable" 20 "NotAvailable" 19 "ReceivedNetworkDataInError" 18 "BelowNormalModeratelySevere" 17 "BelowNormalLeastSevere" 16 "AboveNormalModeratelySevere" 15 "AboveNormalLeastSevere" 14 "SpecialIntstructions" 13 "OutOfCalibration" 12 "BadIntelligentDevice" 11 "RootCauseNotKnown" 10 "AbnormalRateOfChange" 9 "AbnormalUpdateRate" 8 "AbnormalFrequency" 7 "MechanicalSystemNotResponding" 6 "CurrentAboveNormal" 5 "CurrentBelowNormal" 4 "VoltageBelowNormal" 3 "VoltageAboveNormal" 2 "DataErratic" 1 "BelowNormalMostSevere" 0 "AboveNormalMostSevere" ;
VAL_ 2566834688 FailureModeIdentifier6 31 "NotAvailable" 30 "NotAvailable" 29 "NotAvailable" 28 "NotAvailable" 27 "NotAvailable" 26 "NotAvailable" 25 "NotAvailable" 24 "NotAvailable" 23 "NotAvailable" 22 "NotAvailable" 21 "NotAvailable" 20 "NotAvailable" 19 "ReceivedNetworkDataInError" 18 "BelowNormalModeratelySevere" 17 "BelowNormalLeastSevere" 16 "AboveNormalModeratelySevere" 15 "AboveNormalLeastSevere" 14 "SpecialIntstructions" 13 "OutOfCalibration" 12 "BadIntelligentDevice" 11 "RootCauseNotKnown" 10 "AbnormalRateOfChange" 9 "AbnormalUpdateRate" 8 "AbnormalFrequency" 7 "MechanicalSystemNotResponding" 6 "CurrentAboveNormal" 5 "CurrentBelowNormal" 4 "VoltageBelowNormal" 3 "VoltageAboveNormal" 2 "DataErratic" 1 "BelowNormalMostSevere" 0 "AboveNormalMostSevere" ;
VAL_ 2566834688 FailureModeIdentifier5 31 "NotAvailable" 30 "NotAvailable" 29 "NotAvailable" 28 "NotAvailable" 27 "NotAvailable" 26 "NotAvailable" 25 "NotAvailable" 24 "NotAvailable" 23 "NotAvailable" 22 "NotAvailable" 21 "NotAvailable" 20 "NotAvailable" 19 "ReceivedNetworkDataInError" 18 "BelowNormalModeratelySevere" 17 "BelowNormalLeastSevere" 16 "AboveNormalModeratelySevere" 15 "AboveNormalLeastSevere" 14 "SpecialIntstructions" 13 "OutOfCalibration" 12 "BadIntelligentDevice" 11 "RootCauseNotKnown" 10 "AbnormalRateOfChange" 9 "AbnormalUpdateRate" 8 "AbnormalFrequency" 7 "MechanicalSystemNotResponding" 6 "CurrentAboveNormal" 5 "CurrentBelowNormal" 4 "VoltageBelowNormal" 3 "VoltageAboveNormal" 2 "DataErratic" 1 "BelowNormalMostSevere" 0 "AboveNormalMostSevere" ;
VAL_ 2566834688 FailureModeIdentifier4 31 "NotAvailable" 30 "NotAvailable" 29 "NotAvailable" 28 "NotAvailable" 27 "NotAvailable" 26 "NotAvailable" 25 "NotAvailable" 24 "NotAvailable" 23 "NotAvailable" 22 "NotAvailable" 21 "NotAvailable" 20 "NotAvailable" 19 "ReceivedNetworkDataInError" 18 "BelowNormalModeratelySevere" 17 "BelowNormalLeastSevere" 16 "AboveNormalModeratelySevere" 15 "AboveNormalLeastSevere" 14 "SpecialIntstructions" 13 "OutOfCalibration" 12 "BadIntelligentDevice" 11 "RootCauseNotKnown" 10 "AbnormalRateOfChange" 9 "AbnormalUpdateRate" 8 "AbnormalFrequency" 7 "MechanicalSystemNotResponding" 6 "CurrentAboveNormal" 5 "CurrentBelowNormal" 4 "VoltageBelowNormal" 3 "VoltageAboveNormal" 2 "DataErratic" 1 "BelowNormalMostSevere" 0 "AboveNormalMostSevere" ;
VAL_ 2566834688 FailureModeIdentifier3 31 "NotAvailable" 30 "NotAvailable" 29 "NotAvailable" 28 "NotAvailable" 27 "NotAvailable" 26 "NotAvailable" 25 "NotAvailable" 24 "NotAvailable" 23 "NotAvailable" 22 "NotAvailable" 21 "NotAvailable" 20 "NotAvailable" 19 "ReceivedNetworkDataInError" 18 "BelowNormalModeratelySevere" 17 "BelowNormalLeastSevere" 16 "AboveNormalModeratelySevere" 15 "AboveNormalLeastSevere" 14 "SpecialIntstructions" 13 "OutOfCalibration" 12 "BadIntelligentDevice" 11 "RootCauseNotKnown" 10 "AbnormalRateOfChange" 9 "AbnormalUpdateRate" 8 "AbnormalFrequency" 7 "MechanicalSystemNotResponding" 6 "CurrentAboveNormal" 5 "CurrentBelowNormal" 4 "VoltageBelowNormal" 3 "VoltageAboveNormal" 2 "DataErratic" 1 "BelowNormalMostSevere" 0 "AboveNormalMostSevere" ;
VAL_ 2566834688 FlashRedStopLamp 3 "UnavailableDoNotFlash" 2 "Reserved" 1 "FastFlash" 0 "SlowFlash" ;
VAL_ 2566834688 FlashProtectLamp 3 "UnavailableDoNotFlash" 2 "Reserved" 1 "FastFlash" 0 "SlowFlash" ;
VAL_ 2566834688 FlashMalfuncIndicatorLamp 3 "UnavailableDoNotFlash" 2 "Reserved" 1 "FastFlash" 0 "SlowFlash" ;
VAL_ 2566834688 FlashAmberWarningLamp 3 "UnavailableDoNotFlash" 2 "Reserved" 1 "FastFlash" 0 "SlowFlash" ;
VAL_ 2566834688 MalfunctionIndicatorLampStatus 3 "NotAvailable" 2 "Reserved" 1 "LampOn" 0 "LampOff" ;
VAL_ 2566834688 AmberWarningLampStatus 3 "NotAvailable" 2 "Reserved" 1 "LampOn" 0 "LampOff" ;
VAL_ 2566834688 SPNConversionMethod1 1 "Version_1_2_3_format" 0 "Old_conversion_method" ;
VAL_ 2566834688 FailureModeIdentifier1 31 "NotAvailable" 30 "NotAvailable" 29 "NotAvailable" 28 "NotAvailable" 27 "NotAvailable" 26 "NotAvailable" 25 "NotAvailable" 24 "NotAvailable" 23 "NotAvailable" 22 "NotAvailable" 21 "NotAvailable" 20 "NotAvailable" 19 "ReceivedNetworkDataInError" 18 "BelowNormalModeratelySevere" 17 "BelowNormalLeastSevere" 16 "AboveNormalModeratelySevere" 15 "AboveNormalLeastSevere" 14 "SpecialIntstructions" 13 "OutOfCalibration" 12 "BadIntelligentDevice" 11 "RootCauseNotKnown" 10 "AbnormalRateOfChange" 9 "AbnormalUpdateRate" 8 "AbnormalFrequency" 7 "MechanicalSystemNotResponding" 6 "CurrentAboveNormal" 5 "CurrentBelowNormal" 4 "VoltageBelowNormal" 3 "VoltageAboveNormal" 2 "DataErratic" 1 "BelowNormalMostSevere" 0 "AboveNormalMostSevere" ;
VAL_ 2566834688 RedStopLampState 3 "NotAvailable" 2 "Reserved" 1 "LampOn" 0 "LampOff" ;
VAL_ 2566834688 ProtectLampStatus 3 "NotAvailable" 2 "Reserved" 1 "LampOn" 0 "LampOff" ;
VAL_ 2566834688 FailureModeIdentifier2 31 "NotAvailable" 30 "NotAvailable" 29 "NotAvailable" 28 "NotAvailable" 27 "NotAvailable" 26 "NotAvailable" 25 "NotAvailable" 24 "NotAvailable" 23 "NotAvailable" 22 "NotAvailable" 21 "NotAvailable" 20 "NotAvailable" 19 "ReceivedNetworkDataInError" 18 "BelowNormalModeratelySevere" 17 "BelowNormalLeastSevere" 16 "AboveNormalModeratelySevere" 15 "AboveNormalLeastSevere" 14 "SpecialIntstructions" 13 "OutOfCalibration" 12 "BadIntelligentDevice" 11 "RootCauseNotKnown" 10 "AbnormalRateOfChange" 9 "AbnormalUpdateRate" 8 "AbnormalFrequency" 7 "MechanicalSystemNotResponding" 6 "CurrentAboveNormal" 5 "CurrentBelowNormal" 4 "VoltageBelowNormal" 3 "VoltageAboveNormal" 2 "DataErratic" 1 "BelowNormalMostSevere" 0 "AboveNormalMostSevere" ;
VAL_ 2566834688 SPNConversionMethod10 1 "Version_1_2_3_format" 0 "Old_conversion_method" ;
VAL_ 2566834688 SPNConversionMethod9 1 "Version_1_2_3_format" 0 "Old_conversion_method" ;
VAL_ 2566834688 SPNConversionMethod8 1 "Version_1_2_3_format" 0 "Old_conversion_method" ;
VAL_ 2566834688 SPNConversionMethod7 1 "Version_1_2_3_format" 0 "Old_conversion_method" ;
VAL_ 2566834688 SPNConversionMethod6 1 "Version_1_2_3_format" 0 "Old_conversion_method" ;
VAL_ 2566834688 SPNConversionMethod5 1 "Version_1_2_3_format" 0 "Old_conversion_method" ;
VAL_ 2566834688 SPNConversionMethod4 1 "Version_1_2_3_format" 0 "Old_conversion_method" ;
VAL_ 2566834688 SPNConversionMethod3 1 "Version_1_2_3_format" 0 "Old_conversion_method" ;
VAL_ 2566834688 SPNConversionMethod2 1 "Version_1_2_3_format" 0 "Old_conversion_method" ;
VAL_ 2566899994 Alt_BatteryTypeLocation 4 "6TMF_outside_ENG_compartment" 3 "6TMF_in_ENG_compartment" 2 "Hawker_outside_ENG_compartment" 1 "Hawker_in_ENG_compartment" ;
VAL_ 2348814375 EngineRequestedTq_HR_TSC1_VDR 15 "N/A" 14 "N/A" 13 "N/A" 12 "N/A" 11 "N/A" 10 "N/A" 9 "N/A" 8 "N/A" 7 "Additional_torque__+_0.875%" 6 "Additional_torque__+_0.750%" 5 "Additional_torque__+_0.625%" 4 "Additional_torque__+_0.500%" 3 "Additional_torque__+_0.375%" 2 "Additional_torque__+_0.250%" 1 "Additional_torque__+_0.125%" 0 "Additional_torque__+_0.000%" ;
VAL_ 2348814375 ControlPurpose_TSC1_VDR 5 "TemporaryPowerTrainControl" 4 "EngineProtection" 3 "RoadSpeedGovernor" 2 "PTOGovernor" 1 "CruiseControl" 0 "AcceleratorPedal" ;
VAL_ 2348814375 TransmissionRate_TSC1_VDR 7 "UseStandardRate" 6 "25ms" 5 "50ms" 4 "100ms" 3 "250ms" 2 "500ms" 1 "750ms" 0 "1000ms" ;
VAL_ 2348814375 OverrideCtrlModPriority_TSC1_VDR 3 "LowPriority" 2 "MdmPrrtyUsdFrPwrtrnCtrlOprtnsWh" 1 "HighPriority" 0 "HghstPrrtyUsdFrSttnsThtRqrImmdt" ;
VAL_ 2348814375 EngRqedSpeedCtrlCondit_TSC1_VDR 2 "ThsCtrlCndtnHsBnOptmzdTMnmzRpmO" 3 "StbltyOptmzdFrDrvlnEnggdAnd_OrI" 1 "StbltyOptmzdFrDrvlnDsnggdAndNnl" 0 "ThsSpdGvrnrGnSlctnIsAdjstdTPrvd" ;
VAL_ 2348814375 EngOverrideCtrlMode_TSC1_VDR 3 "Spd_TrqLmtCtrlLmtSpdAnd_OrTrqBs" 2 "TrqCtrlCntrlTrqTInclddDsrdTrqVl" 1 "SpdCtrlGvrnSpdTInclddDsrdSpdVle" 0 "OvrrdDsbldDsblAnyExstngCtrlCmdd" ;
VAL_ 2566810949 HeaterWaterTemperature 255 "NOT_AVAILABLE" 254 "ERROR" ;
VAL_ 2566810949 Heater_Input_Air_Temperature 255 "NOT_AVAILABLE" 254 "ERROR" ;
VAL_ 2566810949 Heater_Output_Power_Percent 255 "NOT_AVAILABLE" 254 "ERROR" ;
VAL_ 2566810949 Heater_Mode 15 "NOT_AVAILABLE" 14 "ERROR" 3 "NORMAL_MODE" 2 "ECONOMY_MODE" 1 "OFF_due_to_ADR" 0 "HEATER_NOT_ACTIVE" ;
VAL_ 2566810949 Heater_coolant_pump_state 3 "NOT_AVAILABLE" 2 "ERROR" 1 "RUNNING" 0 "NOT_RUNNING" ;
VAL_ 2566810949 Cab_ventilation 3 "NOT_AVAILABLE" 2 "ERROR" 1 "VENTILATED" 0 "NOT_VENTILATED" ;
VAL_ 2566810949 Engine_Heating_Zone 3 "NOT_AVAILABLE" 2 "ERROR" 1 "HEATED" 0 "NOT_HEATED" ;
VAL_ 2566810949 Cab_Heating_Zone 3 "NOT_AVAILABLE" 2 "ERROR" 1 "HEATED" 0 "NOT_HEATED" ;
VAL_ 2558590749 AFSS_Zone_Fault0 3 "NOT_AVAILABLE" 2 "RESERVED" 1 "ZONA_NON_IN_SICUREZZA" 0 "ZONA_IN_SICUREZZA" ;
VAL_ 2558590749 AFSS_Zone_Fault1 3 "NOT_AVAILABLE" 2 "RESERVED" 1 "ZONA_NON_IN_SICUREZZA" 0 "ZONA_IN_SICUREZZA" ;
VAL_ 2558590749 AFSS_Zone_Fault2 3 "NOT_AVAILABLE" 2 "RESERVED" 1 "ZONA_NON_IN_SICUREZZA" 0 "ZONA_IN_SICUREZZA" ;
VAL_ 2558590749 AFSS_Zone_Fault3 3 "NOT_AVAILABLE" 2 "RESERVED" 1 "ZONA_NON_IN_SICUREZZA" 0 "ZONA_IN_SICUREZZA" ;
VAL_ 2558590749 AFSS_Zone_Fire_Alarm0 3 "NOT_AVAILABLE" 2 "RESERVED" 1 "ZONA_ATTIVATA" 0 "ZONA_NON_ATTIVATA" ;
VAL_ 2558590749 AFSS_Zone_Fire_Alarm1 3 "NOT_AVAILABLE" 2 "RESERVED" 1 "ZONA_ATTIVATA" 0 "ZONA_NON_ATTIVATA" ;
VAL_ 2558590749 AFSS_Zone_Fire_Alarm2 3 "NOT_AVAILABLE" 2 "RESERVED" 1 "ZONA_ATTIVATA" 0 "ZONA_NON_ATTIVATA" ;
VAL_ 2558590749 AFSS_Zone_Fire_Alarm3 3 "NOT_AVAILABLE" 2 "RESERVED" 1 "ZONA_ATTIVATA" 0 "ZONA_NON_ATTIVATA" ;
VAL_ 2558590749 AFSS_Voltage_Fault 15 "NOT_AVAILABLE" 14 "RESERVED" 13 "RESERVED" 12 "RESERVED" 11 "RESERVED" 10 "RESERVED" 9 "RESERVED" 8 "RESERVED" 7 "RESERVED" 6 "RESERVED" 5 "LOCKOUT" 4 "HIGH_VOLTAGE" 3 "NORMAL" 2 "LOW_VOLTAGE" 1 "LOCKOUT" 0 "IDLE" ;
VAL_ 2558590749 AFSS_Internal_Fault 15 "NOT_AVAILABLE" 14 "OTHER_ERROR" 13 "OTHER_ERROR" 12 "OTHER_ERROR" 11 "OTHER_ERROR" 10 "OTHER_ERROR" 9 "OTHER_ERROR" 8 "OTHER_ERROR" 7 "OTHER_ERROR" 6 "EEPROM_FAULT" 5 "OTHER_ERROR" 4 "OTHER_ERROR" 3 "OTHER_ERROR" 2 "EEPROM_FAULT" 1 "RS485_DOWN" 0 "NO_FAULT" ;
VAL_ 2558590749 AFSS_Config_Error 3 "NOT_AVAILABLE" 2 "ERRORE_CONFIGURAZIONE" 1 "CONFIGURAZIONE_OK" 0 "CONFIGURAZIONE_NON_PRESENTE" ;
VAL_ 2558590749 AFSS_Zone_inhibited 3 "NOT_AVAILABLE" 2 "ZONA_INIBITA_DA_SCARICA" 1 "ZONA_INIBITA" 0 "NESSUNA_SEGNALAZIONE" ;
VAL_ 2558590749 AFSS_Self_Test 3 "NOT_AVAILABLE" 2 "INIZIALIZZAZIONE_IN_CORSO" 1 "TEST_IN_CORSO" 0 "NO_TEST" ;
VAL_ 2558590749 AFSS_ContrOut0 3 "NOT_AVAILABLE" 2 "RESERVED" 1 "ON" 0 "OFF" ;
VAL_ 2558590749 AFSS_ContrOut1 3 "NOT_AVAILABLE" 2 "RESERVED" 1 "ON" 0 "OFF" ;
VAL_ 2558590749 AFSS_ContrOut2 3 "NOT_AVAILABLE" 2 "RESERVED" 1 "ON" 0 "OFF" ;
VAL_ 2558590749 AFSS_ContrOut3 3 "NOT_AVAILABLE" 2 "RESERVED" 1 "ON" 0 "OFF" ;
VAL_ 2558590749 AFSS_ContrOut4 3 "NOT_AVAILABLE" 2 "RESERVED" 1 "ON" 0 "OFF" ;
VAL_ 2558590749 AFSS_ContrOut5 3 "NOT_AVAILABLE" 2 "RESERVED" 1 "ON" 0 "OFF" ;
VAL_ 2558590749 AFSS_ContrOut6 3 "NOT_AVAILABLE" 2 "RESERVED" 1 "ON" 0 "OFF" ;
VAL_ 2558590749 AFSS_ContrOut7 3 "NOT_AVAILABLE" 2 "RESERVED" 1 "ON" 0 "OFF" ;
VAL_ 2558590749 AFSS_ExtInp0 3 "NOT_AVAILABLE" 2 "RESERVED" 1 "ON" 0 "OFF" ;
VAL_ 2558590749 AFSS_ExtInp1 3 "NOT_AVAILABLE" 2 "RESERVED" 1 "ON" 0 "OFF" ;
VAL_ 2558590749 AFSS_ExtInp2 3 "NOT_AVAILABLE" 2 "RESERVED" 1 "ON" 0 "OFF" ;
VAL_ 2558590749 AFSS_ExtInp3 3 "NOT_AVAILABLE" 2 "RESERVED" 1 "ON" 0 "OFF" ;
VAL_ 2558590749 AFSS_ExtInp4 3 "NOT_AVAILABLE" 2 "RESERVED" 1 "ON" 0 "OFF" ;
VAL_ 2558590749 AFSS_ExtInp5 3 "NOT_AVAILABLE" 2 "RESERVED" 1 "ON" 0 "OFF" ;
VAL_ 2558590749 AFSS_ExtInp6 3 "NOT_AVAILABLE" 2 "RESERVED" 1 "ON" 0 "OFF" ;
VAL_ 2558590749 AFSS_ExtInp7 3 "NOT_AVAILABLE" 2 "RESERVED" 1 "ON" 0 "OFF" ;
VAL_ 2558590749 AFSS_NotUsed 1 "NOT_USED" 0 "NOT_USED" ;
VAL_ 2558656285 AFSS_Est7_Status 15 "NOT_AVAILABLE" 14 "NOT_USED" 13 "NOT_USED" 12 "NOT_USED" 11 "NOT_USED" 10 "NOT_USED" 9 "NOT_USED" 8 "SCOLLEGATO" 7 "NOT_USED" 6 "NOT_USED" 5 "NOT_USED" 4 "NOT_USED" 3 "SCARICA_FALLITA" 2 "COLLEGATO_SCARICO_X_AUTOSCARICA" 1 "COLLEGATO_SCARICO_X_SCARICA" 0 "COLLEGATO_CARICO" ;
VAL_ 2558656285 AFSS_Est6_Status 15 "NOT_AVAILABLE" 14 "NOT_USED" 13 "NOT_USED" 12 "NOT_USED" 11 "NOT_USED" 10 "NOT_USED" 9 "NOT_USED" 8 "SCOLLEGATO" 7 "NOT_USED" 6 "NOT_USED" 5 "NOT_USED" 4 "NOT_USED" 3 "SCARICA_FALLITA" 2 "COLLEGATO_SCARICO_X_AUTOSCARICA" 1 "COLLEGATO_SCARICO_X_SCARICA" 0 "COLLEGATO_CARICO" ;
VAL_ 2558656285 AFSS_Est5_Status 15 "NOT_AVAILABLE" 14 "NOT_USED" 13 "NOT_USED" 12 "NOT_USED" 11 "NOT_USED" 10 "NOT_USED" 9 "NOT_USED" 8 "SCOLLEGATO" 7 "NOT_USED" 6 "NOT_USED" 5 "NOT_USED" 4 "NOT_USED" 3 "SCARICA_FALLITA" 2 "COLLEGATO_SCARICO_X_AUTOSCARICA" 1 "COLLEGATO_SCARICO_X_SCARICA" 0 "COLLEGATO_CARICO" ;
VAL_ 2558656285 AFSS_Est4_Status 15 "NOT_AVAILABLE" 14 "NOT_USED" 13 "NOT_USED" 12 "NOT_USED" 11 "NOT_USED" 10 "NOT_USED" 9 "NOT_USED" 8 "SCOLLEGATO" 7 "NOT_USED" 6 "NOT_USED" 5 "NOT_USED" 4 "NOT_USED" 3 "SCARICA_FALLITA" 2 "COLLEGATO_SCARICO_X_AUTOSCARICA" 1 "COLLEGATO_SCARICO_X_SCARICA" 0 "COLLEGATO_CARICO" ;
VAL_ 2558656285 AFSS_Est3_Status 15 "NOT_AVAILABLE" 14 "NOT_USED" 13 "NOT_USED" 12 "NOT_USED" 11 "NOT_USED" 10 "NOT_USED" 9 "NOT_USED" 8 "SCOLLEGATO" 7 "NOT_USED" 6 "NOT_USED" 5 "NOT_USED" 4 "NOT_USED" 3 "SCARICA_FALLITA" 2 "COLLEGATO_SCARICO_X_AUTOSCARICA" 1 "COLLEGATO_SCARICO_X_SCARICA" 0 "COLLEGATO_CARICO" ;
VAL_ 2558656285 AFSS_Est2_Status 15 "NOT_AVAILABLE" 14 "NOT_USED" 13 "NOT_USED" 12 "NOT_USED" 11 "NOT_USED" 10 "NOT_USED" 9 "NOT_USED" 8 "SCOLLEGATO" 7 "NOT_USED" 6 "NOT_USED" 5 "NOT_USED" 4 "NOT_USED" 3 "SCARICA_FALLITA" 2 "COLLEGATO_SCARICO_X_AUTOSCARICA" 1 "COLLEGATO_SCARICO_X_SCARICA" 0 "COLLEGATO_CARICO" ;
VAL_ 2558656285 AFSS_Est1_Status 15 "NOT_AVAILABLE" 14 "NOT_USED" 13 "NOT_USED" 12 "NOT_USED" 11 "NOT_USED" 10 "NOT_USED" 9 "NOT_USED" 8 "SCOLLEGATO" 7 "NOT_USED" 6 "NOT_USED" 5 "NOT_USED" 4 "NOT_USED" 3 "SCARICA_FALLITA" 2 "COLLEGATO_SCARICO_X_AUTOSCARICA" 1 "COLLEGATO_SCARICO_X_SCARICA" 0 "COLLEGATO_CARICO" ;
VAL_ 2558656285 AFSS_Est0_Status 15 "NOT_AVAILABLE" 14 "NOT_USED" 13 "NOT_USED" 12 "NOT_USED" 11 "NOT_USED" 10 "NOT_USED" 9 "NOT_USED" 8 "SCOLLEGATO" 7 "NOT_USED" 6 "NOT_USED" 5 "NOT_USED" 4 "NOT_USED" 3 "SCARICA_FALLITA" 2 "COLLEGATO_SCARICO_X_AUTOSCARICA" 1 "COLLEGATO_SCARICO_X_SCARICA" 0 "COLLEGATO_CARICO" ;
VAL_ 2558656285 AFSS_Sens7_Status 15 "NOT_AVAILABLE" 14 "NOT_VALID" 13 "NOT_VALID" 12 "NOT_VALID" 11 "NOT_VALID" 10 "NOT_VALID" 9 "NOT_VALID" 8 "SENSORE_SCOLLEGATO" 7 "NOT_VALID" 6 "NOT_VALID" 5 "NOT_VALID" 4 "NOT_VALID" 3 "NOT_VALID" 2 "SELF_CHECK_FAILED" 1 "SENSORE_ATTIVATO" 0 "SENSORE_OK" ;
VAL_ 2558656285 AFSS_Sens6_Status 15 "NOT_AVAILABLE" 14 "NOT_VALID" 13 "NOT_VALID" 12 "NOT_VALID" 11 "NOT_VALID" 10 "NOT_VALID" 9 "NOT_VALID" 8 "SENSORE_SCOLLEGATO" 7 "NOT_VALID" 6 "NOT_VALID" 5 "NOT_VALID" 4 "NOT_VALID" 3 "NOT_VALID" 2 "SELF_CHECK_FAILED" 1 "SENSORE_ATTIVATO" 0 "SENSORE_OK" ;
VAL_ 2558656285 AFSS_Sens5_Status 15 "NOT_AVAILABLE" 14 "NOT_VALID" 13 "NOT_VALID" 12 "NOT_VALID" 11 "NOT_VALID" 10 "NOT_VALID" 9 "NOT_VALID" 8 "SENSORE_SCOLLEGATO" 7 "NOT_VALID" 6 "NOT_VALID" 5 "NOT_VALID" 4 "NOT_VALID" 3 "NOT_VALID" 2 "SELF_CHECK_FAILED" 1 "SENSORE_ATTIVATO" 0 "SENSORE_OK" ;
VAL_ 2558656285 AFSS_Sens4_Status 15 "NOT_AVAILABLE" 14 "NOT_VALID" 13 "NOT_VALID" 12 "NOT_VALID" 11 "NOT_VALID" 10 "NOT_VALID" 9 "NOT_VALID" 8 "SENSORE_SCOLLEGATO" 7 "NOT_VALID" 6 "NOT_VALID" 5 "NOT_VALID" 4 "NOT_VALID" 3 "NOT_VALID" 2 "SELF_CHECK_FAILED" 1 "SENSORE_ATTIVATO" 0 "SENSORE_OK" ;
VAL_ 2558656285 AFSS_Sens3_Status 15 "NOT_AVAILABLE" 14 "NOT_VALID" 13 "NOT_VALID" 12 "NOT_VALID" 11 "NOT_VALID" 10 "NOT_VALID" 9 "NOT_VALID" 8 "SENSORE_SCOLLEGATO" 7 "NOT_VALID" 6 "NOT_VALID" 5 "NOT_VALID" 4 "NOT_VALID" 3 "NOT_VALID" 2 "SELF_CHECK_FAILED" 1 "SENSORE_ATTIVATO" 0 "SENSORE_OK" ;
VAL_ 2558656285 AFSS_Sens2_Status 15 "NOT_AVAILABLE" 14 "NOT_VALID" 13 "NOT_VALID" 12 "NOT_VALID" 11 "NOT_VALID" 10 "NOT_VALID" 9 "NOT_VALID" 8 "SENSORE_SCOLLEGATO" 7 "NOT_VALID" 6 "NOT_VALID" 5 "NOT_VALID" 4 "NOT_VALID" 3 "NOT_VALID" 2 "SELF_CHECK_FAILED" 1 "SENSORE_ATTIVATO" 0 "SENSORE_OK" ;
VAL_ 2558656285 AFSS_Sens1_Status 15 "NOT_AVAILABLE" 14 "NOT_VALID" 13 "NOT_VALID" 12 "NOT_VALID" 11 "NOT_VALID" 10 "NOT_VALID" 9 "NOT_VALID" 8 "SENSORE_SCOLLEGATO" 7 "NOT_VALID" 6 "NOT_VALID" 5 "NOT_VALID" 4 "NOT_VALID" 3 "NOT_VALID" 2 "SELF_CHECK_FAILED" 1 "SENSORE_ATTIVATO" 0 "SENSORE_OK" ;
VAL_ 2558656285 AFSS_Sens0_Status 15 "NOT_AVAILABLE" 14 "NOT_VALID" 13 "NOT_VALID" 12 "NOT_VALID" 11 "NOT_VALID" 10 "NOT_VALID" 9 "NOT_VALID" 8 "SENSORE_SCOLLEGATO" 7 "NOT_VALID" 6 "NOT_VALID" 5 "NOT_VALID" 4 "NOT_VALID" 3 "NOT_VALID" 2 "SELF_CHECK_FAILED" 1 "SENSORE_ATTIVATO" 0 "SENSORE_OK" ;
VAL_ 2364474627 ADM1_Ctrl 3 "NotAvailable" 2 "Error" 1 "Active" 0 "Inactive" ;
VAL_ 2364474627 ADM2_Ctrl 3 "NotAvailable" 2 "Error" 1 "Active" 0 "Inactive" ;
VAL_ 2364474627 ADM3_Ctrl 3 "NotAvailable" 2 "Error" 1 "Active" 0 "Inactive" ;
VAL_ 2364474627 ADM4_Ctrl 3 "NotAvailable" 2 "Error" 1 "Active" 0 "Inactive" ;
VAL_ 2364474627 ADP1_Ctrl 3 "NotAvailable" 2 "Error" 1 "Active" 0 "Inactive" ;
VAL_ 2364474627 ADP2_Ctrl 3 "NotAvailable" 2 "Error" 1 "Active" 0 "Inactive" ;
VAL_ 2364474627 ADP3_Ctrl 3 "NotAvailable" 2 "Error" 1 "Active" 0 "Inactive" ;
VAL_ 2364474627 ADP4_Ctrl 3 "NotAvailable" 2 "Error" 1 "Active" 0 "Inactive" ;
VAL_ 2364474627 EDM1_Ctrl 3 "NotAvailable" 2 "Error" 1 "Active" 0 "Inactive" ;
VAL_ 2364474627 EDM2_Ctrl 3 "NotAvailable" 2 "Error" 1 "Active" 0 "Inactive" ;
VAL_ 2364474627 EDP3_Ctrl 3 "NotAvailable" 2 "Error" 1 "Active" 0 "Inactive" ;
VAL_ 2364474627 EDP4_Ctrl 3 "NotAvailable" 2 "Error" 1 "Active" 0 "Inactive" ;
VAL_ 2364474627 AVP_Lever_Interlock_Ctrl 3 "NotAvailable" 2 "Error" 1 "Active" 0 "Inactive" ;
